VERSION ""

NS_ :

BS_:

BU_: Bat1 OpticalSensor EMUS_BMS SCIMO_PE TelemetryNode Master SensorF SensorR BrakeF BrakeR PDU HVCU HVTU TestBench MDB1 MDB2 MDB3 MDB4 MDB5 MDB6 Track CLU

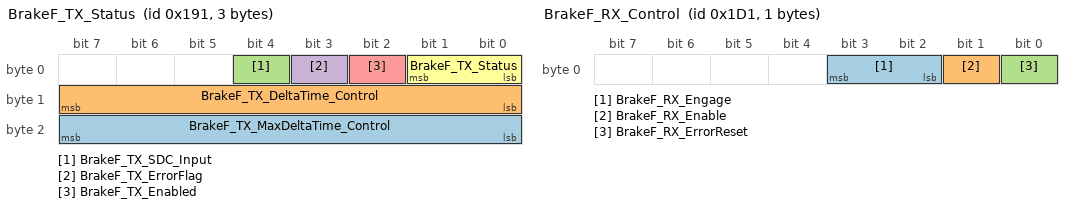
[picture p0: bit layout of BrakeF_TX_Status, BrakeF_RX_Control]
BO_ 401 BrakeF_TX_Status: 3 BrakeF
 SG_ BrakeF_TX_MaxDeltaTime_Control : 16|8@1+ (1,0) [0|255] "ms" Vector__XXX
 SG_ BrakeF_TX_DeltaTime_Control : 8|8@1+ (1,0) [0|255] "ms" Vector__XXX
 SG_ BrakeF_TX_SDC_Input : 4|1@1+ (1,0) [0|0] "" Vector__XXX
 SG_ BrakeF_TX_ErrorFlag : 3|1@1+ (1,0) [0|0] ""  SensorF
 SG_ BrakeF_TX_Enabled : 2|1@1+ (1,0) [0|0] ""  SensorF
 SG_ BrakeF_TX_Status : 0|2@1+ (1,0) [0|0] ""  SensorF

BO_ 465 BrakeF_RX_Control: 1 SensorF
 SG_ BrakeF_RX_Engage : 2|2@1+ (1,0) [0|0] "" Vector__XXX
 SG_ BrakeF_RX_Enable : 1|1@1+ (1,0) [0|0] "" Vector__XXX
 SG_ BrakeF_RX_ErrorReset : 0|1@1+ (1,0) [0|0] "" Vector__XXX

BO_ 529 BrakeF_TX_PDO2: 0 BrakeF

BO_ 593 BrakeF_RX_PDO2: 0 Vector__XXX

BO_ 657 BrakeF_TX_PDO3: 0 BrakeF

BO_ 721 BrakeF_RX_PDO3: 0 Vector__XXX

BO_ 785 BrakeF_TX_PDO4: 0 BrakeF

BO_ 849 BrakeF_RX_PDO4: 0 Vector__XXX

BO_ 913 BrakeF_TX_PDO5: 0 BrakeF

BO_ 977 BrakeF_TX_PDO6: 0 BrakeF

BO_ 1105 BrakeF_TX_PDO8: 0 BrakeF

BO_ 1169 BrakeF_TX_PDO9: 0 BrakeF

BO_ 1233 BrakeF_TX_PDO10: 0 BrakeF

BO_ 1297 BrakeF_TX_PDO11: 0 BrakeF

BO_ 1361 BrakeF_TX_PDO12: 0 BrakeF

BO_ 1425 BrakeF_SDO_Resp: 8 BrakeF
 SG_ BrakeF_OD_BrakeStatus m2304 : 16|8@1+ (1,0) [0|255] ""  TelemetryNode
 SG_ BrakeF_OD_CoolingPressure m2816 : 16|16@1+ (0.01,-100) [-100|555.35] ""  TelemetryNode
 SG_ BrakeF_OD_valveUpperTolerance m2053 : 16|16@1+ (0.005,0) [0|327.675] "bar"  TelemetryNode
 SG_ BrakeF_OD_commWatchdog m2052 : 16|16@1+ (1,0) [0|65535] "ms"  TelemetryNode
 SG_ BrakeF_OD_counterLimit m2051 : 16|8@1+ (1,0) [0|255] ""  TelemetryNode
 SG_ BrakeF_OD_delay m2050 : 16|8@1+ (0.5,0) [0|127.5] "ms"  TelemetryNode
 SG_ BrakeF_OD_tankUpperControlLimit m2049 : 16|16@1+ (0.005,0) [0|327.675] "bar"  TelemetryNode
 SG_ BrakeF_OD_tankLowerControlLimit m2048 : 16|16@1+ (0.005,0) [0|327.675] "bar"  TelemetryNode
 SG_ BrakeF_OD_CAN2_DelayedTxMessages m1129 : 16|24@1+ (1,0) [0|16777215] ""  TelemetryNode
 SG_ BrakeF_OD_CAN2_ErrorStatus m1128 : 16|8@1+ (1,0) [0|255] ""  TelemetryNode
 SG_ BrakeF_OD_CAN2_DiscardedTxMessag m1127 : 16|24@1+ (1,0) [0|16777215] ""  TelemetryNode
 SG_ BrakeF_OD_CAN2_Status m1126 : 16|8@1+ (1,0) [0|255] ""  TelemetryNode
 SG_ BrakeF_OD_CAN2_Baudrate m1124 : 16|16@1+ (1,0) [125|1000] "kbps"  TelemetryNode
 SG_ BrakeF_OD_CAN2_autoErrorReset m1123 : 16|8@1+ (1,0) [0|255] ""  TelemetryNode
 SG_ BrakeF_OD_CAN2_lastErrorCode m1122 : 16|32@1+ (1,0) [0|4294967295] ""  TelemetryNode
 SG_ BrakeF_OD_CAN2_RxErrCnt m1121 : 16|8@1+ (1,0) [0|255] ""  TelemetryNode
 SG_ BrakeF_OD_CAN2_TxErrCnt m1120 : 16|8@1+ (1,0) [0|255] ""  TelemetryNode
 SG_ BrakeF_OD_CAN1_DelayedTxMessages m1113 : 16|24@1+ (1,0) [0|16777215] ""  TelemetryNode
 SG_ BrakeF_OD_CAN1_ErrorStatus m1112 : 16|8@1+ (1,0) [0|255] ""  TelemetryNode
 SG_ BrakeF_OD_CAN1_DiscardedTxMessag m1111 : 16|24@1+ (1,0) [0|16777215] ""  TelemetryNode
 SG_ BrakeF_OD_CAN1_Status m1110 : 16|8@1+ (1,0) [0|255] ""  TelemetryNode
 SG_ BrakeF_OD_CAN1_Baudrate m1108 : 16|16@1+ (1,0) [125|1000] "kbps"  TelemetryNode
 SG_ BrakeF_OD_CAN1_autoErrorReset m1107 : 16|8@1+ (1,0) [0|255] ""  TelemetryNode
 SG_ BrakeF_OD_CAN1_lastErrorCode m1106 : 16|32@1+ (1,0) [0|4294967295] ""  TelemetryNode
 SG_ BrakeF_OD_CAN1_RxErrCnt m1105 : 16|8@1+ (1,0) [0|255] ""  TelemetryNode
 SG_ BrakeF_OD_CAN1_TxErrCnt m1104 : 16|8@1+ (1,0) [0|255] ""  TelemetryNode
 SG_ BrakeF_OD_BuildTime m1073 : 16|24@1+ (1,0) [0|16777215] ""  TelemetryNode
 SG_ BrakeF_OD_BuildDate m1072 : 16|32@1+ (1,0) [0|4294967295] ""  TelemetryNode
 SG_ BrakeF_OD_ChipUID2 m1057 : 16|48@1+ (1,0) [0|281474976710655] ""  TelemetryNode
 SG_ BrakeF_OD_ChipUID1 m1056 : 16|48@1+ (1,0) [0|281474976710655] ""  TelemetryNode
 SG_ BrakeF_OD_SdcOut m1046 : 16|8@1+ (1,0) [0|255] ""  TelemetryNode
 SG_ BrakeF_OD_SdcIn m1045 : 16|8@1+ (1,0) [0|255] ""  TelemetryNode
 SG_ BrakeF_OD_runtime m1044 : 16|24@1+ (1,0) [0|16777215] "ms"  TelemetryNode
 SG_ BrakeF_OD_InputVoltage m1043 : 16|16@1+ (0.001,0) [0|65.535] "V"  TelemetryNode
 SG_ BrakeF_OD_BoardTemp m1042 : 16|16@1+ (0.01,-30) [-30|625.35] "°C"  TelemetryNode
 SG_ BrakeF_OD_MemFree m1041 : 16|16@1+ (4,0) [0|262140] "bytes"  TelemetryNode
 SG_ BrakeF_OD_CpuUsage m1040 : 16|8@1+ (0.5,0) [0|100] "%"  TelemetryNode
 SG_ BrakeF_OD_OdEntrySendInterval m33 : 16|16@1+ (1,0) [0|65535] "ms"  TelemetryNode
 SG_ BrakeF_OD_SendOdOnBootup m32 : 16|8@1+ (1,0) [0|255] ""  TelemetryNode
 SG_ BrakeF_OD_HeartbeatInterval m16 : 16|16@1+ (1,0) [0|65535] "ms"  TelemetryNode
 SG_ BrakeF_OD_DbcVersion m5 : 16|16@1+ (1,0) [0|65535] ""  TelemetryNode
 SG_ BrakeF_OD_StackVersion m4 : 16|16@1+ (1,0) [0|65535] ""  TelemetryNode
 SG_ BrakeF_OD_ProtocolVersion m3 : 16|16@1+ (1,0) [0|65535] ""  TelemetryNode
 SG_ BrakeF_OD_NodeStatus m2 : 16|8@1+ (1,0) [0|255] ""  TelemetryNode
 SG_ BrakeF_OD_NodeID m1 : 16|8@1+ (1,0) [0|255] ""  TelemetryNode
 SG_ BrakeF_SDO_RespCode : 12|4@1+ (1,0) [0|0] ""  TelemetryNode
 SG_ BrakeF_SDO_ID M : 0|12@1+ (1,0) [0|4095] ""  TelemetryNode

BO_ 1489 BrakeF_SDO_Req_Up: 8 TelemetryNode
 SG_ BrakeF_OD_BrakeStatus m2304 : 16|8@1+ (1,0) [0|255] ""  BrakeF
 SG_ BrakeF_OD_CoolingPressure m2816 : 16|16@1+ (0.01,-100) [-100|555.35] ""  BrakeF
 SG_ BrakeF_OD_valveUpperTolerance m2053 : 16|16@1+ (0.005,0) [0|327.675] "bar"  BrakeF
 SG_ BrakeF_OD_commWatchdog m2052 : 16|16@1+ (1,0) [0|65535] "ms"  BrakeF
 SG_ BrakeF_OD_counterLimit m2051 : 16|8@1+ (1,0) [0|255] ""  BrakeF
 SG_ BrakeF_OD_delay m2050 : 16|8@1+ (0.5,0) [0|127.5] "ms"  BrakeF
 SG_ BrakeF_OD_tankUpperControlLimit m2049 : 16|16@1+ (0.005,0) [0|327.675] "bar"  BrakeF
 SG_ BrakeF_OD_tankLowerControlLimit m2048 : 16|16@1+ (0.005,0) [0|327.675] "bar"  BrakeF
 SG_ BrakeF_OD_CAN2_DelayedTxMessages m1129 : 16|24@1+ (1,0) [0|16777215] ""  BrakeF
 SG_ BrakeF_OD_CAN2_ErrorStatus m1128 : 16|8@1+ (1,0) [0|255] ""  BrakeF
 SG_ BrakeF_OD_CAN2_DiscardedTxM_0000 m1127 : 16|24@1+ (1,0) [0|16777215] ""  BrakeF
 SG_ BrakeF_OD_CAN2_Status m1126 : 16|8@1+ (1,0) [0|255] ""  BrakeF
 SG_ BrakeF_OD_CAN2_Baudrate m1124 : 16|16@1+ (1,0) [125|1000] "kbps"  BrakeF
 SG_ BrakeF_OD_CAN2_autoErrorReset m1123 : 16|8@1+ (1,0) [0|255] ""  BrakeF
 SG_ BrakeF_OD_CAN2_lastErrorCode m1122 : 16|32@1+ (1,0) [0|4294967295] ""  BrakeF
 SG_ BrakeF_OD_CAN2_RxErrCnt m1121 : 16|8@1+ (1,0) [0|255] ""  BrakeF
 SG_ BrakeF_OD_CAN2_TxErrCnt m1120 : 16|8@1+ (1,0) [0|255] ""  BrakeF
 SG_ BrakeF_OD_CAN1_DelayedTxMessages m1113 : 16|24@1+ (1,0) [0|16777215] ""  BrakeF
 SG_ BrakeF_OD_CAN1_ErrorStatus m1112 : 16|8@1+ (1,0) [0|255] ""  BrakeF
 SG_ BrakeF_OD_CAN1_DiscardedTxM_0000 m1111 : 16|24@1+ (1,0) [0|16777215] ""  BrakeF
 SG_ BrakeF_OD_CAN1_Status m1110 : 16|8@1+ (1,0) [0|255] ""  BrakeF
 SG_ BrakeF_OD_CAN1_Baudrate m1108 : 16|16@1+ (1,0) [125|1000] "kbps"  BrakeF
 SG_ BrakeF_OD_CAN1_autoErrorReset m1107 : 16|8@1+ (1,0) [0|255] ""  BrakeF
 SG_ BrakeF_OD_CAN1_lastErrorCode m1106 : 16|32@1+ (1,0) [0|4294967295] ""  BrakeF
 SG_ BrakeF_OD_CAN1_RxErrCnt m1105 : 16|8@1+ (1,0) [0|255] ""  BrakeF
 SG_ BrakeF_OD_CAN1_TxErrCnt m1104 : 16|8@1+ (1,0) [0|255] ""  BrakeF
 SG_ BrakeF_OD_BuildTime m1073 : 16|24@1+ (1,0) [0|16777215] ""  BrakeF
 SG_ BrakeF_OD_BuildDate m1072 : 16|32@1+ (1,0) [0|4294967295] ""  BrakeF
 SG_ BrakeF_OD_ChipUID2 m1057 : 16|48@1+ (1,0) [0|281474976710655] ""  BrakeF
 SG_ BrakeF_OD_ChipUID1 m1056 : 16|48@1+ (1,0) [0|281474976710655] ""  BrakeF
 SG_ BrakeF_OD_SdcOut m1046 : 16|8@1+ (1,0) [0|255] ""  BrakeF
 SG_ BrakeF_OD_SdcIn m1045 : 16|8@1+ (1,0) [0|255] ""  BrakeF
 SG_ BrakeF_OD_runtime m1044 : 16|24@1+ (1,0) [0|16777215] "ms"  BrakeF
 SG_ BrakeF_OD_InputVoltage m1043 : 16|16@1+ (0.001,0) [0|65.535] "V"  BrakeF
 SG_ BrakeF_OD_BoardTemp m1042 : 16|16@1+ (0.01,-30) [-30|625.35] "°C"  BrakeF
 SG_ BrakeF_OD_MemFree m1041 : 16|16@1+ (4,0) [0|262140] "bytes"  BrakeF
 SG_ BrakeF_OD_CpuUsage m1040 : 16|8@1+ (0.5,0) [0|100] "%"  BrakeF
 SG_ BrakeF_OD_OdEntrySendInterval m33 : 16|16@1+ (1,0) [0|65535] "ms"  BrakeF
 SG_ BrakeF_OD_SendOdOnBootup m32 : 16|8@1+ (1,0) [0|255] ""  BrakeF
 SG_ BrakeF_OD_HeartbeatInterval m16 : 16|16@1+ (1,0) [0|65535] "ms"  BrakeF
 SG_ BrakeF_OD_DbcVersion m5 : 16|16@1+ (1,0) [0|65535] ""  BrakeF
 SG_ BrakeF_OD_StackVersion m4 : 16|16@1+ (1,0) [0|65535] ""  BrakeF
 SG_ BrakeF_OD_ProtocolVersion m3 : 16|16@1+ (1,0) [0|65535] ""  BrakeF
 SG_ BrakeF_OD_NodeStatus m2 : 16|8@1+ (1,0) [0|255] ""  BrakeF
 SG_ BrakeF_OD_NodeID m1 : 16|8@1+ (1,0) [0|255] ""  BrakeF
 SG_ BrakeF_SDO_ID M : 0|12@1+ (1,0) [0|4095] ""  BrakeF

BO_ 1553 BrakeF_SDO_Req_Down: 2 TelemetryNode
 SG_ BrakeF_SDO_ID M : 0|12@1+ (1,0) [0|4095] ""  BrakeF

BO_ 1809 BrakeF_Heartbeat: 1 BrakeF
 SG_ BrakeF_NodeState : 0|8@1+ (1,0) [0|0] ""  SensorF,Master,TelemetryNode

BO_ 1873 BrakeF_BTL_TX: 8 BrakeF

BO_ 1937 BrakeF_BTL_RX: 8 TelemetryNode

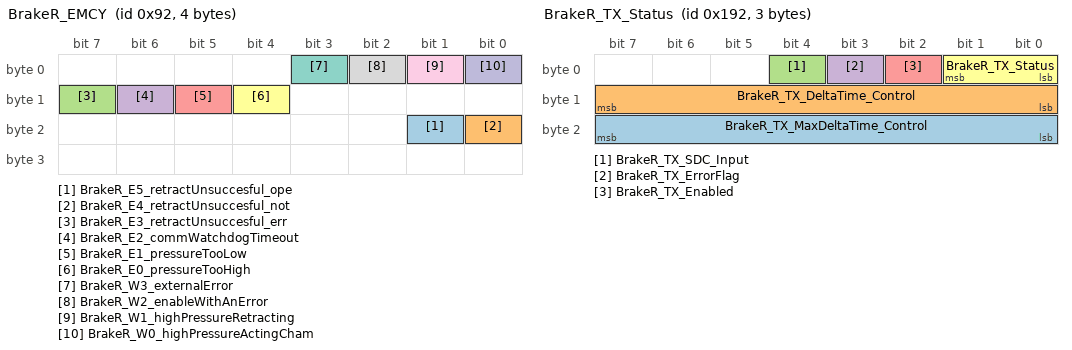
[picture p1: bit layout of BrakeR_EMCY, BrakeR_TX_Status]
BO_ 146 BrakeR_EMCY: 4 BrakeR
 SG_ BrakeR_E5_retractUnsuccesful_ope : 17|1@1+ (1,0) [0|0] ""  Master,TelemetryNode
 SG_ BrakeR_E4_retractUnsuccesful_not : 16|1@1+ (1,0) [0|0] ""  Master,TelemetryNode
 SG_ BrakeR_E3_retractUnsuccesful_err : 15|1@1+ (1,0) [0|0] ""  Master,TelemetryNode
 SG_ BrakeR_E2_commWatchdogTimeout : 14|1@1+ (1,0) [0|0] ""  Master,TelemetryNode
 SG_ BrakeR_E1_pressureTooLow : 13|1@1+ (1,0) [0|0] ""  Master,TelemetryNode
 SG_ BrakeR_E0_pressureTooHigh : 12|1@1+ (1,0) [0|0] ""  Master,TelemetryNode
 SG_ BrakeR_W3_externalError : 3|1@1+ (1,0) [0|0] ""  Master,TelemetryNode
 SG_ BrakeR_W2_enableWithAnError : 2|1@1+ (1,0) [0|0] ""  Master,TelemetryNode
 SG_ BrakeR_W1_highPressureRetracting : 1|1@1+ (1,0) [0|0] ""  Master,TelemetryNode
 SG_ BrakeR_W0_highPressureActingCham : 0|1@1+ (1,0) [0|0] ""  Master,TelemetryNode

BO_ 402 BrakeR_TX_Status: 3 BrakeR
 SG_ BrakeR_TX_MaxDeltaTime_Control : 16|8@1+ (1,0) [0|255] "ms" Vector__XXX
 SG_ BrakeR_TX_DeltaTime_Control : 8|8@1+ (1,0) [0|255] "ms" Vector__XXX
 SG_ BrakeR_TX_SDC_Input : 4|1@1+ (1,0) [0|0] "" Vector__XXX
 SG_ BrakeR_TX_ErrorFlag : 3|1@1+ (1,0) [0|0] "" Vector__XXX
 SG_ BrakeR_TX_Enabled : 2|1@1+ (1,0) [0|0] "" Vector__XXX
 SG_ BrakeR_TX_Status : 0|2@1+ (1,0) [0|0] "" Vector__XXX

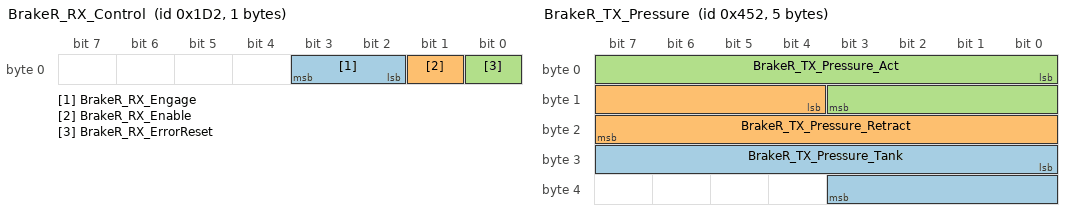
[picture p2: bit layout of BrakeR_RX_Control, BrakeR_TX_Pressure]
BO_ 466 BrakeR_RX_Control: 1 SensorF
 SG_ BrakeR_RX_Engage : 2|2@1+ (1,0) [0|0] "" Vector__XXX
 SG_ BrakeR_RX_Enable : 1|1@1+ (1,0) [0|0] "" Vector__XXX
 SG_ BrakeR_RX_ErrorReset : 0|1@1+ (1,0) [0|0] "" Vector__XXX

BO_ 530 BrakeR_TX_PDO2: 0 BrakeR

BO_ 594 BrakeR_RX_PDO2: 0 Vector__XXX

BO_ 658 BrakeR_TX_PDO3: 0 BrakeR

BO_ 722 BrakeR_RX_PDO3: 0 Vector__XXX

BO_ 786 BrakeR_TX_PDO4: 0 BrakeR

BO_ 850 BrakeR_RX_PDO4: 0 Vector__XXX

BO_ 914 BrakeR_TX_PDO5: 0 BrakeR

BO_ 978 BrakeR_TX_PDO6: 0 BrakeR

BO_ 1042 BrakeR_TX_PDO7: 0 BrakeR

BO_ 1106 BrakeR_TX_Pressure: 5 BrakeR
 SG_ BrakeR_TX_Pressure_Tank : 24|12@1+ (0.005,-2) [-2|18.475] "bar" Vector__XXX
 SG_ BrakeR_TX_Pressure_Retract : 12|12@1+ (0.005,-2) [-2|18.475] "bar" Vector__XXX
 SG_ BrakeR_TX_Pressure_Act : 0|12@1+ (0.005,-2) [-2|18.475] "bar" Vector__XXX

BO_ 1170 BrakeR_TX_PDO9: 0 BrakeR

BO_ 1234 BrakeR_TX_PDO10: 0 BrakeR

BO_ 1298 BrakeR_TX_PDO11: 0 BrakeR

BO_ 1362 BrakeR_TX_PDO12: 0 BrakeR

BO_ 1426 BrakeR_SDO_Resp: 8 BrakeR
 SG_ BrakeR_OD_valveUpperTolerance m2053 : 16|16@1+ (0.005,0) [0|327.675] "bar"  TelemetryNode
 SG_ BrakeR_OD_commWatchdog m2052 : 16|16@1+ (1,0) [0|65535] "ms"  TelemetryNode
 SG_ BrakeR_OD_counterLimit m2051 : 16|8@1+ (1,0) [0|255] ""  TelemetryNode
 SG_ BrakeR_OD_delay m2050 : 16|8@1+ (0.5,0) [0|127.5] "ms"  TelemetryNode
 SG_ BrakeR_OD_tankUpperControlLimit m2049 : 16|16@1+ (0.005,0) [0|327.675] "bar"  TelemetryNode
 SG_ BrakeR_OD_tankLowerControlLimit m2048 : 16|16@1+ (0.005,0) [0|327.675] "bar"  TelemetryNode
 SG_ BrakeR_OD_CAN2_DelayedTxMessages m1129 : 16|24@1+ (1,0) [0|16777215] ""  TelemetryNode
 SG_ BrakeR_OD_CAN2_ErrorStatus m1128 : 16|8@1+ (1,0) [0|255] ""  TelemetryNode
 SG_ BrakeR_OD_CAN2_DiscardedTxMessag m1127 : 16|24@1+ (1,0) [0|16777215] ""  TelemetryNode
 SG_ BrakeR_OD_CAN2_Status m1126 : 16|8@1+ (1,0) [0|255] ""  TelemetryNode
 SG_ BrakeR_OD_CAN2_Baudrate m1124 : 16|16@1+ (1,0) [125|1000] "kbps"  TelemetryNode
 SG_ BrakeR_OD_CAN2_autoErrorReset m1123 : 16|8@1+ (1,0) [0|255] ""  TelemetryNode
 SG_ BrakeR_OD_CAN2_lastErrorCode m1122 : 16|32@1+ (1,0) [0|4294967295] ""  TelemetryNode
 SG_ BrakeR_OD_CAN2_RxErrCnt m1121 : 16|8@1+ (1,0) [0|255] ""  TelemetryNode
 SG_ BrakeR_OD_CAN2_TxErrCnt m1120 : 16|8@1+ (1,0) [0|255] ""  TelemetryNode
 SG_ BrakeR_OD_CAN1_DelayedTxMessages m1113 : 16|24@1+ (1,0) [0|16777215] ""  TelemetryNode
 SG_ BrakeR_OD_CAN1_ErrorStatus m1112 : 16|8@1+ (1,0) [0|255] ""  TelemetryNode
 SG_ BrakeR_OD_CAN1_DiscardedTxMessag m1111 : 16|24@1+ (1,0) [0|16777215] ""  TelemetryNode
 SG_ BrakeR_OD_CAN1_Status m1110 : 16|8@1+ (1,0) [0|255] ""  TelemetryNode
 SG_ BrakeR_OD_CAN1_Baudrate m1108 : 16|16@1+ (1,0) [125|1000] "kbps"  TelemetryNode
 SG_ BrakeR_OD_CAN1_autoErrorReset m1107 : 16|8@1+ (1,0) [0|255] ""  TelemetryNode
 SG_ BrakeR_OD_CAN1_lastErrorCode m1106 : 16|32@1+ (1,0) [0|4294967295] ""  TelemetryNode
 SG_ BrakeR_OD_CAN1_RxErrCnt m1105 : 16|8@1+ (1,0) [0|255] ""  TelemetryNode
 SG_ BrakeR_OD_CAN1_TxErrCnt m1104 : 16|8@1+ (1,0) [0|255] ""  TelemetryNode
 SG_ BrakeR_OD_BuildTime m1073 : 16|24@1+ (1,0) [0|16777215] ""  TelemetryNode
 SG_ BrakeR_OD_BuildDate m1072 : 16|32@1+ (1,0) [0|4294967295] ""  TelemetryNode
 SG_ BrakeR_OD_ChipUID2 m1057 : 16|48@1+ (1,0) [0|281474976710655] ""  TelemetryNode
 SG_ BrakeR_OD_ChipUID1 m1056 : 16|48@1+ (1,0) [0|281474976710655] ""  TelemetryNode
 SG_ BrakeR_OD_SdcOut m1046 : 16|8@1+ (1,0) [0|255] ""  TelemetryNode
 SG_ BrakeR_OD_SdcIn m1045 : 16|8@1+ (1,0) [0|255] ""  TelemetryNode
 SG_ BrakeR_OD_runtime m1044 : 16|24@1+ (1,0) [0|16777215] "ms"  TelemetryNode
 SG_ BrakeR_OD_InputVoltage m1043 : 16|16@1+ (0.001,0) [0|65.535] "V"  TelemetryNode
 SG_ BrakeR_OD_BoardTemp m1042 : 16|16@1+ (0.01,-30) [-30|625.35] "°C"  TelemetryNode
 SG_ BrakeR_OD_MemFree m1041 : 16|16@1+ (4,0) [0|262140] "bytes"  TelemetryNode
 SG_ BrakeR_OD_CpuUsage m1040 : 16|8@1+ (0.5,0) [0|100] "%"  TelemetryNode
 SG_ BrakeR_OD_OdEntrySendInterval m33 : 16|16@1+ (1,0) [0|65535] "ms"  TelemetryNode
 SG_ BrakeR_OD_SendOdOnBootup m32 : 16|8@1+ (1,0) [0|255] ""  TelemetryNode
 SG_ BrakeR_OD_HeartbeatInterval m16 : 16|16@1+ (1,0) [0|65535] "ms"  TelemetryNode
 SG_ BrakeR_OD_DbcVersion m5 : 16|16@1+ (1,0) [0|65535] ""  TelemetryNode
 SG_ BrakeR_OD_StackVersion m4 : 16|16@1+ (1,0) [0|65535] ""  TelemetryNode
 SG_ BrakeR_OD_ProtocolVersion m3 : 16|16@1+ (1,0) [0|65535] ""  TelemetryNode
 SG_ BrakeR_OD_NodeStatus m2 : 16|8@1+ (1,0) [0|255] ""  TelemetryNode
 SG_ BrakeR_OD_NodeID m1 : 16|8@1+ (1,0) [0|255] ""  TelemetryNode
 SG_ BrakeR_SDO_RespCode : 12|4@1+ (1,0) [0|0] ""  TelemetryNode
 SG_ BrakeR_SDO_ID M : 0|12@1+ (1,0) [0|4095] ""  TelemetryNode

BO_ 1490 BrakeR_SDO_Req_Up: 8 TelemetryNode
 SG_ BrakeR_OD_valveUpperTolerance m2053 : 16|16@1+ (0.005,0) [0|327.675] "bar"  BrakeR
 SG_ BrakeR_OD_commWatchdog m2052 : 16|16@1+ (1,0) [0|65535] "ms"  BrakeR
 SG_ BrakeR_OD_counterLimit m2051 : 16|8@1+ (1,0) [0|255] ""  BrakeR
 SG_ BrakeR_OD_delay m2050 : 16|8@1+ (0.5,0) [0|127.5] "ms"  BrakeR
 SG_ BrakeR_OD_tankUpperControlLimit m2049 : 16|16@1+ (0.005,0) [0|327.675] "bar"  BrakeR
 SG_ BrakeR_OD_tankLowerControlLimit m2048 : 16|16@1+ (0.005,0) [0|327.675] "bar"  BrakeR
 SG_ BrakeR_OD_CAN2_DelayedTxMessages m1129 : 16|24@1+ (1,0) [0|16777215] ""  BrakeR
 SG_ BrakeR_OD_CAN2_ErrorStatus m1128 : 16|8@1+ (1,0) [0|255] ""  BrakeR
 SG_ BrakeR_OD_CAN2_DiscardedTxM_0000 m1127 : 16|24@1+ (1,0) [0|16777215] ""  BrakeR
 SG_ BrakeR_OD_CAN2_Status m1126 : 16|8@1+ (1,0) [0|255] ""  BrakeR
 SG_ BrakeR_OD_CAN2_Baudrate m1124 : 16|16@1+ (1,0) [125|1000] "kbps"  BrakeR
 SG_ BrakeR_OD_CAN2_autoErrorReset m1123 : 16|8@1+ (1,0) [0|255] ""  BrakeR
 SG_ BrakeR_OD_CAN2_lastErrorCode m1122 : 16|32@1+ (1,0) [0|4294967295] ""  BrakeR
 SG_ BrakeR_OD_CAN2_RxErrCnt m1121 : 16|8@1+ (1,0) [0|255] ""  BrakeR
 SG_ BrakeR_OD_CAN2_TxErrCnt m1120 : 16|8@1+ (1,0) [0|255] ""  BrakeR
 SG_ BrakeR_OD_CAN1_DelayedTxMessages m1113 : 16|24@1+ (1,0) [0|16777215] ""  BrakeR
 SG_ BrakeR_OD_CAN1_ErrorStatus m1112 : 16|8@1+ (1,0) [0|255] ""  BrakeR
 SG_ BrakeR_OD_CAN1_DiscardedTxM_0000 m1111 : 16|24@1+ (1,0) [0|16777215] ""  BrakeR
 SG_ BrakeR_OD_CAN1_Status m1110 : 16|8@1+ (1,0) [0|255] ""  BrakeR
 SG_ BrakeR_OD_CAN1_Baudrate m1108 : 16|16@1+ (1,0) [125|1000] "kbps"  BrakeR
 SG_ BrakeR_OD_CAN1_autoErrorReset m1107 : 16|8@1+ (1,0) [0|255] ""  BrakeR
 SG_ BrakeR_OD_CAN1_lastErrorCode m1106 : 16|32@1+ (1,0) [0|4294967295] ""  BrakeR
 SG_ BrakeR_OD_CAN1_RxErrCnt m1105 : 16|8@1+ (1,0) [0|255] ""  BrakeR
 SG_ BrakeR_OD_CAN1_TxErrCnt m1104 : 16|8@1+ (1,0) [0|255] ""  BrakeR
 SG_ BrakeR_OD_BuildTime m1073 : 16|24@1+ (1,0) [0|16777215] ""  BrakeR
 SG_ BrakeR_OD_BuildDate m1072 : 16|32@1+ (1,0) [0|4294967295] ""  BrakeR
 SG_ BrakeR_OD_ChipUID2 m1057 : 16|48@1+ (1,0) [0|281474976710655] ""  BrakeR
 SG_ BrakeR_OD_ChipUID1 m1056 : 16|48@1+ (1,0) [0|281474976710655] ""  BrakeR
 SG_ BrakeR_OD_SdcOut m1046 : 16|8@1+ (1,0) [0|255] ""  BrakeR
 SG_ BrakeR_OD_SdcIn m1045 : 16|8@1+ (1,0) [0|255] ""  BrakeR
 SG_ BrakeR_OD_runtime m1044 : 16|24@1+ (1,0) [0|16777215] "ms"  BrakeR
 SG_ BrakeR_OD_InputVoltage m1043 : 16|16@1+ (0.001,0) [0|65.535] "V"  BrakeR
 SG_ BrakeR_OD_BoardTemp m1042 : 16|16@1+ (0.01,-30) [-30|625.35] "°C"  BrakeR
 SG_ BrakeR_OD_MemFree m1041 : 16|16@1+ (4,0) [0|262140] "bytes"  BrakeR
 SG_ BrakeR_OD_CpuUsage m1040 : 16|8@1+ (0.5,0) [0|100] "%"  BrakeR
 SG_ BrakeR_OD_OdEntrySendInterval m33 : 16|16@1+ (1,0) [0|65535] "ms"  BrakeR
 SG_ BrakeR_OD_SendOdOnBootup m32 : 16|8@1+ (1,0) [0|255] ""  BrakeR
 SG_ BrakeR_OD_HeartbeatInterval m16 : 16|16@1+ (1,0) [0|65535] "ms"  BrakeR
 SG_ BrakeR_OD_DbcVersion m5 : 16|16@1+ (1,0) [0|65535] ""  BrakeR
 SG_ BrakeR_OD_StackVersion m4 : 16|16@1+ (1,0) [0|65535] ""  BrakeR
 SG_ BrakeR_OD_ProtocolVersion m3 : 16|16@1+ (1,0) [0|65535] ""  BrakeR
 SG_ BrakeR_OD_NodeStatus m2 : 16|8@1+ (1,0) [0|255] ""  BrakeR
 SG_ BrakeR_OD_NodeID m1 : 16|8@1+ (1,0) [0|255] ""  BrakeR
 SG_ BrakeR_SDO_ID M : 0|12@1+ (1,0) [0|4095] ""  BrakeR

BO_ 1554 BrakeR_SDO_Req_Down: 2 TelemetryNode
 SG_ BrakeR_SDO_ID M : 0|12@1+ (1,0) [0|4095] ""  BrakeR

BO_ 1810 BrakeR_Heartbeat: 1 BrakeR
 SG_ BrakeR_NodeState : 0|8@1+ (1,0) [0|0] ""  Master,TelemetryNode

BO_ 1874 BrakeR_BTL_TX: 8 BrakeR

BO_ 1938 BrakeR_BTL_RX: 8 TelemetryNode

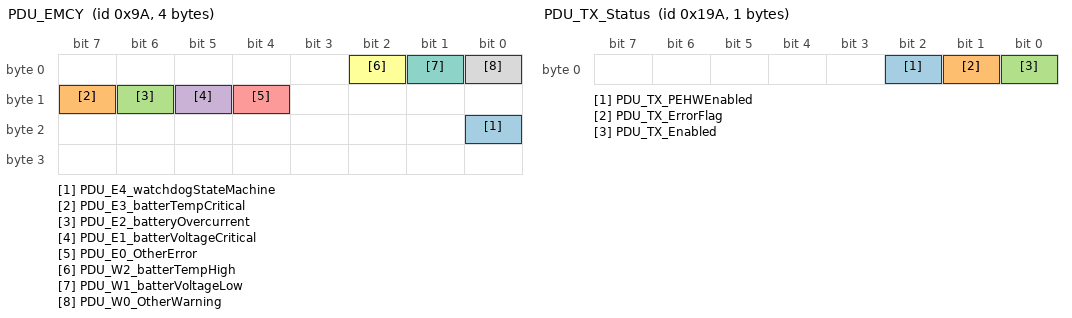
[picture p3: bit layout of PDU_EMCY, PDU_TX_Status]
BO_ 154 PDU_EMCY: 4 PDU
 SG_ PDU_E4_watchdogStateMachine : 16|1@1+ (1,0) [0|0] ""  Master,TelemetryNode
 SG_ PDU_E3_batterTempCritical : 15|1@1+ (1,0) [0|0] ""  Master,TelemetryNode
 SG_ PDU_E2_batteryOvercurrent : 14|1@1+ (1,0) [0|0] ""  Master,TelemetryNode
 SG_ PDU_E1_batterVoltageCritical : 13|1@1+ (1,0) [0|0] ""  Master,TelemetryNode
 SG_ PDU_E0_OtherError : 12|1@1+ (1,0) [0|0] ""  Master,TelemetryNode
 SG_ PDU_W2_batterTempHigh : 2|1@1+ (1,0) [0|0] ""  Master,TelemetryNode
 SG_ PDU_W1_batterVoltageLow : 1|1@1+ (1,0) [0|0] ""  Master,TelemetryNode
 SG_ PDU_W0_OtherWarning : 0|1@1+ (1,0) [0|0] ""  Master,TelemetryNode

BO_ 410 PDU_TX_Status: 1 PDU
 SG_ PDU_TX_PEHWEnabled : 2|1@1+ (1,0) [0|0] ""  SensorF
 SG_ PDU_TX_ErrorFlag : 1|1@1+ (1,0) [0|0] ""  SensorF
 SG_ PDU_TX_Enabled : 0|1@1+ (1,0) [0|0] ""  SensorF

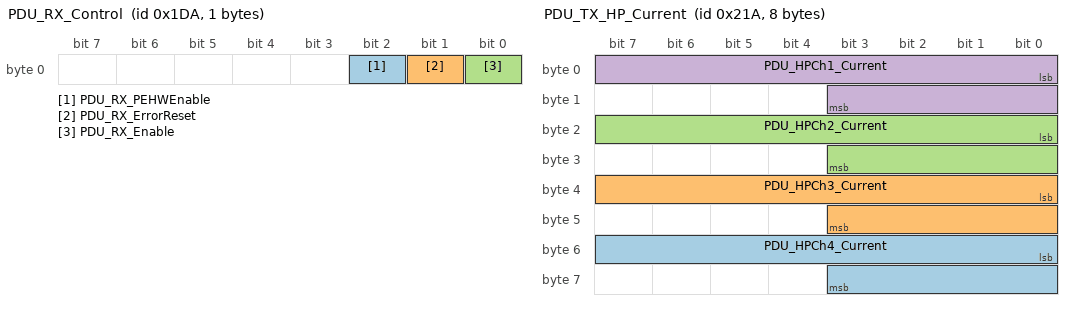
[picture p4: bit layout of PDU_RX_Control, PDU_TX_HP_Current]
BO_ 474 PDU_RX_Control: 1 SensorF
 SG_ PDU_RX_PEHWEnable : 2|1@1+ (1,0) [0|0] ""  PDU
 SG_ PDU_RX_ErrorReset : 1|1@1+ (1,0) [0|0] ""  PDU
 SG_ PDU_RX_Enable : 0|1@1+ (1,0) [0|0] ""  PDU

BO_ 538 PDU_TX_HP_Current: 8 PDU
 SG_ PDU_HPCh4_Current : 48|12@1+ (0.004,0) [0|16.38] "A"  SensorF
 SG_ PDU_HPCh3_Current : 32|12@1+ (0.004,0) [0|16.38] "A"  SensorF
 SG_ PDU_HPCh2_Current : 16|12@1+ (0.004,0) [0|16.38] "A"  SensorF
 SG_ PDU_HPCh1_Current : 0|12@1+ (0.004,0) [0|16.38] "A"  SensorF

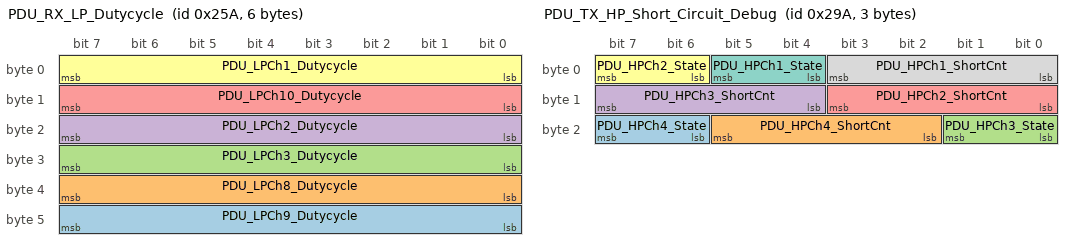
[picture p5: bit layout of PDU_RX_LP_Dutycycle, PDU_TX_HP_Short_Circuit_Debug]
BO_ 602 PDU_RX_LP_Dutycycle: 6 SensorF
 SG_ PDU_LPCh9_Dutycycle : 40|8@1+ (0.5,0) [0|100] "%" Vector__XXX
 SG_ PDU_LPCh8_Dutycycle : 32|8@1+ (0.5,0) [0|100] "%" Vector__XXX
 SG_ PDU_LPCh3_Dutycycle : 24|8@1+ (0.5,0) [0|100] "%" Vector__XXX
 SG_ PDU_LPCh2_Dutycycle : 16|8@1+ (0.5,0) [0|100] "%" Vector__XXX
 SG_ PDU_LPCh10_Dutycycle : 8|8@1+ (0.5,0) [0|100] "%" Vector__XXX
 SG_ PDU_LPCh1_Dutycycle : 0|8@1+ (0.5,0) [0|100] "%" Vector__XXX

BO_ 666 PDU_TX_HP_Short_Circuit_Debug: 3 PDU
 SG_ PDU_HPCh4_State : 22|2@1+ (1,0) [0|3] "" Vector__XXX
 SG_ PDU_HPCh4_ShortCnt : 18|4@1+ (1,0) [0|15] "" Vector__XXX
 SG_ PDU_HPCh3_State : 16|2@1+ (1,0) [0|3] "" Vector__XXX
 SG_ PDU_HPCh3_ShortCnt : 12|4@1+ (1,0) [0|15] "" Vector__XXX
 SG_ PDU_HPCh2_ShortCnt : 8|4@1+ (1,0) [0|15] "" Vector__XXX
 SG_ PDU_HPCh2_State : 6|2@1+ (1,0) [0|3] "" Vector__XXX
 SG_ PDU_HPCh1_State : 4|2@1+ (1,0) [0|3] "" Vector__XXX
 SG_ PDU_HPCh1_ShortCnt : 0|4@1+ (1,0) [0|15] "" Vector__XXX

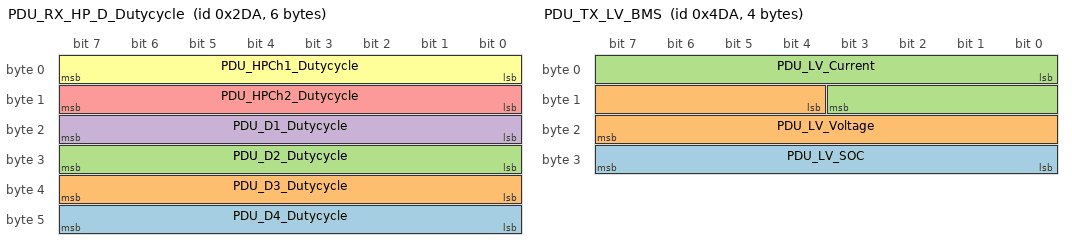
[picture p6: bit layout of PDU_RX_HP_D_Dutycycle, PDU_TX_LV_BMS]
BO_ 730 PDU_RX_HP_D_Dutycycle: 6 SensorF
 SG_ PDU_D4_Dutycycle : 40|8@1+ (0.5,0) [0|100] "%" Vector__XXX
 SG_ PDU_D3_Dutycycle : 32|8@1+ (0.5,0) [0|100] "%" Vector__XXX
 SG_ PDU_D2_Dutycycle : 24|8@1+ (0.5,0) [0|100] "%" Vector__XXX
 SG_ PDU_D1_Dutycycle : 16|8@1+ (0.5,0) [0|100] "%" Vector__XXX
 SG_ PDU_HPCh2_Dutycycle : 8|8@1+ (0.5,0) [0|100] "%" Vector__XXX
 SG_ PDU_HPCh1_Dutycycle : 0|8@1+ (0.5,0) [0|100] "%" Vector__XXX

BO_ 794 PDU_TX_PDO4: 0 PDU

BO_ 858 PDU_RX_Manual_Control: 3 Vector__XXX
 SG_ PDU_SDC_Enable : 18|1@1+ (1,0) [0|0] "" Vector__XXX
 SG_ PDU_D4_Enable : 17|1@1+ (1,0) [0|1] "" Vector__XXX
 SG_ PDU_D3_Enable : 16|1@1+ (1,0) [0|1] "" Vector__XXX
 SG_ PDU_D2_Enable : 15|1@1+ (1,0) [0|1] "" Vector__XXX
 SG_ PDU_D1_Enable : 14|1@1+ (1,0) [0|1] "" Vector__XXX
 SG_ PDU_HPCh4_Enable : 13|1@1+ (1,0) [0|1] "" Vector__XXX
 SG_ PDU_HPCh3_Enable : 12|1@1+ (1,0) [0|1] "" Vector__XXX
 SG_ PDU_HPCh2_Enable : 11|1@1+ (1,0) [0|1] "" Vector__XXX
 SG_ PDU_HPCh1_Enable : 10|1@1+ (1,0) [0|1] "" Vector__XXX
 SG_ PDU_LPCh10_Enable : 9|1@1+ (1,0) [0|1] "" Vector__XXX
 SG_ PDU_LPCh9_Enable : 8|1@1+ (1,0) [0|1] "" Vector__XXX
 SG_ PDU_LPCh8_Enable : 7|1@1+ (1,0) [0|1] "" Vector__XXX
 SG_ PDU_LPCh7_Enable : 6|1@1+ (1,0) [0|1] "" Vector__XXX
 SG_ PDU_LPCh6_Enable : 5|1@1+ (1,0) [0|1] "" Vector__XXX
 SG_ PDU_LPCh5_Enable : 4|1@1+ (1,0) [0|1] "" Vector__XXX
 SG_ PDU_LPCh4_Enable : 3|1@1+ (1,0) [0|1] "" Vector__XXX
 SG_ PDU_LPCh3_Enable : 2|1@1+ (1,0) [0|1] "" Vector__XXX
 SG_ PDU_LPCh2_Enable : 1|1@1+ (1,0) [0|1] "" Vector__XXX
 SG_ PDU_LPCh1_Enable : 0|1@1+ (1,0) [0|1] "" Vector__XXX

BO_ 922 PDU_TX_PDO5: 0 PDU

BO_ 986 PDU_TX_PDO6: 0 PDU

BO_ 1050 PDU_TX_PDO7: 0 PDU

BO_ 1114 PDU_TX_PDO8: 0 PDU

BO_ 1178 PDU_TX_LP_Short_Circuit_Debug: 8 PDU
 SG_ PDU_LPCh9_State : 58|2@1+ (1,0) [0|3] "" Vector__XXX
 SG_ PDU_LPCh8_State : 56|2@1+ (1,0) [0|3] "" Vector__XXX
 SG_ PDU_LPCh7_State : 54|2@1+ (1,0) [0|3] "" Vector__XXX
 SG_ PDU_LPCh6_State : 52|2@1+ (1,0) [0|3] "" Vector__XXX
 SG_ PDU_LPCh5_State : 50|2@1+ (1,0) [0|3] "" Vector__XXX
 SG_ PDU_LPCh4_State : 48|2@1+ (1,0) [0|3] "" Vector__XXX
 SG_ PDU_LPCh3_State : 46|2@1+ (1,0) [0|3] "" Vector__XXX
 SG_ PDU_LPCh2_State : 44|2@1+ (1,0) [0|3] "" Vector__XXX
 SG_ PDU_LPCh1_State : 42|2@1+ (1,0) [0|3] "" Vector__XXX
 SG_ PDU_LPCh10_State : 40|2@1+ (1,0) [0|3] "" Vector__XXX
 SG_ PDU_LPCh9_ShortCnt : 36|4@1+ (1,0) [0|15] "" Vector__XXX
 SG_ PDU_LPCh8_ShortCnt : 32|4@1+ (1,0) [0|15] "" Vector__XXX
 SG_ PDU_LPCh7_ShortCnt : 28|4@1+ (1,0) [0|15] "" Vector__XXX
 SG_ PDU_LPCh6_ShortCnt : 24|4@1+ (1,0) [0|15] "" Vector__XXX
 SG_ PDU_LPCh5_ShortCnt : 20|4@1+ (1,0) [0|15] "" Vector__XXX
 SG_ PDU_LPCh4_ShortCnt : 16|4@1+ (1,0) [0|15] "" Vector__XXX
 SG_ PDU_LPCh3_ShortCnt : 12|4@1+ (1,0) [0|15] "" Vector__XXX
 SG_ PDU_LPCh2_ShortCnt : 8|4@1+ (1,0) [0|15] "" Vector__XXX
 SG_ PDU_LPCh1_ShortCnt : 4|4@1+ (1,0) [0|15] "" Vector__XXX
 SG_ PDU_LPCh10_ShortCnt : 0|4@1+ (1,0) [0|15] "" Vector__XXX

BO_ 1242 PDU_TX_LV_BMS: 4 PDU
 SG_ PDU_LV_SOC : 24|8@1- (1,0) [0|100] "%" Vector__XXX
 SG_ PDU_LV_Voltage : 12|12@1+ (0.01,0) [0|40.95] "V" Vector__XXX
 SG_ PDU_LV_Current : 0|12@1+ (0.01,0) [0|40.95] "A" Vector__XXX

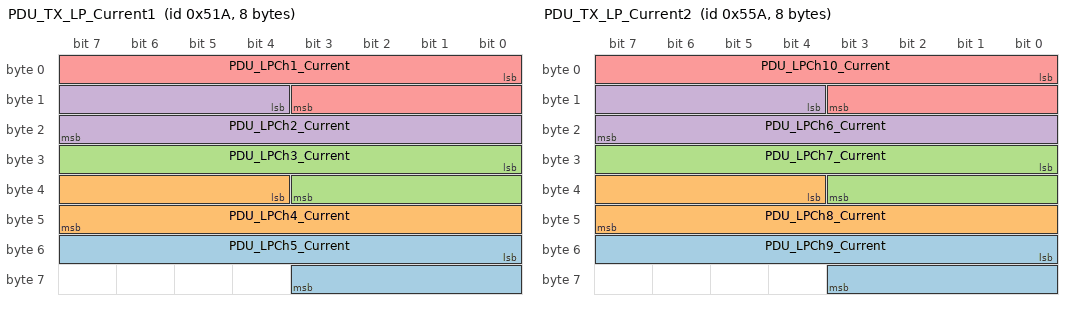
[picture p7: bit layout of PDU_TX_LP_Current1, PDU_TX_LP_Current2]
BO_ 1306 PDU_TX_LP_Current1: 8 PDU
 SG_ PDU_LPCh5_Current : 48|12@1+ (0.002,0) [0|8.19] "A"  SensorF
 SG_ PDU_LPCh4_Current : 36|12@1+ (0.002,0) [0|8.19] "A"  SensorF
 SG_ PDU_LPCh3_Current : 24|12@1+ (0.002,0) [0|8.19] "A"  SensorF
 SG_ PDU_LPCh2_Current : 12|12@1+ (0.002,0) [0|8.19] "A"  SensorF
 SG_ PDU_LPCh1_Current : 0|12@1+ (0.002,0) [0|8.19] "A"  SensorF

BO_ 1370 PDU_TX_LP_Current2: 8 PDU
 SG_ PDU_LPCh9_Current : 48|12@1+ (0.002,0) [0|8.19] "A"  SensorF
 SG_ PDU_LPCh8_Current : 36|12@1+ (0.002,0) [0|8.19] "A"  SensorF
 SG_ PDU_LPCh7_Current : 24|12@1+ (0.002,0) [0|8.19] "A"  SensorF
 SG_ PDU_LPCh6_Current : 12|12@1+ (0.002,0) [0|8.19] "A"  SensorF
 SG_ PDU_LPCh10_Current : 0|12@1+ (0.002,0) [0|8.19] "A"  SensorF

BO_ 1434 PDU_SDO_Resp: 8 PDU
 SG_ PDU_OD_CoolingPumpEnabled m2816 : 16|8@1+ (1,0) [0|255] ""  TelemetryNode
 SG_ PDU_OD_LedCommands m2562 : 16|16@1+ (1,0) [0|65535] ""  TelemetryNode
 SG_ PDU_OD_projectXXEnabled m2560 : 16|8@1+ (1,0) [0|255] ""  TelemetryNode
 SG_ PDU_OD_watchdogTimeout m2306 : 16|16@1+ (1,0) [0|65535] "ms"  TelemetryNode
 SG_ PDU_OD_statusSendInterval m2305 : 16|16@1+ (1,0) [0|65535] "ms"  TelemetryNode
 SG_ PDU_OD_currentReadInterval m2304 : 16|16@1+ (1,0) [0|65535] "ms"  TelemetryNode
 SG_ PDU_OD_batteryOvercurrent m2128 : 16|16@1+ (0.01,0) [0|655.35] "A"  TelemetryNode
 SG_ PDU_OD_overTempCritical m2051 : 16|16@1+ (0.1,0) [0|6553.5] "degrees"  TelemetryNode
 SG_ PDU_OD_overTempWarn m2050 : 16|16@1+ (0.1,0) [0|6553.5] "degrees"  TelemetryNode
 SG_ PDU_OD_batterVoltageCritical m2049 : 16|16@1+ (0.01,0) [0|655.35] "V"  TelemetryNode
 SG_ PDU_OD_batterVoltageLow m2048 : 16|16@1+ (0.01,0) [0|655.35] "V"  TelemetryNode
 SG_ PDU_OD_CAN2_DelayedTxMessages m1129 : 16|24@1+ (1,0) [0|16777215] ""  TelemetryNode
 SG_ PDU_OD_CAN2_ErrorStatus m1128 : 16|8@1+ (1,0) [0|255] ""  TelemetryNode
 SG_ PDU_OD_CAN2_DiscardedTxMessages m1127 : 16|24@1+ (1,0) [0|16777215] ""  TelemetryNode
 SG_ PDU_OD_CAN2_Status m1126 : 16|8@1+ (1,0) [0|255] ""  TelemetryNode
 SG_ PDU_OD_CAN2_Baudrate m1124 : 16|16@1+ (1,0) [125|1000] "kbps"  TelemetryNode
 SG_ PDU_OD_CAN2_autoErrorReset m1123 : 16|8@1+ (1,0) [0|255] ""  TelemetryNode
 SG_ PDU_OD_CAN2_lastErrorCode m1122 : 16|32@1+ (1,0) [0|4294967295] ""  TelemetryNode
 SG_ PDU_OD_CAN2_RxErrCnt m1121 : 16|8@1+ (1,0) [0|255] ""  TelemetryNode
 SG_ PDU_OD_CAN2_TxErrCnt m1120 : 16|8@1+ (1,0) [0|255] ""  TelemetryNode
 SG_ PDU_OD_CAN1_DelayedTxMessages m1113 : 16|24@1+ (1,0) [0|16777215] ""  TelemetryNode
 SG_ PDU_OD_CAN1_ErrorStatus m1112 : 16|8@1+ (1,0) [0|255] ""  TelemetryNode
 SG_ PDU_OD_CAN1_DiscardedTxMessages m1111 : 16|24@1+ (1,0) [0|16777215] ""  TelemetryNode
 SG_ PDU_OD_CAN1_Status m1110 : 16|8@1+ (1,0) [0|255] ""  TelemetryNode
 SG_ PDU_OD_CAN1_Baudrate m1108 : 16|16@1+ (1,0) [125|1000] "kbps"  TelemetryNode
 SG_ PDU_OD_CAN1_autoErrorReset m1107 : 16|8@1+ (1,0) [0|255] ""  TelemetryNode
 SG_ PDU_OD_CAN1_lastErrorCode m1106 : 16|32@1+ (1,0) [0|4294967295] ""  TelemetryNode
 SG_ PDU_OD_CAN1_RxErrCnt m1105 : 16|8@1+ (1,0) [0|255] ""  TelemetryNode
 SG_ PDU_OD_CAN1_TxErrCnt m1104 : 16|8@1+ (1,0) [0|255] ""  TelemetryNode
 SG_ PDU_OD_BuildTime m1073 : 16|24@1+ (1,0) [0|16777215] ""  TelemetryNode
 SG_ PDU_OD_BuildDate m1072 : 16|32@1+ (1,0) [0|4294967295] ""  TelemetryNode
 SG_ PDU_OD_ChipUID2 m1057 : 16|48@1+ (1,0) [0|281474976710655] ""  TelemetryNode
 SG_ PDU_OD_ChipUID1 m1056 : 16|48@1+ (1,0) [0|281474976710655] ""  TelemetryNode
 SG_ PDU_OD_SdcOut m1046 : 16|8@1+ (1,0) [0|255] ""  TelemetryNode
 SG_ PDU_OD_SdcIn m1045 : 16|8@1+ (1,0) [0|255] ""  TelemetryNode
 SG_ PDU_OD_runtime m1044 : 16|24@1+ (1,0) [0|16777215] "ms"  TelemetryNode
 SG_ PDU_OD_InputVoltage m1043 : 16|16@1+ (0.001,0) [0|65.535] "V"  TelemetryNode
 SG_ PDU_OD_BoardTemp m1042 : 16|16@1+ (0.01,-30) [-30|625.35] "°C"  TelemetryNode
 SG_ PDU_OD_MemFree m1041 : 16|16@1+ (4,0) [0|262140] "bytes"  TelemetryNode
 SG_ PDU_OD_CpuUsage m1040 : 16|8@1+ (0.5,0) [0|100] "%"  TelemetryNode
 SG_ PDU_OD_OdEntrySendInterval m33 : 16|16@1+ (1,0) [0|65535] "ms"  TelemetryNode
 SG_ PDU_OD_SendOdOnBootup m32 : 16|8@1+ (1,0) [0|255] ""  TelemetryNode
 SG_ PDU_OD_HeartbeatInterval m16 : 16|16@1+ (1,0) [0|65535] "ms"  TelemetryNode
 SG_ PDU_OD_DbcVersion m5 : 16|16@1+ (1,0) [0|65535] ""  TelemetryNode
 SG_ PDU_OD_StackVersion m4 : 16|16@1+ (1,0) [0|65535] ""  TelemetryNode
 SG_ PDU_OD_ProtocolVersion m3 : 16|16@1+ (1,0) [0|65535] ""  TelemetryNode
 SG_ PDU_OD_NodeStatus m2 : 16|8@1+ (1,0) [0|255] ""  TelemetryNode
 SG_ PDU_OD_NodeID m1 : 16|8@1+ (1,0) [0|255] ""  TelemetryNode
 SG_ PDU_SDO_RespCode : 12|4@1+ (1,0) [0|0] ""  TelemetryNode
 SG_ PDU_SDO_ID M : 0|12@1+ (1,0) [0|4095] ""  TelemetryNode

BO_ 1498 PDU_SDO_Req_Up: 8 TelemetryNode
 SG_ PDU_OD_CoolingPumpEnabled m2816 : 16|8@1+ (1,0) [0|255] ""  PDU
 SG_ PDU_OD_LedCommands m2562 : 16|16@1+ (1,0) [0|65535] ""  PDU
 SG_ PDU_OD_projectXXEnabled m2560 : 16|8@1+ (1,0) [0|255] ""  PDU
 SG_ PDU_OD_watchdogTimeout m2306 : 16|16@1+ (1,0) [0|65535] "ms"  PDU
 SG_ PDU_OD_statusSendInterval m2305 : 16|16@1+ (1,0) [0|65535] "ms"  PDU
 SG_ PDU_OD_currentReadInterval m2304 : 16|16@1+ (1,0) [0|65535] "ms"  PDU
 SG_ PDU_OD_batteryOvercurrent m2128 : 16|16@1+ (0.01,0) [0|655.35] "A"  PDU
 SG_ PDU_OD_overTempCritical m2051 : 16|16@1+ (0.1,0) [0|6553.5] "degrees"  PDU
 SG_ PDU_OD_overTempWarn m2050 : 16|16@1+ (0.1,0) [0|6553.5] "degrees"  PDU
 SG_ PDU_OD_batterVoltageCritical m2049 : 16|16@1+ (0.01,0) [0|655.35] "V"  PDU
 SG_ PDU_OD_batterVoltageLow m2048 : 16|16@1+ (0.01,0) [0|655.35] "V"  PDU
 SG_ PDU_OD_CAN2_DelayedTxMessages m1129 : 16|24@1+ (1,0) [0|16777215] ""  PDU
 SG_ PDU_OD_CAN2_ErrorStatus m1128 : 16|8@1+ (1,0) [0|255] ""  PDU
 SG_ PDU_OD_CAN2_DiscardedTxMessages m1127 : 16|24@1+ (1,0) [0|16777215] ""  PDU
 SG_ PDU_OD_CAN2_Status m1126 : 16|8@1+ (1,0) [0|255] ""  PDU
 SG_ PDU_OD_CAN2_Baudrate m1124 : 16|16@1+ (1,0) [125|1000] "kbps"  PDU
 SG_ PDU_OD_CAN2_autoErrorReset m1123 : 16|8@1+ (1,0) [0|255] ""  PDU
 SG_ PDU_OD_CAN2_lastErrorCode m1122 : 16|32@1+ (1,0) [0|4294967295] ""  PDU
 SG_ PDU_OD_CAN2_RxErrCnt m1121 : 16|8@1+ (1,0) [0|255] ""  PDU
 SG_ PDU_OD_CAN2_TxErrCnt m1120 : 16|8@1+ (1,0) [0|255] ""  PDU
 SG_ PDU_OD_CAN1_DelayedTxMessages m1113 : 16|24@1+ (1,0) [0|16777215] ""  PDU
 SG_ PDU_OD_CAN1_ErrorStatus m1112 : 16|8@1+ (1,0) [0|255] ""  PDU
 SG_ PDU_OD_CAN1_DiscardedTxMessages m1111 : 16|24@1+ (1,0) [0|16777215] ""  PDU
 SG_ PDU_OD_CAN1_Status m1110 : 16|8@1+ (1,0) [0|255] ""  PDU
 SG_ PDU_OD_CAN1_Baudrate m1108 : 16|16@1+ (1,0) [125|1000] "kbps"  PDU
 SG_ PDU_OD_CAN1_autoErrorReset m1107 : 16|8@1+ (1,0) [0|255] ""  PDU
 SG_ PDU_OD_CAN1_lastErrorCode m1106 : 16|32@1+ (1,0) [0|4294967295] ""  PDU
 SG_ PDU_OD_CAN1_RxErrCnt m1105 : 16|8@1+ (1,0) [0|255] ""  PDU
 SG_ PDU_OD_CAN1_TxErrCnt m1104 : 16|8@1+ (1,0) [0|255] ""  PDU
 SG_ PDU_OD_BuildTime m1073 : 16|24@1+ (1,0) [0|16777215] ""  PDU
 SG_ PDU_OD_BuildDate m1072 : 16|32@1+ (1,0) [0|4294967295] ""  PDU
 SG_ PDU_OD_ChipUID2 m1057 : 16|48@1+ (1,0) [0|281474976710655] ""  PDU
 SG_ PDU_OD_ChipUID1 m1056 : 16|48@1+ (1,0) [0|281474976710655] ""  PDU
 SG_ PDU_OD_SdcOut m1046 : 16|8@1+ (1,0) [0|255] ""  PDU
 SG_ PDU_OD_SdcIn m1045 : 16|8@1+ (1,0) [0|255] ""  PDU
 SG_ PDU_OD_runtime m1044 : 16|24@1+ (1,0) [0|16777215] "ms"  PDU
 SG_ PDU_OD_InputVoltage m1043 : 16|16@1+ (0.001,0) [0|65.535] "V"  PDU
 SG_ PDU_OD_BoardTemp m1042 : 16|16@1+ (0.01,-30) [-30|625.35] "°C"  PDU
 SG_ PDU_OD_MemFree m1041 : 16|16@1+ (4,0) [0|262140] "bytes"  PDU
 SG_ PDU_OD_CpuUsage m1040 : 16|8@1+ (0.5,0) [0|100] "%"  PDU
 SG_ PDU_OD_OdEntrySendInterval m33 : 16|16@1+ (1,0) [0|65535] "ms"  PDU
 SG_ PDU_OD_SendOdOnBootup m32 : 16|8@1+ (1,0) [0|255] ""  PDU
 SG_ PDU_OD_HeartbeatInterval m16 : 16|16@1+ (1,0) [0|65535] "ms"  PDU
 SG_ PDU_OD_DbcVersion m5 : 16|16@1+ (1,0) [0|65535] ""  PDU
 SG_ PDU_OD_StackVersion m4 : 16|16@1+ (1,0) [0|65535] ""  PDU
 SG_ PDU_OD_ProtocolVersion m3 : 16|16@1+ (1,0) [0|65535] ""  PDU
 SG_ PDU_OD_NodeStatus m2 : 16|8@1+ (1,0) [0|255] ""  PDU
 SG_ PDU_OD_NodeID m1 : 16|8@1+ (1,0) [0|255] ""  PDU
 SG_ PDU_SDO_ID M : 0|12@1+ (1,0) [0|4095] ""  PDU

BO_ 1562 PDU_SDO_Req_Down: 2 TelemetryNode
 SG_ PDU_SDO_ID M : 0|12@1+ (1,0) [0|4095] ""  PDU

BO_ 1818 PDU_Heartbeat: 1 PDU
 SG_ PDU_NodeState : 0|8@1+ (1,0) [0|0] ""  SensorF,Master,TelemetryNode

BO_ 1882 PDU_BTL_TX: 8 PDU

BO_ 1946 PDU_BTL_RX: 8 TelemetryNode

BO_ 138 HVCU_EMCY: 4 HVCU
 SG_ HVCU_E19_ChargingModeError : 31|1@1+ (1,0) [0|0] ""  Master,TelemetryNode
 SG_ HVCU_E18_SDCSwitchError : 30|1@1+ (1,0) [0|0] ""  Master,TelemetryNode
 SG_ HVCU_E17_ControlMessageTimeout : 29|1@1+ (1,0) [0|0] ""  Master,TelemetryNode
 SG_ HVCU_E16_NoEnable : 28|1@1+ (1,0) [0|0] ""  Master,TelemetryNode
 SG_ HVCU_E15_SDCOpen : 27|1@1+ (1,0) [0|0] ""  Master,TelemetryNode
 SG_ HVCU_E14_HVMPError : 26|1@1+ (1,0) [0|0] ""  Master,TelemetryNode
 SG_ HVCU_E13_BIR4Error : 25|1@1+ (1,0) [0|0] ""  Master,TelemetryNode
 SG_ HVCU_E12_BIR3Error : 24|1@1+ (1,0) [0|0] ""  Master,TelemetryNode
 SG_ HVCU_E11_BIR2Error : 23|1@1+ (1,0) [0|0] ""  Master,TelemetryNode
 SG_ HVCU_E10_BIR1Error : 22|1@1+ (1,0) [0|0] ""  Master,TelemetryNode
 SG_ HVCU_E9_HVSLError : 21|1@1+ (1,0) [0|0] ""  Master,TelemetryNode
 SG_ HVCU_E8_VoltageMeasuring : 20|1@1+ (1,0) [0|0] ""  Master,TelemetryNode
 SG_ HVCU_E7_BALError : 19|1@1+ (1,0) [0|0] ""  Master,TelemetryNode
 SG_ HVCU_E6_DischargeError : 18|1@1+ (1,0) [0|0] ""  Master,TelemetryNode
 SG_ HVCU_E5_DischargeTimeout : 17|1@1+ (1,0) [0|0] ""  Master,TelemetryNode
 SG_ HVCU_E4_BMSPermissionMissing : 16|1@1+ (1,0) [0|0] ""  Master,TelemetryNode
 SG_ HVCU_E3_PrechargeError : 15|1@1+ (1,0) [0|0] ""  Master,TelemetryNode
 SG_ HVCU_E2_BMSError : 14|1@1+ (1,0) [0|0] ""  Master,TelemetryNode
 SG_ HVCU_E1_IMDError : 13|1@1+ (1,0) [0|0] ""  Master,TelemetryNode
 SG_ HVCU_E0_OtherError : 12|1@1+ (1,0) [0|0] ""  Master,TelemetryNode
 SG_ HVCU_W8_ChargingMode : 8|1@1+ (1,0) [0|0] ""  Master,TelemetryNode
 SG_ HVCU_W7_IsolationResistanceLow : 7|1@1+ (1,0) [0|0] ""  Master,TelemetryNode
 SG_ HVCU_W6_Bir4On : 6|1@1+ (1,0) [0|0] ""  Master,TelemetryNode
 SG_ HVCU_W5_Bir3On : 5|1@1+ (1,0) [0|0] ""  Master,TelemetryNode
 SG_ HVCU_W4_Bir2On : 4|1@1+ (1,0) [0|0] ""  Master,TelemetryNode
 SG_ HVCU_W3_Bir1On : 3|1@1+ (1,0) [0|0] ""  Master,TelemetryNode
 SG_ HVCU_W2_PreChargeOn : 2|1@1+ (1,0) [0|0] ""  Master,TelemetryNode
 SG_ HVCU_W1_HighVoltage : 1|1@1+ (1,0) [0|0] ""  Master,TelemetryNode
 SG_ HVCU_W0_OtherWarning : 0|1@1+ (1,0) [0|0] ""  Master,TelemetryNode

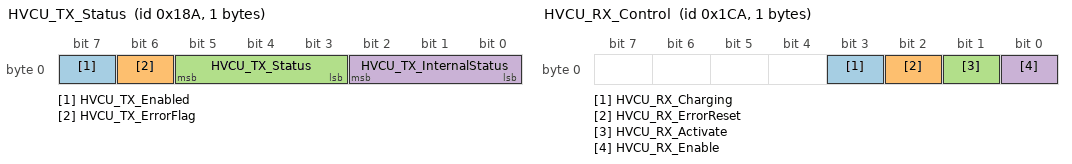
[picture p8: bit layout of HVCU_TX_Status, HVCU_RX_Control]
BO_ 394 HVCU_TX_Status: 1 HVCU
 SG_ HVCU_TX_Enabled : 7|1@1+ (1,0) [0|0] "" Vector__XXX
 SG_ HVCU_TX_ErrorFlag : 6|1@1+ (1,0) [0|0] "" Vector__XXX
 SG_ HVCU_TX_Status : 3|3@1+ (1,0) [0|0] "" Vector__XXX
 SG_ HVCU_TX_InternalStatus : 0|3@1+ (1,0) [0|0] "" Vector__XXX

BO_ 458 HVCU_RX_Control: 1 SensorF
 SG_ HVCU_RX_Charging : 3|1@1+ (1,0) [0|0] "" Vector__XXX
 SG_ HVCU_RX_ErrorReset : 2|1@1+ (1,0) [0|0] "" Vector__XXX
 SG_ HVCU_RX_Activate : 1|1@1+ (1,0) [0|0] "" Vector__XXX
 SG_ HVCU_RX_Enable : 0|1@1+ (1,0) [0|0] "" Vector__XXX

BO_ 522 HVCU_TX_PDO2: 0 HVCU

BO_ 586 HVCU_RX_PDO2: 0 Vector__XXX

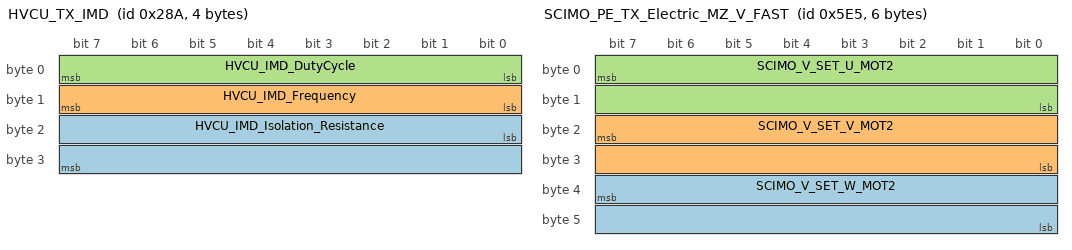
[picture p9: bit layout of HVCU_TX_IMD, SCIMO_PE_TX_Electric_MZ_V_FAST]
BO_ 650 HVCU_TX_IMD: 4 HVCU
 SG_ HVCU_IMD_Isolation_Resistance : 16|16@1+ (1,0) [0|65535] "kOhm" Vector__XXX
 SG_ HVCU_IMD_Frequency : 8|8@1+ (1,0) [0|60] "Hz" Vector__XXX
 SG_ HVCU_IMD_DutyCycle : 0|8@1+ (1,0) [0|100] "%" Vector__XXX

BO_ 714 HVCU_RX_PDO3: 0 Vector__XXX

BO_ 778 HVCU_TX_PDO4: 0 HVCU

BO_ 842 HVCU_RX_PDO4: 0 Vector__XXX

BO_ 906 HVCU_TX_PDO5: 0 HVCU

BO_ 970 HVCU_TX_PDO6: 0 HVCU

BO_ 1034 HVCU_TX_PDO7: 0 HVCU

BO_ 1098 HVCU_TX_PDO8: 0 HVCU

BO_ 1162 HVCU_TX_PDO9: 0 HVCU

BO_ 1226 HVCU_TX_PDO10: 0 HVCU

BO_ 1290 HVCU_TX_PDO11: 0 HVCU

BO_ 1354 HVCU_TX_PDO12: 0 HVCU

BO_ 1418 HVCU_SDO_Resp: 8 HVCU
 SG_ HVCU_OD_CAN2_DelayedTxMessages m1129 : 16|24@1+ (1,0) [0|16777215] ""  TelemetryNode
 SG_ HVCU_OD_CAN2_ErrorStatus m1128 : 16|8@1+ (1,0) [0|255] ""  TelemetryNode
 SG_ HVCU_OD_CAN2_DiscardedTxMessages m1127 : 16|24@1+ (1,0) [0|16777215] ""  TelemetryNode
 SG_ HVCU_OD_CAN2_Status m1126 : 16|8@1+ (1,0) [0|255] ""  TelemetryNode
 SG_ HVCU_OD_CAN2_Baudrate m1124 : 16|16@1+ (1,0) [125|1000] "kbps"  TelemetryNode
 SG_ HVCU_OD_CAN2_autoErrorReset m1123 : 16|8@1+ (1,0) [0|255] ""  TelemetryNode
 SG_ HVCU_OD_CAN2_lastErrorCode m1122 : 16|32@1+ (1,0) [0|4294967295] ""  TelemetryNode
 SG_ HVCU_OD_CAN2_RxErrCnt m1121 : 16|8@1+ (1,0) [0|255] ""  TelemetryNode
 SG_ HVCU_OD_CAN2_TxErrCnt m1120 : 16|8@1+ (1,0) [0|255] ""  TelemetryNode
 SG_ HVCU_OD_CAN1_DelayedTxMessages m1113 : 16|24@1+ (1,0) [0|16777215] ""  TelemetryNode
 SG_ HVCU_OD_CAN1_ErrorStatus m1112 : 16|8@1+ (1,0) [0|255] ""  TelemetryNode
 SG_ HVCU_OD_CAN1_DiscardedTxMessages m1111 : 16|24@1+ (1,0) [0|16777215] ""  TelemetryNode
 SG_ HVCU_OD_CAN1_Status m1110 : 16|8@1+ (1,0) [0|255] ""  TelemetryNode
 SG_ HVCU_OD_CAN1_Baudrate m1108 : 16|16@1+ (1,0) [125|1000] "kbps"  TelemetryNode
 SG_ HVCU_OD_CAN1_autoErrorReset m1107 : 16|8@1+ (1,0) [0|255] ""  TelemetryNode
 SG_ HVCU_OD_CAN1_lastErrorCode m1106 : 16|32@1+ (1,0) [0|4294967295] ""  TelemetryNode
 SG_ HVCU_OD_CAN1_RxErrCnt m1105 : 16|8@1+ (1,0) [0|255] ""  TelemetryNode
 SG_ HVCU_OD_CAN1_TxErrCnt m1104 : 16|8@1+ (1,0) [0|255] ""  TelemetryNode
 SG_ HVCU_OD_BuildTime m1073 : 16|24@1+ (1,0) [0|16777215] ""  TelemetryNode
 SG_ HVCU_OD_BuildDate m1072 : 16|32@1+ (1,0) [0|4294967295] ""  TelemetryNode
 SG_ HVCU_OD_ChipUID2 m1057 : 16|48@1+ (1,0) [0|281474976710655] ""  TelemetryNode
 SG_ HVCU_OD_ChipUID1 m1056 : 16|48@1+ (1,0) [0|281474976710655] ""  TelemetryNode
 SG_ HVCU_OD_SdcOut m1046 : 16|8@1+ (1,0) [0|255] ""  TelemetryNode
 SG_ HVCU_OD_SdcIn m1045 : 16|8@1+ (1,0) [0|255] ""  TelemetryNode
 SG_ HVCU_OD_runtime m1044 : 16|24@1+ (1,0) [0|16777215] "ms"  TelemetryNode
 SG_ HVCU_OD_InputVoltage m1043 : 16|16@1+ (0.001,0) [0|65.535] "V"  TelemetryNode
 SG_ HVCU_OD_BoardTemp m1042 : 16|16@1+ (0.01,-30) [-30|625.35] "°C"  TelemetryNode
 SG_ HVCU_OD_MemFree m1041 : 16|16@1+ (4,0) [0|262140] "bytes"  TelemetryNode
 SG_ HVCU_OD_CpuUsage m1040 : 16|8@1+ (0.5,0) [0|100] "%"  TelemetryNode
 SG_ HVCU_OD_OdEntrySendInterval m33 : 16|16@1+ (1,0) [0|65535] "ms"  TelemetryNode
 SG_ HVCU_OD_SendOdOnBootup m32 : 16|8@1+ (1,0) [0|255] ""  TelemetryNode
 SG_ HVCU_OD_HeartbeatInterval m16 : 16|16@1+ (1,0) [0|65535] "ms"  TelemetryNode
 SG_ HVCU_OD_DbcVersion m5 : 16|16@1+ (1,0) [0|65535] ""  TelemetryNode
 SG_ HVCU_OD_StackVersion m4 : 16|16@1+ (1,0) [0|65535] ""  TelemetryNode
 SG_ HVCU_OD_ProtocolVersion m3 : 16|16@1+ (1,0) [0|65535] ""  TelemetryNode
 SG_ HVCU_OD_NodeStatus m2 : 16|8@1+ (1,0) [0|255] ""  TelemetryNode
 SG_ HVCU_OD_NodeID m1 : 16|8@1+ (1,0) [0|255] ""  TelemetryNode
 SG_ HVCU_SDO_RespCode : 12|4@1+ (1,0) [0|0] ""  TelemetryNode
 SG_ HVCU_SDO_ID M : 0|12@1+ (1,0) [0|4095] ""  TelemetryNode

BO_ 1482 HVCU_SDO_Req_Up: 8 TelemetryNode
 SG_ HVCU_OD_CAN2_DelayedTxMessages m1129 : 16|24@1+ (1,0) [0|16777215] ""  HVCU
 SG_ HVCU_OD_CAN2_ErrorStatus m1128 : 16|8@1+ (1,0) [0|255] ""  HVCU
 SG_ HVCU_OD_CAN2_DiscardedTxMessages m1127 : 16|24@1+ (1,0) [0|16777215] ""  HVCU
 SG_ HVCU_OD_CAN2_Status m1126 : 16|8@1+ (1,0) [0|255] ""  HVCU
 SG_ HVCU_OD_CAN2_Baudrate m1124 : 16|16@1+ (1,0) [125|1000] "kbps"  HVCU
 SG_ HVCU_OD_CAN2_autoErrorReset m1123 : 16|8@1+ (1,0) [0|255] ""  HVCU
 SG_ HVCU_OD_CAN2_lastErrorCode m1122 : 16|32@1+ (1,0) [0|4294967295] ""  HVCU
 SG_ HVCU_OD_CAN2_RxErrCnt m1121 : 16|8@1+ (1,0) [0|255] ""  HVCU
 SG_ HVCU_OD_CAN2_TxErrCnt m1120 : 16|8@1+ (1,0) [0|255] ""  HVCU
 SG_ HVCU_OD_CAN1_DelayedTxMessages m1113 : 16|24@1+ (1,0) [0|16777215] ""  HVCU
 SG_ HVCU_OD_CAN1_ErrorStatus m1112 : 16|8@1+ (1,0) [0|255] ""  HVCU
 SG_ HVCU_OD_CAN1_DiscardedTxMessages m1111 : 16|24@1+ (1,0) [0|16777215] ""  HVCU
 SG_ HVCU_OD_CAN1_Status m1110 : 16|8@1+ (1,0) [0|255] ""  HVCU
 SG_ HVCU_OD_CAN1_Baudrate m1108 : 16|16@1+ (1,0) [125|1000] "kbps"  HVCU
 SG_ HVCU_OD_CAN1_autoErrorReset m1107 : 16|8@1+ (1,0) [0|255] ""  HVCU
 SG_ HVCU_OD_CAN1_lastErrorCode m1106 : 16|32@1+ (1,0) [0|4294967295] ""  HVCU
 SG_ HVCU_OD_CAN1_RxErrCnt m1105 : 16|8@1+ (1,0) [0|255] ""  HVCU
 SG_ HVCU_OD_CAN1_TxErrCnt m1104 : 16|8@1+ (1,0) [0|255] ""  HVCU
 SG_ HVCU_OD_BuildTime m1073 : 16|24@1+ (1,0) [0|16777215] ""  HVCU
 SG_ HVCU_OD_BuildDate m1072 : 16|32@1+ (1,0) [0|4294967295] ""  HVCU
 SG_ HVCU_OD_ChipUID2 m1057 : 16|48@1+ (1,0) [0|281474976710655] ""  HVCU
 SG_ HVCU_OD_ChipUID1 m1056 : 16|48@1+ (1,0) [0|281474976710655] ""  HVCU
 SG_ HVCU_OD_SdcOut m1046 : 16|8@1+ (1,0) [0|255] ""  HVCU
 SG_ HVCU_OD_SdcIn m1045 : 16|8@1+ (1,0) [0|255] ""  HVCU
 SG_ HVCU_OD_runtime m1044 : 16|24@1+ (1,0) [0|16777215] "ms"  HVCU
 SG_ HVCU_OD_InputVoltage m1043 : 16|16@1+ (0.001,0) [0|65.535] "V"  HVCU
 SG_ HVCU_OD_BoardTemp m1042 : 16|16@1+ (0.01,-30) [-30|625.35] "°C"  HVCU
 SG_ HVCU_OD_MemFree m1041 : 16|16@1+ (4,0) [0|262140] "bytes"  HVCU
 SG_ HVCU_OD_CpuUsage m1040 : 16|8@1+ (0.5,0) [0|100] "%"  HVCU
 SG_ HVCU_OD_OdEntrySendInterval m33 : 16|16@1+ (1,0) [0|65535] "ms"  HVCU
 SG_ HVCU_OD_SendOdOnBootup m32 : 16|8@1+ (1,0) [0|255] ""  HVCU
 SG_ HVCU_OD_HeartbeatInterval m16 : 16|16@1+ (1,0) [0|65535] "ms"  HVCU
 SG_ HVCU_OD_DbcVersion m5 : 16|16@1+ (1,0) [0|65535] ""  HVCU
 SG_ HVCU_OD_StackVersion m4 : 16|16@1+ (1,0) [0|65535] ""  HVCU
 SG_ HVCU_OD_ProtocolVersion m3 : 16|16@1+ (1,0) [0|65535] ""  HVCU
 SG_ HVCU_OD_NodeStatus m2 : 16|8@1+ (1,0) [0|255] ""  HVCU
 SG_ HVCU_OD_NodeID m1 : 16|8@1+ (1,0) [0|255] ""  HVCU
 SG_ HVCU_SDO_ID M : 0|12@1+ (1,0) [0|4095] ""  HVCU

BO_ 1546 HVCU_SDO_Req_Down: 2 TelemetryNode
 SG_ HVCU_SDO_ID M : 0|12@1+ (1,0) [0|4095] ""  HVCU

BO_ 1802 HVCU_Heartbeat: 1 HVCU
 SG_ HVCU_NodeState : 0|8@1+ (1,0) [0|0] ""  Master,TelemetryNode

BO_ 1866 HVCU_BTL_TX: 8 HVCU

BO_ 1930 HVCU_BTL_RX: 8 TelemetryNode

BO_ 153 HVTU_EMCY: 4 HVTU
 SG_ HVTU_E0_OtherError : 12|1@1+ (1,0) [0|0] ""  Master,TelemetryNode
 SG_ HVTU_W0_OtherWarning : 0|1@1+ (1,0) [0|0] ""  Master,TelemetryNode

BO_ 2684289024 EMUS_Internal_01: 8 EMUS_BMS

BO_ 2684289025 EMUS_Internal_02: 8 EMUS_BMS

BO_ 2684289026 EMUS_Internal_03: 8 EMUS_BMS

BO_ 2684289027 EMUS_Internal_04: 8 EMUS_BMS

BO_ 2684289028 EMUS_Internal_05: 8 EMUS_BMS

BO_ 2684289029 EMUS_Internal_06: 8 EMUS_BMS

BO_ 2684289030 EMUS_Internal_07: 8 EMUS_BMS

BO_ 2684289031 EMUS_Internal_08: 8 EMUS_BMS

BO_ 2684289032 EMUS_Internal_09: 8 EMUS_BMS

BO_ 2684289033 EMUS_Internal_10: 8 EMUS_BMS

BO_ 2684289034 EMUS_Internal_11: 8 EMUS_BMS

BO_ 2684289035 EMUS_Internal_12: 8 EMUS_BMS

BO_ 2684289036 EMUS_Internal_13: 8 EMUS_BMS

BO_ 2684289037 EMUS_Internal_14: 8 EMUS_BMS

BO_ 2684289038 EMUS_Internal_15: 8 EMUS_BMS

BO_ 2684289039 EMUS_Internal_16: 8 EMUS_BMS

BO_ 2684289040 EMUS_Internal_17: 8 EMUS_BMS

BO_ 2684289041 EMUS_Internal_18: 8 EMUS_BMS

BO_ 2684289042 EMUS_Internal_19: 8 EMUS_BMS

BO_ 2684289043 EMUS_Internal_20: 8 EMUS_BMS

BO_ 2684289044 EMUS_Internal_21: 8 EMUS_BMS

BO_ 2684289045 EMUS_Internal_22: 8 EMUS_BMS

BO_ 2684289046 EMUS_Internal_23: 8 EMUS_BMS

BO_ 2684289047 EMUS_Internal_24: 8 EMUS_BMS

BO_ 2684289048 EMUS_Internal_25: 8 EMUS_BMS

BO_ 2684289049 EMUS_Internal_26: 8 EMUS_BMS

BO_ 2684289050 EMUS_Internal_27: 8 EMUS_BMS

BO_ 2684289051 EMUS_Internal_28: 8 EMUS_BMS

BO_ 2684289052 EMUS_Internal_29: 8 EMUS_BMS

BO_ 2684289053 EMUS_Internal_30: 8 EMUS_BMS

BO_ 2684289054 EMUS_Internal_31: 8 EMUS_BMS

BO_ 2684289055 EMUS_Internal_32: 8 EMUS_BMS

BO_ 2684289056 EMUS_Internal_33: 8 EMUS_BMS

BO_ 2684289057 EMUS_Internal_34: 8 EMUS_BMS

BO_ 2684289058 EMUS_Internal_35: 8 EMUS_BMS

BO_ 2684289059 EMUS_Internal_36: 8 EMUS_BMS

BO_ 2684289060 EMUS_Internal_37: 8 EMUS_BMS

BO_ 2684289061 EMUS_Internal_38: 8 EMUS_BMS

BO_ 2684289062 EMUS_Internal_39: 8 EMUS_BMS

BO_ 2684289063 EMUS_Internal_40: 8 EMUS_BMS

BO_ 2684289064 EMUS_Internal_41: 8 EMUS_BMS

BO_ 2684289065 EMUS_Internal_42: 8 EMUS_BMS

BO_ 2684289066 EMUS_Internal_43: 8 EMUS_BMS

BO_ 2684289067 EMUS_Internal_44: 8 EMUS_BMS

BO_ 2684289068 EMUS_Internal_45: 8 EMUS_BMS

BO_ 2684289069 EMUS_Internal_46: 8 EMUS_BMS

BO_ 2684289070 EMUS_Internal_47: 8 EMUS_BMS

BO_ 2684289071 EMUS_Internal_48: 8 EMUS_BMS

BO_ 1509 SCIMO_PE_TX_Electric_MZ_V_FAST: 6 SCIMO_PE
 SG_ SCIMO_V_SET_W_MOT2 : 39|16@0- (0.02,0) [-655.36|655.34] "" Vector__XXX
 SG_ SCIMO_V_SET_V_MOT2 : 23|16@0- (0.02,0) [-655.36|655.34] "" Vector__XXX
 SG_ SCIMO_V_SET_U_MOT2 : 7|16@0- (0.02,0) [-655.36|655.34] "" Vector__XXX

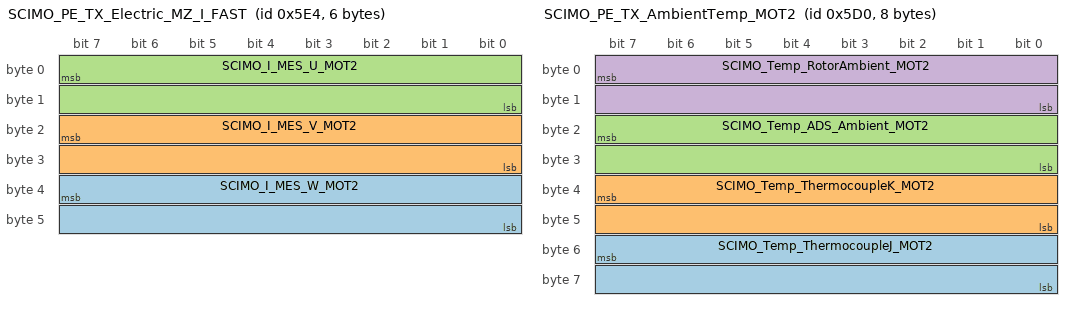
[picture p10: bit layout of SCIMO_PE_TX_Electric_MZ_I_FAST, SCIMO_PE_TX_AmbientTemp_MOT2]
BO_ 1508 SCIMO_PE_TX_Electric_MZ_I_FAST: 6 SCIMO_PE
 SG_ SCIMO_I_MES_W_MOT2 : 39|16@0- (0.02,0) [-655.36|655.34] "" Vector__XXX
 SG_ SCIMO_I_MES_V_MOT2 : 23|16@0- (0.02,0) [-655.36|655.34] "" Vector__XXX
 SG_ SCIMO_I_MES_U_MOT2 : 7|16@0- (0.02,0) [-655.36|655.34] "" Vector__XXX

BO_ 1488 SCIMO_PE_TX_AmbientTemp_MOT2: 8 SensorR
 SG_ SCIMO_Temp_ThermocoupleJ_MOT2 : 55|16@0- (0.005,150) [-13.84|313.835] ""  TestBench
 SG_ SCIMO_Temp_ThermocoupleK_MOT2 : 39|16@0- (0.005,150) [-13.84|313.835] ""  TestBench
 SG_ SCIMO_Temp_ADS_Ambient_MOT2 : 23|16@0- (0.005,150) [-13.84|313.835] ""  TestBench
 SG_ SCIMO_Temp_RotorAmbient_MOT2 : 7|16@0- (0.005,150) [-13.84|313.835] ""  TestBench

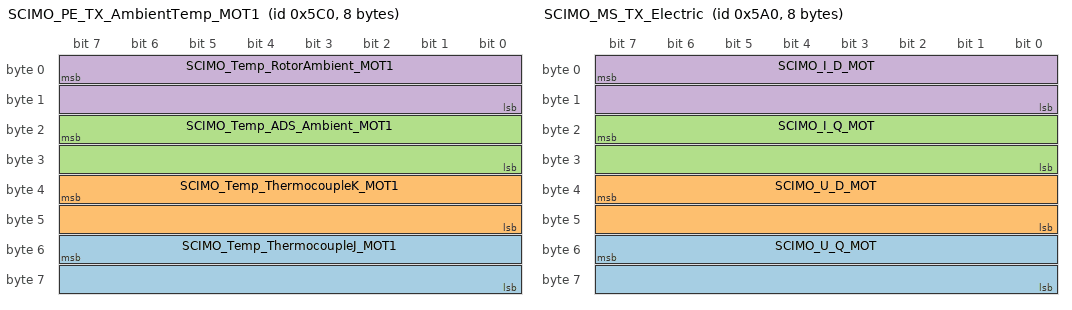
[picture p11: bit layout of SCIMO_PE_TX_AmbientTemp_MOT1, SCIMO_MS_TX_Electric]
BO_ 1472 SCIMO_PE_TX_AmbientTemp_MOT1: 8 SensorR
 SG_ SCIMO_Temp_ThermocoupleJ_MOT1 : 55|16@0- (0.005,150) [-13.84|313.835] ""  TestBench
 SG_ SCIMO_Temp_ThermocoupleK_MOT1 : 39|16@0- (0.005,150) [-13.84|313.835] ""  TestBench
 SG_ SCIMO_Temp_ADS_Ambient_MOT1 : 23|16@0- (0.005,150) [-13.84|313.835] ""  TestBench
 SG_ SCIMO_Temp_RotorAmbient_MOT1 : 7|16@0- (0.005,150) [-13.84|313.835] ""  TestBench

BO_ 1456 SCIMO_MS_RX_RequestData: 2 SensorR
 SG_ SCIMO_NumOfSamples : 7|16@0+ (1,0) [0|65535] ""  TestBench

BO_ 1440 SCIMO_MS_TX_Electric: 8 SCIMO_PE
 SG_ SCIMO_U_Q_MOT : 55|16@0- (0.025,0) [-819.2|819.175] ""  TestBench
 SG_ SCIMO_U_D_MOT : 39|16@0- (0.025,0) [-819.2|819.175] ""  TestBench
 SG_ SCIMO_I_Q_MOT : 23|16@0- (0.025,0) [-819.2|819.175] ""  TestBench
 SG_ SCIMO_I_D_MOT : 7|16@0- (0.025,0) [-819.2|819.175] ""  TestBench

BO_ 1344 SCIMO_PE_TX_MotorTemp_MOT2: 6 SensorR
 SG_ SCIMO_Temp_PT100B_MOT2 : 39|16@0- (0.005,150) [-13.84|313.835] ""  TestBench
 SG_ SCIMO_Temp_PT100A_MOT2 : 23|16@0- (0.005,150) [-13.84|313.835] ""  TestBench
 SG_ SCIMO_Temp_Rotor_MOT2 : 7|16@0- (0.005,150) [-13.84|313.835] ""  TestBench

BO_ 1328 SCIMO_PE_TX_MotorTemp_MOT1: 6 SensorR
 SG_ SCIMO_Temp_PT100B_MOT1 : 39|16@0- (0.005,150) [-13.84|313.835] ""  TestBench
 SG_ SCIMO_Temp_PT100A_MOT1 : 23|16@0- (0.005,150) [-13.84|313.835] ""  TestBench
 SG_ SCIMO_Temp_Rotor_MOT1 : 7|16@0- (0.005,150) [-13.84|313.835] ""  TestBench

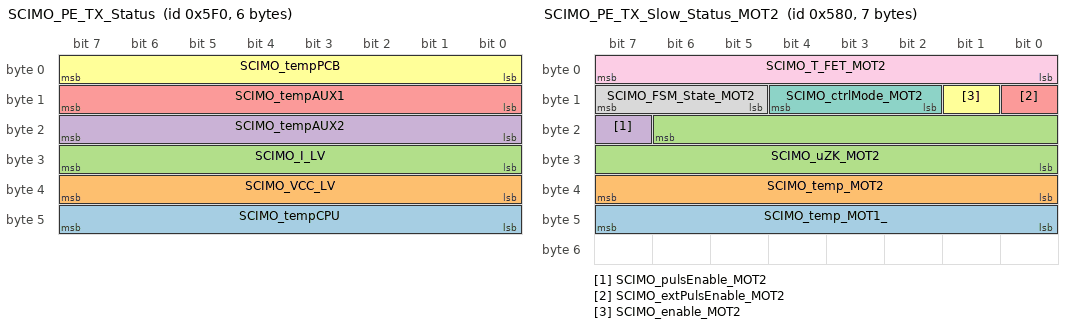
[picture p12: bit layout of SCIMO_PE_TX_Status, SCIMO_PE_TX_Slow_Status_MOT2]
BO_ 1520 SCIMO_PE_TX_Status: 6 SCIMO_PE
 SG_ SCIMO_tempCPU : 47|8@0+ (0.5,0) [0|127.5] ""  TestBench,SensorR
 SG_ SCIMO_VCC_LV : 39|8@0+ (0.25,6) [6|69.75] ""  TestBench,SensorR
 SG_ SCIMO_I_LV : 31|8@0+ (0.01,0) [0|2.55] ""  TestBench,SensorR
 SG_ SCIMO_tempAUX2 : 23|8@0+ (1,0) [0|255] ""  TestBench,SensorR
 SG_ SCIMO_tempAUX1 : 15|8@0+ (1,0) [0|255] ""  TestBench,SensorR
 SG_ SCIMO_tempPCB : 7|8@0+ (1,0) [0|255] ""  TestBench,SensorR

BO_ 1408 SCIMO_PE_TX_Slow_Status_MOT2: 7 SCIMO_PE
 SG_ SCIMO_temp_MOT1_ : 47|8@0+ (1,0) [0|0] ""  TestBench,SensorR
 SG_ SCIMO_temp_MOT2 : 39|8@0+ (1,0) [0|0] ""  TestBench,SensorR
 SG_ SCIMO_uZK_MOT2 : 22|15@0- (0.1,0) [0|0] ""  TestBench,SensorR
 SG_ SCIMO_pulsEnable_MOT2 : 23|1@0+ (1,0) [0|0] ""  TestBench,SensorR
 SG_ SCIMO_extPulsEnable_MOT2 : 8|1@0+ (1,0) [0|0] ""  TestBench,SensorR
 SG_ SCIMO_enable_MOT2 : 9|1@0+ (1,0) [0|0] ""  TestBench,SensorR
 SG_ SCIMO_ctrlMode_MOT2 : 12|3@0+ (1,0) [0|0] ""  TestBench,SensorR
 SG_ SCIMO_FSM_State_MOT2 : 15|3@0+ (1,0) [0|0] ""  TestBench,SensorR
 SG_ SCIMO_T_FET_MOT2 : 7|8@0+ (1,0) [0|0] ""  TestBench,SensorR

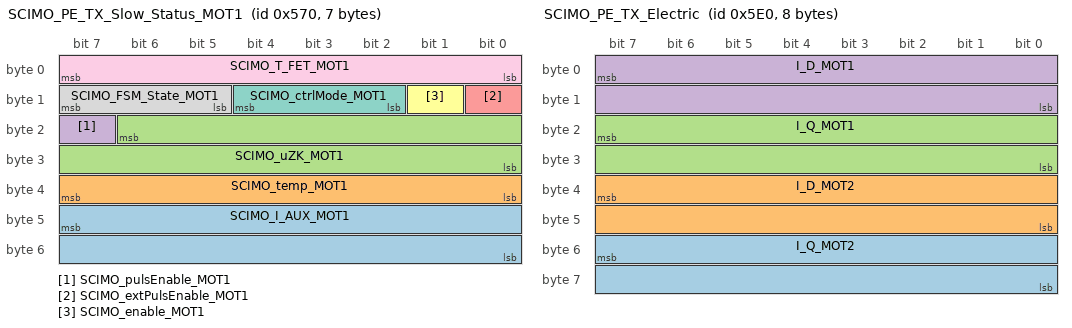
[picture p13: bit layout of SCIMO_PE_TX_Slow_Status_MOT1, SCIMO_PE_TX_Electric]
BO_ 1392 SCIMO_PE_TX_Slow_Status_MOT1: 7 SCIMO_PE
 SG_ SCIMO_I_AUX_MOT1 : 47|16@0- (1,0) [-32768|32767] ""  TestBench
 SG_ SCIMO_temp_MOT1 : 39|8@0+ (1,0) [0|0] ""  TestBench,SensorR
 SG_ SCIMO_uZK_MOT1 : 22|15@0- (0.1,0) [0|0] ""  TestBench,SensorR
 SG_ SCIMO_pulsEnable_MOT1 : 23|1@0+ (1,0) [0|0] ""  TestBench,SensorR
 SG_ SCIMO_extPulsEnable_MOT1 : 8|1@0+ (1,0) [0|0] ""  TestBench,SensorR
 SG_ SCIMO_enable_MOT1 : 9|1@0+ (1,0) [0|0] ""  TestBench,SensorR
 SG_ SCIMO_ctrlMode_MOT1 : 12|3@0+ (1,0) [0|0] ""  TestBench,SensorR
 SG_ SCIMO_FSM_State_MOT1 : 15|3@0+ (1,0) [0|0] ""  TestBench,SensorR
 SG_ SCIMO_T_FET_MOT1 : 7|8@0+ (1,0) [0|0] ""  TestBench,SensorR

BO_ 1504 SCIMO_PE_TX_Electric: 8 SCIMO_PE
 SG_ I_Q_MOT2 : 55|16@0- (1,0) [0|0] ""  TestBench,SensorR
 SG_ I_D_MOT2 : 39|16@0- (1,0) [0|0] ""  TestBench,SensorR
 SG_ I_Q_MOT1 : 23|16@0- (1,0) [0|0] ""  TestBench,SensorR
 SG_ I_D_MOT1 : 7|16@0- (1,0) [0|0] ""  TestBench,SensorR

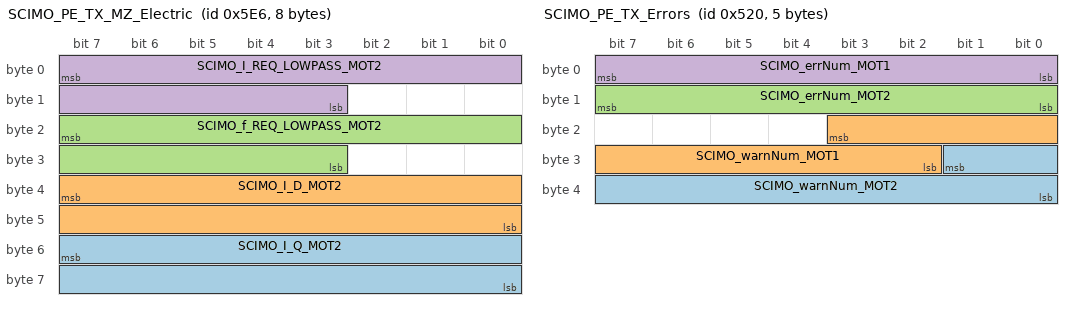
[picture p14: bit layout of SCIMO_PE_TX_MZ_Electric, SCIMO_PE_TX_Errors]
BO_ 1510 SCIMO_PE_TX_MZ_Electric: 8 SCIMO_PE
 SG_ SCIMO_I_Q_MOT2 : 55|16@0- (0.05,0) [-1638.4|1638.35] ""  TestBench,SensorR
 SG_ SCIMO_I_D_MOT2 : 39|16@0- (0.05,0) [-1638.4|1638.35] ""  TestBench,SensorR
 SG_ SCIMO_f_REQ_LOWPASS_MOT2 : 23|13@0+ (0.05,0) [0|409.55] ""  TestBench,SensorR
 SG_ SCIMO_I_REQ_LOWPASS_MOT2 : 7|13@0+ (0.05,0) [0|409.55] ""  TestBench,SensorR

BO_ 1312 SCIMO_PE_TX_Errors: 5 SCIMO_PE
 SG_ SCIMO_warnNum_MOT2 : 25|10@0+ (1,0) [0|0] ""  TestBench,SensorR
 SG_ SCIMO_warnNum_MOT1 : 19|10@0+ (1,0) [0|1023] ""  TestBench,SensorR
 SG_ SCIMO_errNum_MOT2 : 15|8@0+ (1,0) [0|0] ""  TestBench,SensorR
 SG_ SCIMO_errNum_MOT1 : 7|8@0+ (1,0) [0|0] ""  TestBench,SensorR

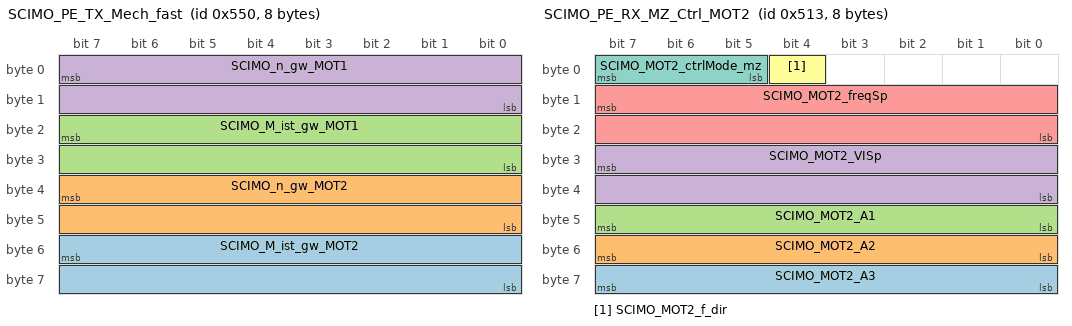
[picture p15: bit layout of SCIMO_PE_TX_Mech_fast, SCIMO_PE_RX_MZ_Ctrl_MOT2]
BO_ 1360 SCIMO_PE_TX_Mech_fast: 8 SCIMO_PE
 SG_ SCIMO_M_ist_gw_MOT2 : 55|16@0- (1,0) [0|0] ""  TestBench,SensorR
 SG_ SCIMO_n_gw_MOT2 : 39|16@0- (1,0) [0|0] ""  TestBench,SensorR
 SG_ SCIMO_M_ist_gw_MOT1 : 23|16@0- (1,0) [0|0] ""  TestBench,SensorR
 SG_ SCIMO_n_gw_MOT1 : 7|16@0- (1,0) [0|0] ""  TestBench,SensorR

BO_ 1299 SCIMO_PE_RX_MZ_Ctrl_MOT2: 8 SensorR
 SG_ SCIMO_MOT2_A3 : 56|8@1+ (0.01,0) [0|2.55] ""  SCIMO_PE
 SG_ SCIMO_MOT2_A2 : 48|8@1+ (0.01,0) [0|2.55] ""  SCIMO_PE
 SG_ SCIMO_MOT2_A1 : 40|8@1+ (0.01,0) [0|2.55] ""  SCIMO_PE
 SG_ SCIMO_MOT2_VISp : 31|16@0+ (0.01,0) [0|655.35] ""  TestBench,SCIMO_PE
 SG_ SCIMO_MOT2_freqSp : 15|16@0+ (0.02,0) [0|1310.7] ""  TestBench,SCIMO_PE
 SG_ SCIMO_MOT2_f_dir : 4|1@0+ (1,0) [0|0] ""  SCIMO_PE
 SG_ SCIMO_MOT2_ctrlMode_mz : 7|3@0+ (1,0) [0|0] ""  TestBench,SCIMO_PE

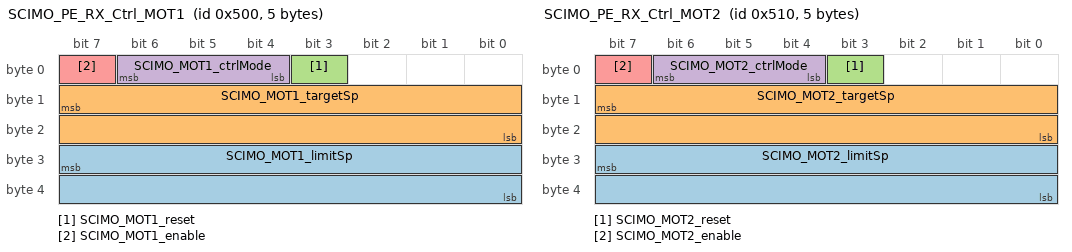
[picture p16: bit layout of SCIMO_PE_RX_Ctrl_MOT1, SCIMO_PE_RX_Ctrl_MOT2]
BO_ 1280 SCIMO_PE_RX_Ctrl_MOT1: 5 SensorR
 SG_ SCIMO_MOT1_limitSp : 31|16@0- (1,0) [0|0] ""  TestBench,SCIMO_PE
 SG_ SCIMO_MOT1_targetSp : 15|16@0- (1,0) [0|0] ""  TestBench,SCIMO_PE
 SG_ SCIMO_MOT1_reset : 3|1@0+ (1,0) [0|0] ""  TestBench,SCIMO_PE
 SG_ SCIMO_MOT1_ctrlMode : 6|3@0+ (1,0) [0|0] ""  TestBench,SCIMO_PE
 SG_ SCIMO_MOT1_enable : 7|1@0+ (1,0) [0|0] ""  TestBench,SCIMO_PE

BO_ 1296 SCIMO_PE_RX_Ctrl_MOT2: 5 SensorR
 SG_ SCIMO_MOT2_limitSp : 31|16@0- (1,0) [0|0] ""  TestBench,SCIMO_PE
 SG_ SCIMO_MOT2_targetSp : 15|16@0- (1,0) [0|0] ""  TestBench,SCIMO_PE
 SG_ SCIMO_MOT2_reset : 3|1@0+ (1,0) [0|0] ""  TestBench,SCIMO_PE
 SG_ SCIMO_MOT2_ctrlMode : 6|3@0+ (1,0) [0|0] ""  TestBench,SCIMO_PE
 SG_ SCIMO_MOT2_enable : 7|1@0+ (1,0) [0|0] ""  TestBench,SCIMO_PE

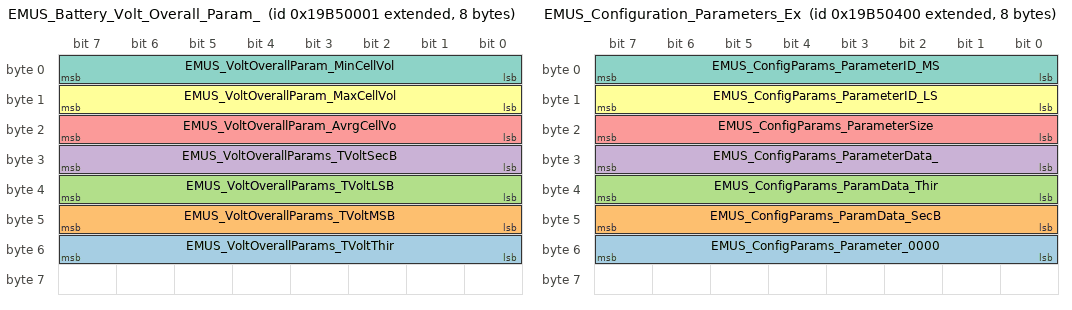
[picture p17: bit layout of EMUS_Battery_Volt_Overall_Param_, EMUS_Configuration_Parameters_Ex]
BO_ 2578776065 EMUS_Battery_Volt_Overall_Param_: 8 EMUS_BMS
 SG_ EMUS_VoltOverallParams_TVoltThir : 48|8@1+ (1,0) [0|255] ""  HVCU,HVTU
 SG_ EMUS_VoltOverallParams_TVoltMSB : 40|8@1+ (1,0) [0|255] ""  HVCU,HVTU
 SG_ EMUS_VoltOverallParams_TVoltLSB : 32|8@1+ (1,0) [0|255] ""  HVCU,HVTU
 SG_ EMUS_VoltOverallParams_TVoltSecB : 24|8@1+ (1,0) [0|255] ""  HVCU,HVTU
 SG_ EMUS_VoltOverallParam_AvrgCellVo : 16|8@1+ (0.01,2) [2|4.55] "V"  HVCU,HVTU
 SG_ EMUS_VoltOverallParam_MaxCellVol : 8|8@1+ (0.01,2) [2|4.55] "V"  HVCU,HVTU
 SG_ EMUS_VoltOverallParam_MinCellVol : 0|8@1+ (0.01,2) [2|4.55] "V"  HVCU,HVTU

BO_ 2578776064 EMUS_Overall_Parameters_Ext: 8 EMUS_BMS
 SG_ EMUS_OverallParams_NumberOf_0000 : 56|8@1+ (1,0) [0|255] ""  HVCU
 SG_ EMUS_OverallParams_LastChargingE : 48|8@1+ (1,0) [0|255] ""  HVCU
 SG_ EMUS_OverallParams_ChrgStag_0000 : 40|8@1+ (1,0) [0|255] ""  HVCU
 SG_ EMUS_OverallParams_ChrgStageDura : 32|8@1+ (1,0) [0|255] ""  HVCU
 SG_ EMUS_OverallParams_ChargingStage : 24|8@1+ (1,0) [0|255] ""  HVCU
 SG_ EMUS_OverallParams_NumberOfCells : 16|8@1+ (1,0) [0|255] ""  HVCU
 SG_ EMUS_OverallParams_ContactorPreC : 15|1@1+ (1,0) [0|1] ""  HVCU
 SG_ EMUS_OverallParams_DCDC_Control : 14|1@1+ (1,0) [0|1] ""  HVCU
 SG_ EMUS_OverallParams_ChargingInter : 13|1@1+ (1,0) [0|1] ""  HVCU
 SG_ EMUS_OverallParams_PowerReductio : 12|1@1+ (1,0) [0|1] ""  HVCU
 SG_ EMUS_OverallParams_BatteryFan : 11|1@1+ (1,0) [0|1] ""  HVCU
 SG_ EMUS_OverallParams_BatteryContac : 10|1@1+ (1,0) [0|1] ""  HVCU
 SG_ EMUS_OverallParams_HeaterEnable : 9|1@1+ (1,0) [0|1] ""  HVCU
 SG_ EMUS_OverallParams_ChargerEnable : 8|1@1+ (1,0) [0|1] ""  HVCU
 SG_ EMUS_OverallParams_LeakageSensor : 3|1@1+ (1,0) [0|1] ""  HVCU
 SG_ EMUS_OverallParams_FastCharge : 2|1@1+ (1,0) [0|1] ""  HVCU
 SG_ EMUS_OverallParams_ChargerMains : 1|1@1+ (1,0) [0|1] ""  HVCU
 SG_ EMUS_OverallParams_IgnitionKey : 0|1@1+ (1,0) [0|1] ""  HVCU

BO_ 2578776071 EMUS_Diagnostic_Codes_Ext: 8 EMUS_BMS
 SG_ EMUS_DiagnosticCodes_CellTempVal : 29|1@1+ (1,0) [0|1] ""  HVCU,HVTU
 SG_ EMUS_DiagnosticCodes_BatChrgFini : 28|1@1+ (1,0) [0|1] ""  HVCU,HVTU
 SG_ EMUS_DiagnosticCodes_NumOfCellsV : 27|1@1+ (1,0) [0|1] ""  HVCU,HVTU
 SG_ EMUS_DiagnosticCodes_CellBalancV : 26|1@1+ (1,0) [0|1] ""  HVCU,HVTU
 SG_ EMUS_DiagnosticCodes_CellModTemp : 25|1@1+ (1,0) [0|1] ""  HVCU,HVTU
 SG_ EMUS_DiagnosticCodes_CellVoltVal : 24|1@1+ (1,0) [0|1] ""  HVCU,HVTU
 SG_ EMUS_DiagnosticCodes_PackUnderVo : 21|1@1+ (1,0) [0|1] ""  HVCU,HVTU
 SG_ EMUS_DiagnosticCodes_NoCurrentSe : 20|1@1+ (1,0) [0|1] ""  HVCU,HVTU
 SG_ EMUS_DiagnosticCodes_CellOverHea : 19|1@1+ (1,0) [0|1] ""  HVCU,HVTU
 SG_ EMUS_DiagnosticCodes_HighTempera : 10|1@1+ (1,0) [0|1] ""  HVCU,HVTU
 SG_ EMUS_DiagnosticCodes_HighCurrent : 9|1@1+ (1,0) [0|1] ""  HVCU,HVTU
 SG_ EMUS_DiagnosticCodes_LowVoltage : 8|1@1+ (1,0) [0|1] ""  HVCU,HVTU
 SG_ EMUS_DiagnosticCodes_NoCellComm : 6|1@1+ (1,0) [0|1] ""  HVCU,HVTU
 SG_ EMUS_DiagnosticCodes_Leakage : 5|1@1+ (1,0) [0|1] ""  HVCU,HVTU
 SG_ EMUS_DiagnosticCodes_CellModOver : 4|1@1+ (1,0) [0|1] ""  HVCU,HVTU
 SG_ EMUS_DiagnosticCodes_ChrgOverCur : 3|1@1+ (1,0) [0|1] ""  HVCU,HVTU
 SG_ EMUS_DiagnosticCodes_DchrgOvrCur : 2|1@1+ (1,0) [0|1] ""  HVCU,HVTU
 SG_ EMUS_DiagnosticCodes_OverVoltage : 1|1@1+ (1,0) [0|1] ""  HVCU,HVTU
 SG_ EMUS_DiagnosticCodes_UnderVoltag : 0|1@1+ (1,0) [0|1] ""  HVCU,HVTU

BO_ 2578776066 EMUS_Cell_Mod_Temp_Overall_Param: 8 EMUS_BMS
 SG_ EMUS_CellModOverallPar_AvgCellMo : 16|8@1+ (1,-100) [-100|155] "Â°C"  HVTU
 SG_ EMUS_CellModOverallPar_MaxCellMo : 8|8@1+ (1,-100) [-100|155] "Â°C"  HVTU
 SG_ EMUS_CellModOverallPar_MinCellMo : 0|8@1+ (1,-100) [-100|155] "Â°C"  HVTU

BO_ 2578776072 EMUS_Cell_Temp_Overall_Params_Ex: 8 EMUS_BMS
 SG_ EMUS_CellOverallPar_AvgCellTemp : 16|8@1+ (1,-100) [-100|155] "Â°C"  HVTU
 SG_ EMUS_CellOverallPar_MaxCellTemp : 8|8@1+ (1,-100) [-100|155] "Â°C"  HVTU
 SG_ EMUS_CellOverallPar_MinCellTemp : 0|8@1+ (1,-100) [-100|155] "Â°C"  HVTU

BO_ 2578776067 EMUS_Cell_Balanc_Rate_Overall_Pa: 8 EMUS_BMS
 SG_ EMUS_CellBalancPar_AvgCellBalanc : 16|8@1+ (0.392156862745098,0) [0|100] "%"  HVTU
 SG_ EMUS_CellBalancPar_MaxCellBalanc : 8|8@1+ (0.392156862745098,0) [0|100] "%"  HVTU
 SG_ EMUS_CellBalancPar_MinCellBalanc : 0|8@1+ (0.392156862745098,0) [0|100] "%"  HVTU

BO_ 2578777088 EMUS_Configuration_Parameters_Ex: 8 EMUS_BMS
 SG_ EMUS_ConfigParams_Parameter_0000 : 48|8@1+ (1,0) [0|255] "" Vector__XXX
 SG_ EMUS_ConfigParams_ParamData_SecB : 40|8@1+ (1,0) [0|255] "" Vector__XXX
 SG_ EMUS_ConfigParams_ParamData_Thir : 32|8@1+ (1,0) [0|255] "" Vector__XXX
 SG_ EMUS_ConfigParams_ParameterData_ : 24|8@1+ (1,0) [0|255] "" Vector__XXX
 SG_ EMUS_ConfigParams_ParameterSize : 16|8@1+ (1,0) [0|255] "" Vector__XXX
 SG_ EMUS_ConfigParams_ParameterID_LS : 8|8@1+ (1,0) [0|255] "" Vector__XXX
 SG_ EMUS_ConfigParams_ParameterID_MS : 0|8@1+ (1,0) [0|255] "" Vector__XXX

BO_ 2578777090 EMUS_Login_Level_Ext: 8 EMUS_BMS
 SG_ EMUS_LoginLevel : 0|8@1+ (1,0) [0|255] "" Vector__XXX

BO_ 2578777089 EMUS_Contactor_Control_Ext: 1 HVCU
 SG_ EMUS_ContactorControl_ContactorS : 0|8@1+ (1,0) [0|255] ""  HVTU,EMUS_BMS

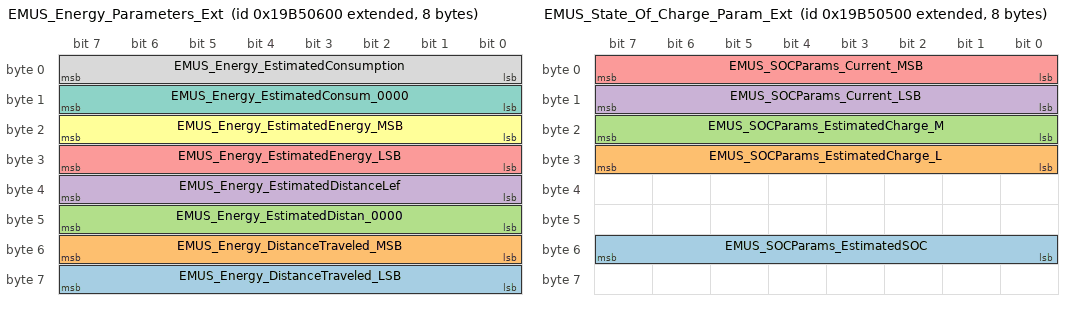
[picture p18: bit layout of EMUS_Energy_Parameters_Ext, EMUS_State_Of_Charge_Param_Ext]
BO_ 2578777600 EMUS_Energy_Parameters_Ext: 8 EMUS_BMS
 SG_ EMUS_Energy_DistanceTraveled_LSB : 56|8@1+ (1,0) [0|255] "" Vector__XXX
 SG_ EMUS_Energy_DistanceTraveled_MSB : 48|8@1+ (1,0) [0|255] "" Vector__XXX
 SG_ EMUS_Energy_EstimatedDistan_0000 : 40|8@1+ (1,0) [0|255] "" Vector__XXX
 SG_ EMUS_Energy_EstimatedDistanceLef : 32|8@1+ (1,0) [0|255] "" Vector__XXX
 SG_ EMUS_Energy_EstimatedEnergy_LSB : 24|8@1+ (1,0) [0|255] "" Vector__XXX
 SG_ EMUS_Energy_EstimatedEnergy_MSB : 16|8@1+ (1,0) [0|255] "" Vector__XXX
 SG_ EMUS_Energy_EstimatedConsum_0000 : 8|8@1+ (1,0) [0|255] "" Vector__XXX
 SG_ EMUS_Energy_EstimatedConsumption : 0|8@1+ (1,0) [0|255] "" Vector__XXX

BO_ 2578777344 EMUS_State_Of_Charge_Param_Ext: 8 EMUS_BMS
 SG_ EMUS_SOCParams_EstimatedSOC : 48|8@1+ (1,0) [0|255] ""  HVTU
 SG_ EMUS_SOCParams_EstimatedCharge_L : 24|8@1+ (1,0) [0|255] ""  HVTU
 SG_ EMUS_SOCParams_EstimatedCharge_M : 16|8@1+ (1,0) [0|255] ""  HVTU
 SG_ EMUS_SOCParams_Current_LSB : 8|8@1+ (1,0) [0|255] ""  HVTU
 SG_ EMUS_SOCParams_Current_MSB : 0|8@1+ (1,0) [0|255] ""  HVTU

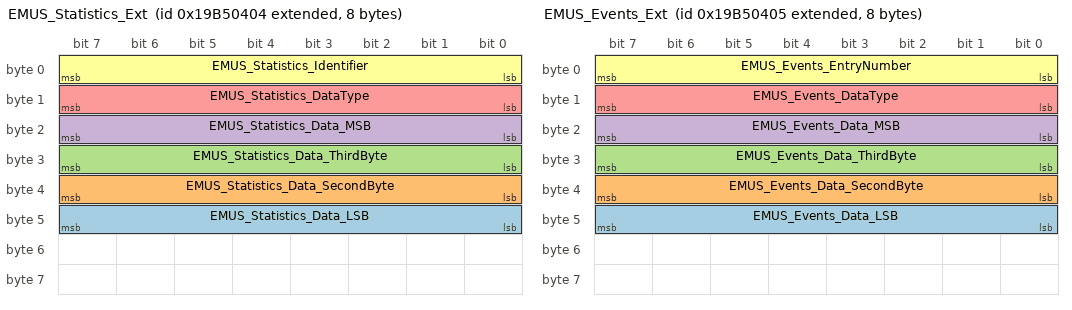
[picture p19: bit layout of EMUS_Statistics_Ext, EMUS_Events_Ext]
BO_ 2578777092 EMUS_Statistics_Ext: 8 EMUS_BMS
 SG_ EMUS_Statistics_Data_LSB : 40|8@1+ (1,0) [0|255] "" Vector__XXX
 SG_ EMUS_Statistics_Data_SecondByte : 32|8@1+ (1,0) [0|255] "" Vector__XXX
 SG_ EMUS_Statistics_Data_ThirdByte : 24|8@1+ (1,0) [0|255] "" Vector__XXX
 SG_ EMUS_Statistics_Data_MSB : 16|8@1+ (1,0) [0|255] "" Vector__XXX
 SG_ EMUS_Statistics_DataType : 8|8@1+ (1,0) [0|255] "" Vector__XXX
 SG_ EMUS_Statistics_Identifier : 0|8@1+ (1,0) [0|255] "" Vector__XXX

BO_ 2578777093 EMUS_Events_Ext: 8 EMUS_BMS
 SG_ EMUS_Events_Data_LSB : 40|8@1+ (1,0) [0|255] "" Vector__XXX
 SG_ EMUS_Events_Data_SecondByte : 32|8@1+ (1,0) [0|255] "" Vector__XXX
 SG_ EMUS_Events_Data_ThirdByte : 24|8@1+ (1,0) [0|255] "" Vector__XXX
 SG_ EMUS_Events_Data_MSB : 16|8@1+ (1,0) [0|255] "" Vector__XXX
 SG_ EMUS_Events_DataType : 8|8@1+ (1,0) [0|255] "" Vector__XXX
 SG_ EMUS_Events_EntryNumber : 0|8@1+ (1,0) [0|255] "" Vector__XXX

CM_ BO_ 401 "Transmit PDO 1 of node BrakeF with Node-ID 0x11";
CM_ SG_ 401 BrakeF_TX_SDC_Input "Sends the current value of the SDC received by BrakeF.
";
CM_ SG_ 401 BrakeF_TX_ErrorFlag "Error status of BrakeF.";
CM_ SG_ 401 BrakeF_TX_Enabled "Enable status of BrakeF.";
CM_ SG_ 401 BrakeF_TX_Status "Status signal of BrakeF.";
CM_ BO_ 465 "Receive PDO 1 of node BrakeF with Node-ID 0x11";
CM_ SG_ 465 BrakeF_RX_Engage "Engage signal for BrakeF.";
CM_ SG_ 465 BrakeF_RX_Enable "Enable signal for BrakeF.";
CM_ SG_ 465 BrakeF_RX_ErrorReset "Error reset signal for BrakeF.";
CM_ BO_ 529 "Transmit PDO 2 of node BrakeF with Node-ID 0x11";
CM_ BO_ 593 "Receive PDO 2 of node BrakeF with Node-ID 0x11";
CM_ BO_ 657 "Transmit PDO 3 of node BrakeF with Node-ID 0x11";
CM_ BO_ 721 "Receive PDO 3 of node BrakeF with Node-ID 0x11";
CM_ BO_ 785 "Transmit PDO 4 of node BrakeF with Node-ID 0x11";
CM_ BO_ 849 "Receive PDO 4 of node BrakeF with Node-ID 0x11";
CM_ BO_ 913 "Transmit PDO 5 of node BrakeF with Node-ID 0x11";
CM_ BO_ 977 "Transmit PDO 6 of node BrakeF with Node-ID 0x11";
CM_ BO_ 1105 "Transmit PDO 8 of node BrakeF with Node-ID 0x11";
CM_ BO_ 1169 "Transmit PDO 9 of node BrakeF with Node-ID 0x11";
CM_ BO_ 1233 "Transmit PDO 10 of node BrakeF with Node-ID 0x11";
CM_ BO_ 1297 "Transmit PDO 11 of node BrakeF with Node-ID 0x11";
CM_ BO_ 1361 "Transmit PDO 12 of node BrakeF with Node-ID 0x11";
CM_ BO_ 1425 "DO NOT CHANGE ANYTHING HERE!
SDO Response of node BrakeF with Node-ID 0x11";
CM_ SG_ 1425 BrakeF_OD_BrakeStatus "State of the Brakes";
CM_ SG_ 1425 BrakeF_OD_CoolingPressure "Cooling cycle Pressure";
CM_ SG_ 1425 BrakeF_OD_valveUpperTolerance "Tolerance of the lower pressure pneumatic circuit";
CM_ SG_ 1425 BrakeF_OD_commWatchdog "Max. number of ms to receive a new message";
CM_ SG_ 1425 BrakeF_OD_counterLimit "Number of cycles in the loop to measure pressure once";
CM_ SG_ 1425 BrakeF_OD_delay "Delay used in every cycle of the loop.";
CM_ SG_ 1425 BrakeF_OD_tankUpperControlLimit "Maximum pressure of tank in bar.";
CM_ SG_ 1425 BrakeF_OD_tankLowerControlLimit "Minimum pressure of tank in bar.";
CM_ SG_ 1425 BrakeF_OD_CAN2_DelayedTxMessages "Number of delayed TX messages on CAN2 because no messagebox was free.";
CM_ SG_ 1425 BrakeF_OD_CAN2_ErrorStatus "Internal error status (e.g. Error active, Error passive, Bus Off)";
CM_ SG_ 1425 BrakeF_OD_CAN2_DiscardedTxMessag "Number of discarded TX messages on CAN2 because all messageboxes were full";
CM_ SG_ 1425 BrakeF_OD_CAN2_Status "Status of CAN2.";
CM_ SG_ 1425 BrakeF_OD_CAN2_Baudrate "Baudrate of CAN.";
CM_ SG_ 1425 BrakeF_OD_CAN2_autoErrorReset "Automatic reset of errors.";
CM_ SG_ 1425 BrakeF_OD_CAN2_lastErrorCode "Last error code.";
CM_ SG_ 1425 BrakeF_OD_CAN2_RxErrCnt "Receive error count of CAN1.";
CM_ SG_ 1425 BrakeF_OD_CAN2_TxErrCnt "Transmit error count of CAN1.";
CM_ SG_ 1425 BrakeF_OD_CAN1_DelayedTxMessages "Number of delayed TX messages on CAN1 because no messagebox was free.";
CM_ SG_ 1425 BrakeF_OD_CAN1_ErrorStatus "Internal error status (e.g. Error active, Error passive, Bus Off)";
CM_ SG_ 1425 BrakeF_OD_CAN1_DiscardedTxMessag "Number of discarded TX messages on CAN1 because all messageboxes were full";
CM_ SG_ 1425 BrakeF_OD_CAN1_Status "Status of CAN1.";
CM_ SG_ 1425 BrakeF_OD_CAN1_Baudrate "Baudrate of CAN.";
CM_ SG_ 1425 BrakeF_OD_CAN1_autoErrorReset "Automatic reset of errors.";
CM_ SG_ 1425 BrakeF_OD_CAN1_lastErrorCode "Last error code.";
CM_ SG_ 1425 BrakeF_OD_CAN1_RxErrCnt "Receive error count of CAN1.";
CM_ SG_ 1425 BrakeF_OD_CAN1_TxErrCnt "Transmit error count of CAN1.";
CM_ SG_ 1425 BrakeF_OD_BuildTime "Software build time in the format HHMMSS.";
CM_ SG_ 1425 BrakeF_OD_BuildDate "Software build date in the format YYYYMMDD.";
CM_ SG_ 1425 BrakeF_OD_ChipUID2 "Seccond part of unique ID of microcontroller.";
CM_ SG_ 1425 BrakeF_OD_ChipUID1 "First part of unique ID of microcontroller.";
CM_ SG_ 1425 BrakeF_OD_SdcOut "Measurement of Shutdown Circuit Output";
CM_ SG_ 1425 BrakeF_OD_SdcIn "Measurement of Shutdown Circuit Input";
CM_ SG_ 1425 BrakeF_OD_runtime "Runtime of chip in milliseconds.";
CM_ SG_ 1425 BrakeF_OD_InputVoltage "Board supply voltage.";
CM_ SG_ 1425 BrakeF_OD_BoardTemp "Temperature of board";
CM_ SG_ 1425 BrakeF_OD_MemFree "Free memory in bytes.";
CM_ SG_ 1425 BrakeF_OD_CpuUsage "Current CPU usage in %.";
CM_ SG_ 1425 BrakeF_OD_OdEntrySendInterval "Interval for sending all readable OD entries. Sending is disabled if less than 5 ms.";
CM_ SG_ 1425 BrakeF_OD_SendOdOnBootup "Whether to send all OD entries on bootup.";
CM_ SG_ 1425 BrakeF_OD_HeartbeatInterval "Heartbeat Interval in milliseconds.";
CM_ SG_ 1425 BrakeF_OD_DbcVersion "CANzero DBC version.";
CM_ SG_ 1425 BrakeF_OD_StackVersion "CANzero stack version.";
CM_ SG_ 1425 BrakeF_OD_ProtocolVersion "CANzero Protocol Version.";
CM_ SG_ 1425 BrakeF_OD_NodeStatus "State of the node.";
CM_ SG_ 1425 BrakeF_OD_NodeID "CANzero Node-ID.";
CM_ SG_ 1425 BrakeF_SDO_RespCode "Response code of SDO access.";
CM_ SG_ 1425 BrakeF_SDO_ID "Specifies SDO-ID of BrakeF";
CM_ BO_ 1489 "DO NOT CHANGE ANYTHING HERE!
SDO Request Upload to node BrakeF with Node-ID 0x11";
CM_ SG_ 1489 BrakeF_OD_BrakeStatus "State of the Brakes";
CM_ SG_ 1489 BrakeF_OD_CoolingPressure "Cooling cycle Pressure";
CM_ SG_ 1489 BrakeF_OD_valveUpperTolerance "Tolerance of the lower pressure pneumatic circuit";
CM_ SG_ 1489 BrakeF_OD_commWatchdog "Max. number of ms to receive a new message";
CM_ SG_ 1489 BrakeF_OD_counterLimit "Number of cycles in the loop to measure pressure once";
CM_ SG_ 1489 BrakeF_OD_delay "Delay used in every cycle of the loop.";
CM_ SG_ 1489 BrakeF_OD_tankUpperControlLimit "Maximum pressure of tank in bar.";
CM_ SG_ 1489 BrakeF_OD_tankLowerControlLimit "Minimum pressure of tank in bar.";
CM_ SG_ 1489 BrakeF_OD_CAN2_DelayedTxMessages "Number of delayed TX messages on CAN2 because no messagebox was free.";
CM_ SG_ 1489 BrakeF_OD_CAN2_ErrorStatus "Internal error status (e.g. Error active, Error passive, Bus Off)";
CM_ SG_ 1489 BrakeF_OD_CAN2_DiscardedTxM_0000 "Number of discarded TX messages on CAN2 because all messageboxes were full";
CM_ SG_ 1489 BrakeF_OD_CAN2_Status "Status of CAN2.";
CM_ SG_ 1489 BrakeF_OD_CAN2_Baudrate "Baudrate of CAN.";
CM_ SG_ 1489 BrakeF_OD_CAN2_autoErrorReset "Automatic reset of errors.";
CM_ SG_ 1489 BrakeF_OD_CAN2_lastErrorCode "Last error code.";
CM_ SG_ 1489 BrakeF_OD_CAN2_RxErrCnt "Receive error count of CAN1.";
CM_ SG_ 1489 BrakeF_OD_CAN2_TxErrCnt "Transmit error count of CAN1.";
CM_ SG_ 1489 BrakeF_OD_CAN1_DelayedTxMessages "Number of delayed TX messages on CAN1 because no messagebox was free.";
CM_ SG_ 1489 BrakeF_OD_CAN1_ErrorStatus "Internal error status (e.g. Error active, Error passive, Bus Off)";
CM_ SG_ 1489 BrakeF_OD_CAN1_DiscardedTxM_0000 "Number of discarded TX messages on CAN1 because all messageboxes were full";
CM_ SG_ 1489 BrakeF_OD_CAN1_Status "Status of CAN1.";
CM_ SG_ 1489 BrakeF_OD_CAN1_Baudrate "Baudrate of CAN.";
CM_ SG_ 1489 BrakeF_OD_CAN1_autoErrorReset "Automatic reset of errors.";
CM_ SG_ 1489 BrakeF_OD_CAN1_lastErrorCode "Last error code.";
CM_ SG_ 1489 BrakeF_OD_CAN1_RxErrCnt "Receive error count of CAN1.";
CM_ SG_ 1489 BrakeF_OD_CAN1_TxErrCnt "Transmit error count of CAN1.";
CM_ SG_ 1489 BrakeF_OD_BuildTime "Software build time in the format HHMMSS.";
CM_ SG_ 1489 BrakeF_OD_BuildDate "Software build date in the format YYYYMMDD.";
CM_ SG_ 1489 BrakeF_OD_ChipUID2 "Seccond part of unique ID of microcontroller.";
CM_ SG_ 1489 BrakeF_OD_ChipUID1 "First part of unique ID of microcontroller.";
CM_ SG_ 1489 BrakeF_OD_SdcOut "Measurement of Shutdown Circuit Output";
CM_ SG_ 1489 BrakeF_OD_SdcIn "Measurement of Shutdown Circuit Input";
CM_ SG_ 1489 BrakeF_OD_runtime "Runtime of chip in milliseconds.";
CM_ SG_ 1489 BrakeF_OD_InputVoltage "Board supply voltage.";
CM_ SG_ 1489 BrakeF_OD_BoardTemp "Temperature of board";
CM_ SG_ 1489 BrakeF_OD_MemFree "Free memory in bytes.";
CM_ SG_ 1489 BrakeF_OD_CpuUsage "Current CPU usage in %.";
CM_ SG_ 1489 BrakeF_OD_OdEntrySendInterval "Interval for sending all readable OD entries. Sending is disabled if less than 5 ms.";
CM_ SG_ 1489 BrakeF_OD_SendOdOnBootup "Whether to send all OD entries on bootup.";
CM_ SG_ 1489 BrakeF_OD_HeartbeatInterval "Heartbeat Interval in milliseconds.";
CM_ SG_ 1489 BrakeF_OD_DbcVersion "CANzero DBC version.";
CM_ SG_ 1489 BrakeF_OD_StackVersion "CANzero stack version.";
CM_ SG_ 1489 BrakeF_OD_ProtocolVersion "CANzero Protocol Version.";
CM_ SG_ 1489 BrakeF_OD_NodeStatus "State of the node.";
CM_ SG_ 1489 BrakeF_OD_NodeID "CANzero Node-ID.";
CM_ SG_ 1489 BrakeF_SDO_ID "Specifies SDO-ID of BrakeF";
CM_ BO_ 1553 "DO NOT CHANGE ANYTHING HERE!
SDO Request Download from node BrakeF with Node-ID 0x11";
CM_ SG_ 1553 BrakeF_SDO_ID "Specifies SDO-ID of BrakeF";
CM_ BO_ 1809 "Heartbeat of node BrakeF with Node-ID 0x11";
CM_ SG_ 1809 BrakeF_NodeState "Heartbeat status of node BrakeF";
CM_ BO_ 1873 "Bootloader transmit from node BrakeF with Node-ID 0x11";
CM_ BO_ 1937 "Bootloader receive by node BrakeF with Node-ID 0x11";
CM_ BO_ 146 "Emergency message of node BrakeR with Node-ID 0x12";
CM_ SG_ 146 BrakeR_E5_retractUnsuccesful_ope "Instruction to retract was received, but the SDC is detected to be open";
CM_ SG_ 146 BrakeR_E4_retractUnsuccesful_not "Instruction to retract was received, but the ECU is not enabled";
CM_ SG_ 146 BrakeR_E3_retractUnsuccesful_err "Instruction to retract was received, but an error flag inhibited retraction";
CM_ SG_ 146 BrakeR_E2_commWatchdogTimeout "Communication Watchdog timeout. It took more than the time set to receive a new message from the state machine";
CM_ SG_ 146 BrakeR_E1_pressureTooLow "Pressure tank has a lower value than the provided LowerControlLimit";
CM_ SG_ 146 BrakeR_E0_pressureTooHigh "Pressure tank has a higher value than the provided UpperControlLimit";
CM_ SG_ 146 BrakeR_W3_externalError "SDC reading indicates it's open, but there's no internal error in the ECU";
CM_ SG_ 146 BrakeR_W2_enableWithAnError "The ECU was enabled with an error flag";
CM_ SG_ 146 BrakeR_W1_highPressureRetracting "Pressure higher than desired was measured in the acting chamber";
CM_ SG_ 146 BrakeR_W0_highPressureActingCham "Pressure higher than desired was measured in the acting chamber";
CM_ BO_ 402 "Transmit PDO 1 of node BrakeR with Node-ID 0x12";
CM_ SG_ 402 BrakeR_TX_SDC_Input "Sends the current value of the SDC received by BrakeR.
";
CM_ SG_ 402 BrakeR_TX_ErrorFlag "Error status of BrakeR.";
CM_ SG_ 402 BrakeR_TX_Enabled "Enable status of BrakeR.";
CM_ SG_ 402 BrakeR_TX_Status "Status signal of BrakeR.";
CM_ BO_ 466 "Receive PDO 1 of node BrakeR with Node-ID 0x12";
CM_ SG_ 466 BrakeR_RX_Engage "Engage signal for BrakeR.";
CM_ SG_ 466 BrakeR_RX_Enable "Enable signal for BrakeR.";
CM_ SG_ 466 BrakeR_RX_ErrorReset "Error reset signal for BrakeR.";
CM_ BO_ 530 "Transmit PDO 2 of node BrakeR with Node-ID 0x12";
CM_ BO_ 594 "Receive PDO 2 of node BrakeR with Node-ID 0x12";
CM_ BO_ 658 "Transmit PDO 3 of node BrakeR with Node-ID 0x12";
CM_ BO_ 722 "Receive PDO 3 of node BrakeR with Node-ID 0x12";
CM_ BO_ 786 "Transmit PDO 4 of node BrakeR with Node-ID 0x12";
CM_ BO_ 850 "Receive PDO 4 of node BrakeR with Node-ID 0x12";
CM_ BO_ 914 "Transmit PDO 5 of node BrakeR with Node-ID 0x12";
CM_ BO_ 978 "Transmit PDO 6 of node BrakeR with Node-ID 0x12";
CM_ BO_ 1042 "Transmit PDO 7 of node BrakeR with Node-ID 0x12";
CM_ BO_ 1106 "Transmit PDO 8 of node BrakeR with Node-ID 0x12";
CM_ BO_ 1170 "Transmit PDO 9 of node BrakeR with Node-ID 0x12";
CM_ BO_ 1234 "Transmit PDO 10 of node BrakeR with Node-ID 0x12";
CM_ BO_ 1298 "Transmit PDO 11 of node BrakeR with Node-ID 0x12";
CM_ BO_ 1362 "Transmit PDO 12 of node BrakeR with Node-ID 0x12";
CM_ BO_ 1426 "DO NOT CHANGE ANYTHING HERE!
SDO Response of node BrakeR with Node-ID 0x12";
CM_ SG_ 1426 BrakeR_OD_valveUpperTolerance "Tolerance of the lower pressure pneumatic circuit";
CM_ SG_ 1426 BrakeR_OD_commWatchdog "Max. number of ms to receive a new message";
CM_ SG_ 1426 BrakeR_OD_counterLimit "Number of cycles in the loop to measure pressure once";
CM_ SG_ 1426 BrakeR_OD_delay "Delay used in every cycle of the loop.";
CM_ SG_ 1426 BrakeR_OD_tankUpperControlLimit "Maximum pressure of tank in bar.";
CM_ SG_ 1426 BrakeR_OD_tankLowerControlLimit "Minimum pressure of tank in bar.";
CM_ SG_ 1426 BrakeR_OD_CAN2_DelayedTxMessages "Number of delayed TX messages on CAN2 because no messagebox was free.";
CM_ SG_ 1426 BrakeR_OD_CAN2_ErrorStatus "Internal error status (e.g. Error active, Error passive, Bus Off)";
CM_ SG_ 1426 BrakeR_OD_CAN2_DiscardedTxMessag "Number of discarded TX messages on CAN2 because all messageboxes were full";
CM_ SG_ 1426 BrakeR_OD_CAN2_Status "Status of CAN2.";
CM_ SG_ 1426 BrakeR_OD_CAN2_Baudrate "Baudrate of CAN.";
CM_ SG_ 1426 BrakeR_OD_CAN2_autoErrorReset "Automatic reset of errors.";
CM_ SG_ 1426 BrakeR_OD_CAN2_lastErrorCode "Last error code.";
CM_ SG_ 1426 BrakeR_OD_CAN2_RxErrCnt "Receive error count of CAN1.";
CM_ SG_ 1426 BrakeR_OD_CAN2_TxErrCnt "Transmit error count of CAN1.";
CM_ SG_ 1426 BrakeR_OD_CAN1_DelayedTxMessages "Number of delayed TX messages on CAN1 because no messagebox was free.";
CM_ SG_ 1426 BrakeR_OD_CAN1_ErrorStatus "Internal error status (e.g. Error active, Error passive, Bus Off)";
CM_ SG_ 1426 BrakeR_OD_CAN1_DiscardedTxMessag "Number of discarded TX messages on CAN1 because all messageboxes were full";
CM_ SG_ 1426 BrakeR_OD_CAN1_Status "Status of CAN1.";
CM_ SG_ 1426 BrakeR_OD_CAN1_Baudrate "Baudrate of CAN.";
CM_ SG_ 1426 BrakeR_OD_CAN1_autoErrorReset "Automatic reset of errors.";
CM_ SG_ 1426 BrakeR_OD_CAN1_lastErrorCode "Last error code.";
CM_ SG_ 1426 BrakeR_OD_CAN1_RxErrCnt "Receive error count of CAN1.";
CM_ SG_ 1426 BrakeR_OD_CAN1_TxErrCnt "Transmit error count of CAN1.";
CM_ SG_ 1426 BrakeR_OD_BuildTime "Software build time in the format HHMMSS.";
CM_ SG_ 1426 BrakeR_OD_BuildDate "Software build date in the format YYYYMMDD.";
CM_ SG_ 1426 BrakeR_OD_ChipUID2 "Seccond part of unique ID of microcontroller.";
CM_ SG_ 1426 BrakeR_OD_ChipUID1 "First part of unique ID of microcontroller.";
CM_ SG_ 1426 BrakeR_OD_SdcOut "Measurement of Shutdown Circuit Output";
CM_ SG_ 1426 BrakeR_OD_SdcIn "Measurement of Shutdown Circuit Input";
CM_ SG_ 1426 BrakeR_OD_runtime "Runtime of chip in milliseconds.";
CM_ SG_ 1426 BrakeR_OD_InputVoltage "Board supply voltage.";
CM_ SG_ 1426 BrakeR_OD_BoardTemp "Temperature of board";
CM_ SG_ 1426 BrakeR_OD_MemFree "Free memory in bytes.";
CM_ SG_ 1426 BrakeR_OD_CpuUsage "Current CPU usage in %.";
CM_ SG_ 1426 BrakeR_OD_OdEntrySendInterval "Interval for sending all readable OD entries. Sending is disabled if less than 5 ms.";
CM_ SG_ 1426 BrakeR_OD_SendOdOnBootup "Whether to send all OD entries on bootup.";
CM_ SG_ 1426 BrakeR_OD_HeartbeatInterval "Heartbeat Interval in milliseconds.";
CM_ SG_ 1426 BrakeR_OD_DbcVersion "CANzero DBC version.";
CM_ SG_ 1426 BrakeR_OD_StackVersion "CANzero stack version.";
CM_ SG_ 1426 BrakeR_OD_ProtocolVersion "CANzero Protocol Version.";
CM_ SG_ 1426 BrakeR_OD_NodeStatus "State of the node.";
CM_ SG_ 1426 BrakeR_OD_NodeID "CANzero Node-ID.";
CM_ SG_ 1426 BrakeR_SDO_RespCode "Response code of SDO access.";
CM_ SG_ 1426 BrakeR_SDO_ID "Specifies SDO-ID of BrakeR";
CM_ BO_ 1490 "DO NOT CHANGE ANYTHING HERE!
SDO Request Upload to node BrakeR with Node-ID 0x12";
CM_ SG_ 1490 BrakeR_OD_valveUpperTolerance "Tolerance of the lower pressure pneumatic circuit";
CM_ SG_ 1490 BrakeR_OD_commWatchdog "Max. number of ms to receive a new message";
CM_ SG_ 1490 BrakeR_OD_counterLimit "Number of cycles in the loop to measure pressure once";
CM_ SG_ 1490 BrakeR_OD_delay "Delay used in every cycle of the loop.";
CM_ SG_ 1490 BrakeR_OD_tankUpperControlLimit "Maximum pressure of tank in bar.";
CM_ SG_ 1490 BrakeR_OD_tankLowerControlLimit "Minimum pressure of tank in bar.";
CM_ SG_ 1490 BrakeR_OD_CAN2_DelayedTxMessages "Number of delayed TX messages on CAN2 because no messagebox was free.";
CM_ SG_ 1490 BrakeR_OD_CAN2_ErrorStatus "Internal error status (e.g. Error active, Error passive, Bus Off)";
CM_ SG_ 1490 BrakeR_OD_CAN2_DiscardedTxM_0000 "Number of discarded TX messages on CAN2 because all messageboxes were full";
CM_ SG_ 1490 BrakeR_OD_CAN2_Status "Status of CAN2.";
CM_ SG_ 1490 BrakeR_OD_CAN2_Baudrate "Baudrate of CAN.";
CM_ SG_ 1490 BrakeR_OD_CAN2_autoErrorReset "Automatic reset of errors.";
CM_ SG_ 1490 BrakeR_OD_CAN2_lastErrorCode "Last error code.";
CM_ SG_ 1490 BrakeR_OD_CAN2_RxErrCnt "Receive error count of CAN1.";
CM_ SG_ 1490 BrakeR_OD_CAN2_TxErrCnt "Transmit error count of CAN1.";
CM_ SG_ 1490 BrakeR_OD_CAN1_DelayedTxMessages "Number of delayed TX messages on CAN1 because no messagebox was free.";
CM_ SG_ 1490 BrakeR_OD_CAN1_ErrorStatus "Internal error status (e.g. Error active, Error passive, Bus Off)";
CM_ SG_ 1490 BrakeR_OD_CAN1_DiscardedTxM_0000 "Number of discarded TX messages on CAN1 because all messageboxes were full";
CM_ SG_ 1490 BrakeR_OD_CAN1_Status "Status of CAN1.";
CM_ SG_ 1490 BrakeR_OD_CAN1_Baudrate "Baudrate of CAN.";
CM_ SG_ 1490 BrakeR_OD_CAN1_autoErrorReset "Automatic reset of errors.";
CM_ SG_ 1490 BrakeR_OD_CAN1_lastErrorCode "Last error code.";
CM_ SG_ 1490 BrakeR_OD_CAN1_RxErrCnt "Receive error count of CAN1.";
CM_ SG_ 1490 BrakeR_OD_CAN1_TxErrCnt "Transmit error count of CAN1.";
CM_ SG_ 1490 BrakeR_OD_BuildTime "Software build time in the format HHMMSS.";
CM_ SG_ 1490 BrakeR_OD_BuildDate "Software build date in the format YYYYMMDD.";
CM_ SG_ 1490 BrakeR_OD_ChipUID2 "Seccond part of unique ID of microcontroller.";
CM_ SG_ 1490 BrakeR_OD_ChipUID1 "First part of unique ID of microcontroller.";
CM_ SG_ 1490 BrakeR_OD_SdcOut "Measurement of Shutdown Circuit Output";
CM_ SG_ 1490 BrakeR_OD_SdcIn "Measurement of Shutdown Circuit Input";
CM_ SG_ 1490 BrakeR_OD_runtime "Runtime of chip in milliseconds.";
CM_ SG_ 1490 BrakeR_OD_InputVoltage "Board supply voltage.";
CM_ SG_ 1490 BrakeR_OD_BoardTemp "Temperature of board";
CM_ SG_ 1490 BrakeR_OD_MemFree "Free memory in bytes.";
CM_ SG_ 1490 BrakeR_OD_CpuUsage "Current CPU usage in %.";
CM_ SG_ 1490 BrakeR_OD_OdEntrySendInterval "Interval for sending all readable OD entries. Sending is disabled if less than 5 ms.";
CM_ SG_ 1490 BrakeR_OD_SendOdOnBootup "Whether to send all OD entries on bootup.";
CM_ SG_ 1490 BrakeR_OD_HeartbeatInterval "Heartbeat Interval in milliseconds.";
CM_ SG_ 1490 BrakeR_OD_DbcVersion "CANzero DBC version.";
CM_ SG_ 1490 BrakeR_OD_StackVersion "CANzero stack version.";
CM_ SG_ 1490 BrakeR_OD_ProtocolVersion "CANzero Protocol Version.";
CM_ SG_ 1490 BrakeR_OD_NodeStatus "State of the node.";
CM_ SG_ 1490 BrakeR_OD_NodeID "CANzero Node-ID.";
CM_ SG_ 1490 BrakeR_SDO_ID "Specifies SDO-ID of BrakeR";
CM_ BO_ 1554 "DO NOT CHANGE ANYTHING HERE!
SDO Request Download from node BrakeR with Node-ID 0x12";
CM_ SG_ 1554 BrakeR_SDO_ID "Specifies SDO-ID of BrakeR";
CM_ BO_ 1810 "Heartbeat of node BrakeR with Node-ID 0x12";
CM_ SG_ 1810 BrakeR_NodeState "Heartbeat status of node BrakeR";
CM_ BO_ 1874 "Bootloader transmit from node BrakeR with Node-ID 0x12";
CM_ BO_ 1938 "Bootloader receive by node BrakeR with Node-ID 0x12";
CM_ BO_ 154 "Emergency message of node PDU with Node-ID 0x1A";
CM_ SG_ 154 PDU_E4_watchdogStateMachine "The watchdog for the state machine timed out.";
CM_ SG_ 154 PDU_E3_batterTempCritical "Temperature limit of the battery reached.";
CM_ SG_ 154 PDU_E2_batteryOvercurrent "Overcurrent limit of the battery reached.";
CM_ SG_ 154 PDU_E1_batterVoltageCritical "Error when battery voltage is getting critical low. Pod will be shut down";
CM_ SG_ 154 PDU_E0_OtherError "Other error.";
CM_ SG_ 154 PDU_W2_batterTempHigh "Warning when battery temperature is rising high";
CM_ SG_ 154 PDU_W1_batterVoltageLow "Warning when battery voltage is getting low";
CM_ SG_ 154 PDU_W0_OtherWarning "Other warning.";
CM_ BO_ 410 "Transmit PDO 1 of node PDU with Node-ID 0x1A";
CM_ SG_ 410 PDU_TX_PEHWEnabled "PE Hardware Enable status signal of PDU.";
CM_ SG_ 410 PDU_TX_ErrorFlag "Error status of PDU.";
CM_ SG_ 410 PDU_TX_Enabled "Enable status of PDU.";
CM_ BO_ 474 "Control message of the PDU sent by the State Machine.";
CM_ SG_ 474 PDU_RX_PEHWEnable "PE Hardware Enable signal of PDU.";
CM_ SG_ 474 PDU_RX_ErrorReset "Error reset signal for PDU.";
CM_ SG_ 474 PDU_RX_Enable "Enable signal for PDU.";
CM_ BO_ 538 "Transmit PDO 2 of node PDU with Node-ID 0x1A";
CM_ BO_ 602 "Dutycycle for the channels of the PDU that support PWM.";
CM_ BO_ 666 "Transmit PDO 3 of node PDU with Node-ID 0x1A";
CM_ BO_ 730 "Receive PDO 3 of node PDU with Node-ID 0x1A";
CM_ BO_ 794 "Transmit PDO 4 of node PDU with Node-ID 0x1A";
CM_ BO_ 858 "Receive PDO 4 of node PDU with Node-ID 0x1A";
CM_ BO_ 922 "Transmit PDO 5 of node PDU with Node-ID 0x1A";
CM_ BO_ 986 "Transmit PDO 6 of node PDU with Node-ID 0x1A";
CM_ BO_ 1050 "Transmit PDO 7 of node PDU with Node-ID 0x1A";
CM_ BO_ 1114 "Transmit PDO 8 of node PDU with Node-ID 0x1A";
CM_ BO_ 1178 "Transmit PDO 9 of node PDU with Node-ID 0x1A";
CM_ BO_ 1242 "Transmit PDO 10 of node PDU with Node-ID 0x1A";
CM_ BO_ 1306 "Transmit PDO 11 of node PDU with Node-ID 0x1A";
CM_ BO_ 1370 "Transmit PDO 12 of node PDU with Node-ID 0x1A";
CM_ BO_ 1434 "DO NOT CHANGE ANYTHING HERE!
SDO Response of node PDU with Node-ID 0x1A";
CM_ SG_ 1434 PDU_OD_CoolingPumpEnabled "Enable the Cooling Pump.";
CM_ SG_ 1434 PDU_OD_LedCommands "Commands from Telemetry to leds";
CM_ SG_ 1434 PDU_OD_projectXXEnabled "Enable the Project XX leds.";
CM_ SG_ 1434 PDU_OD_watchdogTimeout "Timeout for the state machine watchdog in milliseconds.";
CM_ SG_ 1434 PDU_OD_statusSendInterval "Sending intervall for the status in milliseconds.";
CM_ SG_ 1434 PDU_OD_currentReadInterval "Sampling time in millisecconds for reading the currents.";
CM_ SG_ 1434 PDU_OD_batteryOvercurrent "Overcurrent limit in ampere of the low voltage battery.";
CM_ SG_ 1434 PDU_OD_overTempCritical "Error when battery temperature is getting critical high. Pod will be shut down";
CM_ SG_ 1434 PDU_OD_overTempWarn "Warning when battery temperature is getting high";
CM_ SG_ 1434 PDU_OD_batterVoltageCritical "Error when battery voltage is getting critical low. Pod will be shut down";
CM_ SG_ 1434 PDU_OD_batterVoltageLow "Warning when battery voltage is getting low";
CM_ SG_ 1434 PDU_OD_CAN2_DelayedTxMessages "Number of delayed TX messages on CAN2 because no messagebox was free.";
CM_ SG_ 1434 PDU_OD_CAN2_ErrorStatus "Internal error status (e.g. Error active, Error passive, Bus Off)";
CM_ SG_ 1434 PDU_OD_CAN2_DiscardedTxMessages "Number of discarded TX messages on CAN2 because all messageboxes were full";
CM_ SG_ 1434 PDU_OD_CAN2_Status "Status of CAN2.";
CM_ SG_ 1434 PDU_OD_CAN2_Baudrate "Baudrate of CAN.";
CM_ SG_ 1434 PDU_OD_CAN2_autoErrorReset "Automatic reset of errors.";
CM_ SG_ 1434 PDU_OD_CAN2_lastErrorCode "Last error code.";
CM_ SG_ 1434 PDU_OD_CAN2_RxErrCnt "Receive error count of CAN1.";
CM_ SG_ 1434 PDU_OD_CAN2_TxErrCnt "Transmit error count of CAN1.";
CM_ SG_ 1434 PDU_OD_CAN1_DelayedTxMessages "Number of delayed TX messages on CAN1 because no messagebox was free.";
CM_ SG_ 1434 PDU_OD_CAN1_ErrorStatus "Internal error status (e.g. Error active, Error passive, Bus Off)";
CM_ SG_ 1434 PDU_OD_CAN1_DiscardedTxMessages "Number of discarded TX messages on CAN1 because all messageboxes were full";
CM_ SG_ 1434 PDU_OD_CAN1_Status "Status of CAN1.";
CM_ SG_ 1434 PDU_OD_CAN1_Baudrate "Baudrate of CAN.";
CM_ SG_ 1434 PDU_OD_CAN1_autoErrorReset "Automatic reset of errors.";
CM_ SG_ 1434 PDU_OD_CAN1_lastErrorCode "Last error code.";
CM_ SG_ 1434 PDU_OD_CAN1_RxErrCnt "Receive error count of CAN1.";
CM_ SG_ 1434 PDU_OD_CAN1_TxErrCnt "Transmit error count of CAN1.";
CM_ SG_ 1434 PDU_OD_BuildTime "Software build time in the format HHMMSS.";
CM_ SG_ 1434 PDU_OD_BuildDate "Software build date in the format YYYYMMDD.";
CM_ SG_ 1434 PDU_OD_ChipUID2 "Seccond part of unique ID of microcontroller.";
CM_ SG_ 1434 PDU_OD_ChipUID1 "First part of unique ID of microcontroller.";
CM_ SG_ 1434 PDU_OD_SdcOut "Measurement of Shutdown Circuit Output";
CM_ SG_ 1434 PDU_OD_SdcIn "Measurement of Shutdown Circuit Input";
CM_ SG_ 1434 PDU_OD_runtime "Runtime of chip in milliseconds.";
CM_ SG_ 1434 PDU_OD_InputVoltage "Board supply voltage.";
CM_ SG_ 1434 PDU_OD_BoardTemp "Temperature of board";
CM_ SG_ 1434 PDU_OD_MemFree "Free memory in bytes.";
CM_ SG_ 1434 PDU_OD_CpuUsage "Current CPU usage in %.";
CM_ SG_ 1434 PDU_OD_OdEntrySendInterval "Interval for sending all readable OD entries. Sending is disabled if less than 5 ms.";
CM_ SG_ 1434 PDU_OD_SendOdOnBootup "Whether to send all OD entries on bootup.";
CM_ SG_ 1434 PDU_OD_HeartbeatInterval "Heartbeat Interval in milliseconds.";
CM_ SG_ 1434 PDU_OD_DbcVersion "CANzero DBC version.";
CM_ SG_ 1434 PDU_OD_StackVersion "CANzero stack version.";
CM_ SG_ 1434 PDU_OD_ProtocolVersion "CANzero Protocol Version.";
CM_ SG_ 1434 PDU_OD_NodeStatus "State of the node.";
CM_ SG_ 1434 PDU_OD_NodeID "CANzero Node-ID.";
CM_ SG_ 1434 PDU_SDO_RespCode "Response code of SDO access.";
CM_ SG_ 1434 PDU_SDO_ID "Specifies SDO-ID of PDU";
CM_ BO_ 1498 "DO NOT CHANGE ANYTHING HERE!
SDO Request Upload to node PDU with Node-ID 0x1A";
CM_ SG_ 1498 PDU_OD_CoolingPumpEnabled "Enable the Cooling Pump.";
CM_ SG_ 1498 PDU_OD_LedCommands "Commands from Telemetry to leds";
CM_ SG_ 1498 PDU_OD_projectXXEnabled "Enable the Project XX leds.";
CM_ SG_ 1498 PDU_OD_watchdogTimeout "Timeout for the state machine watchdog in milliseconds.";
CM_ SG_ 1498 PDU_OD_statusSendInterval "Sending intervall for the status in milliseconds.";
CM_ SG_ 1498 PDU_OD_currentReadInterval "Sampling time in millisecconds for reading the currents.";
CM_ SG_ 1498 PDU_OD_batteryOvercurrent "Overcurrent limit in ampere of the low voltage battery.";
CM_ SG_ 1498 PDU_OD_overTempCritical "Error when battery temperature is getting critical high. Pod will be shut down";
CM_ SG_ 1498 PDU_OD_overTempWarn "Warning when battery temperature is getting high";
CM_ SG_ 1498 PDU_OD_batterVoltageCritical "Error when battery voltage is getting critical low. Pod will be shut down";
CM_ SG_ 1498 PDU_OD_batterVoltageLow "Warning when battery voltage is getting low";
CM_ SG_ 1498 PDU_OD_CAN2_DelayedTxMessages "Number of delayed TX messages on CAN2 because no messagebox was free.";
CM_ SG_ 1498 PDU_OD_CAN2_ErrorStatus "Internal error status (e.g. Error active, Error passive, Bus Off)";
CM_ SG_ 1498 PDU_OD_CAN2_DiscardedTxMessages "Number of discarded TX messages on CAN2 because all messageboxes were full";
CM_ SG_ 1498 PDU_OD_CAN2_Status "Status of CAN2.";
CM_ SG_ 1498 PDU_OD_CAN2_Baudrate "Baudrate of CAN.";
CM_ SG_ 1498 PDU_OD_CAN2_autoErrorReset "Automatic reset of errors.";
CM_ SG_ 1498 PDU_OD_CAN2_lastErrorCode "Last error code.";
CM_ SG_ 1498 PDU_OD_CAN2_RxErrCnt "Receive error count of CAN1.";
CM_ SG_ 1498 PDU_OD_CAN2_TxErrCnt "Transmit error count of CAN1.";
CM_ SG_ 1498 PDU_OD_CAN1_DelayedTxMessages "Number of delayed TX messages on CAN1 because no messagebox was free.";
CM_ SG_ 1498 PDU_OD_CAN1_ErrorStatus "Internal error status (e.g. Error active, Error passive, Bus Off)";
CM_ SG_ 1498 PDU_OD_CAN1_DiscardedTxMessages "Number of discarded TX messages on CAN1 because all messageboxes were full";
CM_ SG_ 1498 PDU_OD_CAN1_Status "Status of CAN1.";
CM_ SG_ 1498 PDU_OD_CAN1_Baudrate "Baudrate of CAN.";
CM_ SG_ 1498 PDU_OD_CAN1_autoErrorReset "Automatic reset of errors.";
CM_ SG_ 1498 PDU_OD_CAN1_lastErrorCode "Last error code.";
CM_ SG_ 1498 PDU_OD_CAN1_RxErrCnt "Receive error count of CAN1.";
CM_ SG_ 1498 PDU_OD_CAN1_TxErrCnt "Transmit error count of CAN1.";
CM_ SG_ 1498 PDU_OD_BuildTime "Software build time in the format HHMMSS.";
CM_ SG_ 1498 PDU_OD_BuildDate "Software build date in the format YYYYMMDD.";
CM_ SG_ 1498 PDU_OD_ChipUID2 "Seccond part of unique ID of microcontroller.";
CM_ SG_ 1498 PDU_OD_ChipUID1 "First part of unique ID of microcontroller.";
CM_ SG_ 1498 PDU_OD_SdcOut "Measurement of Shutdown Circuit Output";
CM_ SG_ 1498 PDU_OD_SdcIn "Measurement of Shutdown Circuit Input";
CM_ SG_ 1498 PDU_OD_runtime "Runtime of chip in milliseconds.";
CM_ SG_ 1498 PDU_OD_InputVoltage "Board supply voltage.";
CM_ SG_ 1498 PDU_OD_BoardTemp "Temperature of board";
CM_ SG_ 1498 PDU_OD_MemFree "Free memory in bytes.";
CM_ SG_ 1498 PDU_OD_CpuUsage "Current CPU usage in %.";
CM_ SG_ 1498 PDU_OD_OdEntrySendInterval "Interval for sending all readable OD entries. Sending is disabled if less than 5 ms.";
CM_ SG_ 1498 PDU_OD_SendOdOnBootup "Whether to send all OD entries on bootup.";
CM_ SG_ 1498 PDU_OD_HeartbeatInterval "Heartbeat Interval in milliseconds.";
CM_ SG_ 1498 PDU_OD_DbcVersion "CANzero DBC version.";
CM_ SG_ 1498 PDU_OD_StackVersion "CANzero stack version.";
CM_ SG_ 1498 PDU_OD_ProtocolVersion "CANzero Protocol Version.";
CM_ SG_ 1498 PDU_OD_NodeStatus "State of the node.";
CM_ SG_ 1498 PDU_OD_NodeID "CANzero Node-ID.";
CM_ SG_ 1498 PDU_SDO_ID "Specifies SDO-ID of PDU";
CM_ BO_ 1562 "DO NOT CHANGE ANYTHING HERE!
SDO Request Download from node PDU with Node-ID 0x1A";
CM_ SG_ 1562 PDU_SDO_ID "Specifies SDO-ID of PDU";
CM_ BO_ 1818 "Heartbeat of node PDU with Node-ID 0x1A";
CM_ SG_ 1818 PDU_NodeState "Heartbeat status of node PDU";
CM_ BO_ 1882 "Bootloader transmit from node PDU with Node-ID 0x1A";
CM_ BO_ 1946 "Bootloader receive by node PDU with Node-ID 0x1A";
CM_ BO_ 138 "Emergency message of node HVCU with Node-ID 0xA";
CM_ SG_ 138 HVCU_E19_ChargingModeError "Change to Charging Mode is only allowed in IDLE";
CM_ SG_ 138 HVCU_E18_SDCSwitchError "HVCU SDC switch is off, but SDC is active or not possible to close the Shutdown Circuit";
CM_ SG_ 138 HVCU_E17_ControlMessageTimeout "No control message from State Machine";
CM_ SG_ 138 HVCU_E16_NoEnable "Enable Signal not avaliable";
CM_ SG_ 138 HVCU_E15_SDCOpen "Shutdown Circuit is open";
CM_ SG_ 138 HVCU_E14_HVMPError "Currentflow trough High Voltage Measuring Point";
CM_ SG_ 138 HVCU_E13_BIR4Error "HIGH VOLTAGE! Physical state and electrical control is different";
CM_ SG_ 138 HVCU_E12_BIR3Error "HIGH VOLTAGE! Physical state and electrical control is different";
CM_ SG_ 138 HVCU_E11_BIR2Error "HIGH VOLTAGE! Physical state and electrical control is different";
CM_ SG_ 138 HVCU_E10_BIR1Error "HIGH VOLTAGE! Physical state and electrical control is different";
CM_ SG_ 138 HVCU_E9_HVSLError "High Voltage Active Light is faulty";
CM_ SG_ 138 HVCU_E8_VoltageMeasuring "Invalid Measuring. Check HVD";
CM_ SG_ 138 HVCU_E7_BALError "Battery Active Light is faulty";
CM_ SG_ 138 HVCU_E6_DischargeError "Discharge circuit is active even though it's not supposed to or Discharge Disable Signal is wrong.";
CM_ SG_ 138 HVCU_E5_DischargeTimeout "HIGH VOLTAGE! Discharging takes too long";
CM_ SG_ 138 HVCU_E4_BMSPermissionMissing "No BMS Permission to close the Relays";
CM_ SG_ 138 HVCU_E3_PrechargeError "Check the Fuses and Relays";
CM_ SG_ 138 HVCU_E2_BMSError "BMS Error";
CM_ SG_ 138 HVCU_E1_IMDError "Isolation Resistance too low or other IMD Error";
CM_ SG_ 138 HVCU_E0_OtherError "Other error.";
CM_ SG_ 138 HVCU_W8_ChargingMode "Charging Mode active";
CM_ SG_ 138 HVCU_W7_IsolationResistanceLow "Isolation Resistance under 500 kOhm";
CM_ SG_ 138 HVCU_W6_Bir4On "Battery Relay 4 is closed";
CM_ SG_ 138 HVCU_W5_Bir3On "Battery Relay 3 is closed";
CM_ SG_ 138 HVCU_W4_Bir2On "Battery Relay 2 is closed";
CM_ SG_ 138 HVCU_W3_Bir1On "Battery Relay 1 is closed";
CM_ SG_ 138 HVCU_W2_PreChargeOn "Pre-Charge Relay is cloesd";
CM_ SG_ 138 HVCU_W1_HighVoltage "HIGH VOLTAGE ACTIVE";
CM_ SG_ 138 HVCU_W0_OtherWarning "Other warning.";
CM_ BO_ 394 "Transmit PDO 1 of node HVCU with Node-ID 0xA";
CM_ SG_ 394 HVCU_TX_Enabled "Enable status of HVCU.";
CM_ SG_ 394 HVCU_TX_ErrorFlag "Error status of HVCU.";
CM_ SG_ 394 HVCU_TX_Status "HVCU status signal.";
CM_ SG_ 394 HVCU_TX_InternalStatus "HVCU internal status signal. For Debug.";
CM_ BO_ 458 "Receive PDO 1 of node HVCU with Node-ID 0xA";
CM_ SG_ 458 HVCU_RX_Charging "HVCU Charging signal for HV system.";
CM_ SG_ 458 HVCU_RX_ErrorReset "Error reset signal for HVCU.";
CM_ SG_ 458 HVCU_RX_Activate "HVCU Activate signal for HV system.";
CM_ SG_ 458 HVCU_RX_Enable "Enable signal for HVCU.";
CM_ BO_ 522 "Transmit PDO 2 of node HVCU with Node-ID 0xA";
CM_ BO_ 586 "Receive PDO 2 of node HVCU with Node-ID 0xA";
CM_ BO_ 650 "Transmit PDO 3 of node HVCU with Node-ID 0xA";
CM_ BO_ 714 "Receive PDO 3 of node HVCU with Node-ID 0xA";
CM_ BO_ 778 "Transmit PDO 4 of node HVCU with Node-ID 0xA";
CM_ BO_ 842 "Receive PDO 4 of node HVCU with Node-ID 0xA";
CM_ BO_ 906 "Transmit PDO 5 of node HVCU with Node-ID 0xA";
CM_ BO_ 970 "Transmit PDO 6 of node HVCU with Node-ID 0xA";
CM_ BO_ 1034 "Transmit PDO 7 of node HVCU with Node-ID 0xA";
CM_ BO_ 1098 "Transmit PDO 8 of node HVCU with Node-ID 0xA";
CM_ BO_ 1162 "Transmit PDO 9 of node HVCU with Node-ID 0xA";
CM_ BO_ 1226 "Transmit PDO 10 of node HVCU with Node-ID 0xA";
CM_ BO_ 1290 "Transmit PDO 11 of node HVCU with Node-ID 0xA";
CM_ BO_ 1354 "Transmit PDO 12 of node HVCU with Node-ID 0xA";
CM_ BO_ 1418 "DO NOT CHANGE ANYTHING HERE!
SDO Response of node HVCU with Node-ID 0xA";
CM_ SG_ 1418 HVCU_OD_CAN2_DelayedTxMessages "Number of delayed TX messages on CAN2 because no messagebox was free.";
CM_ SG_ 1418 HVCU_OD_CAN2_ErrorStatus "Internal error status (e.g. Error active, Error passive, Bus Off)";
CM_ SG_ 1418 HVCU_OD_CAN2_DiscardedTxMessages "Number of discarded TX messages on CAN2 because all messageboxes were full";
CM_ SG_ 1418 HVCU_OD_CAN2_Status "Status of CAN2.";
CM_ SG_ 1418 HVCU_OD_CAN2_Baudrate "Baudrate of CAN.";
CM_ SG_ 1418 HVCU_OD_CAN2_autoErrorReset "Automatic reset of errors.";
CM_ SG_ 1418 HVCU_OD_CAN2_lastErrorCode "Last error code.";
CM_ SG_ 1418 HVCU_OD_CAN2_RxErrCnt "Receive error count of CAN1.";
CM_ SG_ 1418 HVCU_OD_CAN2_TxErrCnt "Transmit error count of CAN1.";
CM_ SG_ 1418 HVCU_OD_CAN1_DelayedTxMessages "Number of delayed TX messages on CAN1 because no messagebox was free.";
CM_ SG_ 1418 HVCU_OD_CAN1_ErrorStatus "Internal error status (e.g. Error active, Error passive, Bus Off)";
CM_ SG_ 1418 HVCU_OD_CAN1_DiscardedTxMessages "Number of discarded TX messages on CAN1 because all messageboxes were full";
CM_ SG_ 1418 HVCU_OD_CAN1_Status "Status of CAN1.";
CM_ SG_ 1418 HVCU_OD_CAN1_Baudrate "Baudrate of CAN.";
CM_ SG_ 1418 HVCU_OD_CAN1_autoErrorReset "Automatic reset of errors.";
CM_ SG_ 1418 HVCU_OD_CAN1_lastErrorCode "Last error code.";
CM_ SG_ 1418 HVCU_OD_CAN1_RxErrCnt "Receive error count of CAN1.";
CM_ SG_ 1418 HVCU_OD_CAN1_TxErrCnt "Transmit error count of CAN1.";
CM_ SG_ 1418 HVCU_OD_BuildTime "Software build time in the format HHMMSS.";
CM_ SG_ 1418 HVCU_OD_BuildDate "Software build date in the format YYYYMMDD.";
CM_ SG_ 1418 HVCU_OD_ChipUID2 "Seccond part of unique ID of microcontroller.";
CM_ SG_ 1418 HVCU_OD_ChipUID1 "First part of unique ID of microcontroller.";
CM_ SG_ 1418 HVCU_OD_SdcOut "Measurement of Shutdown Circuit Output";
CM_ SG_ 1418 HVCU_OD_SdcIn "Measurement of Shutdown Circuit Input";
CM_ SG_ 1418 HVCU_OD_runtime "Runtime of chip in milliseconds.";
CM_ SG_ 1418 HVCU_OD_InputVoltage "Board supply voltage.";
CM_ SG_ 1418 HVCU_OD_BoardTemp "Temperature of board";
CM_ SG_ 1418 HVCU_OD_MemFree "Free memory in bytes.";
CM_ SG_ 1418 HVCU_OD_CpuUsage "Current CPU usage in %.";
CM_ SG_ 1418 HVCU_OD_OdEntrySendInterval "Interval for sending all readable OD entries. Sending is disabled if less than 5 ms.";
CM_ SG_ 1418 HVCU_OD_SendOdOnBootup "Whether to send all OD entries on bootup.";
CM_ SG_ 1418 HVCU_OD_HeartbeatInterval "Heartbeat Interval in milliseconds.";
CM_ SG_ 1418 HVCU_OD_DbcVersion "CANzero DBC version.";
CM_ SG_ 1418 HVCU_OD_StackVersion "CANzero stack version.";
CM_ SG_ 1418 HVCU_OD_ProtocolVersion "CANzero Protocol Version.";
CM_ SG_ 1418 HVCU_OD_NodeStatus "State of the node.";
CM_ SG_ 1418 HVCU_OD_NodeID "CANzero Node-ID.";
CM_ SG_ 1418 HVCU_SDO_RespCode "Response code of SDO access.";
CM_ SG_ 1418 HVCU_SDO_ID "Specifies SDO-ID of HVCU";
CM_ BO_ 1482 "DO NOT CHANGE ANYTHING HERE!
SDO Request Upload to node HVCU with Node-ID 0xA";
CM_ SG_ 1482 HVCU_OD_CAN2_DelayedTxMessages "Number of delayed TX messages on CAN2 because no messagebox was free.";
CM_ SG_ 1482 HVCU_OD_CAN2_ErrorStatus "Internal error status (e.g. Error active, Error passive, Bus Off)";
CM_ SG_ 1482 HVCU_OD_CAN2_DiscardedTxMessages "Number of discarded TX messages on CAN2 because all messageboxes were full";
CM_ SG_ 1482 HVCU_OD_CAN2_Status "Status of CAN2.";
CM_ SG_ 1482 HVCU_OD_CAN2_Baudrate "Baudrate of CAN.";
CM_ SG_ 1482 HVCU_OD_CAN2_autoErrorReset "Automatic reset of errors.";
CM_ SG_ 1482 HVCU_OD_CAN2_lastErrorCode "Last error code.";
CM_ SG_ 1482 HVCU_OD_CAN2_RxErrCnt "Receive error count of CAN1.";
CM_ SG_ 1482 HVCU_OD_CAN2_TxErrCnt "Transmit error count of CAN1.";
CM_ SG_ 1482 HVCU_OD_CAN1_DelayedTxMessages "Number of delayed TX messages on CAN1 because no messagebox was free.";
CM_ SG_ 1482 HVCU_OD_CAN1_ErrorStatus "Internal error status (e.g. Error active, Error passive, Bus Off)";
CM_ SG_ 1482 HVCU_OD_CAN1_DiscardedTxMessages "Number of discarded TX messages on CAN1 because all messageboxes were full";
CM_ SG_ 1482 HVCU_OD_CAN1_Status "Status of CAN1.";
CM_ SG_ 1482 HVCU_OD_CAN1_Baudrate "Baudrate of CAN.";
CM_ SG_ 1482 HVCU_OD_CAN1_autoErrorReset "Automatic reset of errors.";
CM_ SG_ 1482 HVCU_OD_CAN1_lastErrorCode "Last error code.";
CM_ SG_ 1482 HVCU_OD_CAN1_RxErrCnt "Receive error count of CAN1.";
CM_ SG_ 1482 HVCU_OD_CAN1_TxErrCnt "Transmit error count of CAN1.";
CM_ SG_ 1482 HVCU_OD_BuildTime "Software build time in the format HHMMSS.";
CM_ SG_ 1482 HVCU_OD_BuildDate "Software build date in the format YYYYMMDD.";
CM_ SG_ 1482 HVCU_OD_ChipUID2 "Seccond part of unique ID of microcontroller.";
CM_ SG_ 1482 HVCU_OD_ChipUID1 "First part of unique ID of microcontroller.";
CM_ SG_ 1482 HVCU_OD_SdcOut "Measurement of Shutdown Circuit Output";
CM_ SG_ 1482 HVCU_OD_SdcIn "Measurement of Shutdown Circuit Input";
CM_ SG_ 1482 HVCU_OD_runtime "Runtime of chip in milliseconds.";
CM_ SG_ 1482 HVCU_OD_InputVoltage "Board supply voltage.";
CM_ SG_ 1482 HVCU_OD_BoardTemp "Temperature of board";
CM_ SG_ 1482 HVCU_OD_MemFree "Free memory in bytes.";
CM_ SG_ 1482 HVCU_OD_CpuUsage "Current CPU usage in %.";
CM_ SG_ 1482 HVCU_OD_OdEntrySendInterval "Interval for sending all readable OD entries. Sending is disabled if less than 5 ms.";
CM_ SG_ 1482 HVCU_OD_SendOdOnBootup "Whether to send all OD entries on bootup.";
CM_ SG_ 1482 HVCU_OD_HeartbeatInterval "Heartbeat Interval in milliseconds.";
CM_ SG_ 1482 HVCU_OD_DbcVersion "CANzero DBC version.";
CM_ SG_ 1482 HVCU_OD_StackVersion "CANzero stack version.";
CM_ SG_ 1482 HVCU_OD_ProtocolVersion "CANzero Protocol Version.";
CM_ SG_ 1482 HVCU_OD_NodeStatus "State of the node.";
CM_ SG_ 1482 HVCU_OD_NodeID "CANzero Node-ID.";
CM_ SG_ 1482 HVCU_SDO_ID "Specifies SDO-ID of HVCU";
CM_ BO_ 1546 "DO NOT CHANGE ANYTHING HERE!
SDO Request Download from node HVCU with Node-ID 0xA";
CM_ SG_ 1546 HVCU_SDO_ID "Specifies SDO-ID of HVCU";
CM_ BO_ 1802 "Heartbeat of node HVCU with Node-ID 0xA";
CM_ SG_ 1802 HVCU_NodeState "Heartbeat status of node HVCU";
CM_ BO_ 1866 "Bootloader transmit from node HVCU with Node-ID 0xA";
CM_ BO_ 1930 "Bootloader receive by node HVCU with Node-ID 0xA";
CM_ BO_ 153 "Emergency message of node HVTU with Node-ID 0x19";
CM_ SG_ 153 HVTU_E0_OtherError "Other error.";
CM_ SG_ 153 HVTU_W0_OtherWarning "Other warning.";
CM_ BO_ 1299 "Control signals to control the SciMo PE with the mz control model implemented on the SciMo hardware (Vf and If control).

";
BA_DEF_ SG_  "GenSigSendType" ENUM  "Cyclic","OnWrite","OnWriteWithRepetition","OnChange","OnChangeWithRepetition","IfActive","IfActiveWithRepetition","NoSigSendType";
BA_DEF_ BO_  "GenMsgSendType" ENUM  "Cyclic","not_used","not_used","not_used","not_used","Cyclic","not_used","IfActive","NoMsgSendType";
BA_DEF_ BO_  "GenMsgCycleTime" INT 2 50000;
BA_DEF_ BO_  "GenMsgDelayTime" INT 1 1000;
BA_DEF_ BO_  "GenMsgNrOfRepetitions" INT 1 999999;
BA_DEF_ SG_  "GenSigStartValue" FLOAT 0 100000000000;
BA_DEF_ SG_  "CANzero_SDO_Group" STRING ;
BA_DEF_ SG_  "CANzero_SDO_AccessIfOperational" ENUM  "No","Yes";
BA_DEF_ SG_  "CANzero_SDO_AccessType" ENUM  "Read Write","Read Only","Write Only";
BA_DEF_ SG_  "CANzero_SDO_Default" FLOAT 0 0;
BA_DEF_ SG_  "SystemSignalLongSymbol" STRING ;
BA_DEF_DEF_  "GenSigSendType" "Cyclic";
BA_DEF_DEF_  "GenMsgSendType" "NoMsgSendType";
BA_DEF_DEF_  "GenMsgCycleTime" 100;
BA_DEF_DEF_  "GenMsgDelayTime" 1;
BA_DEF_DEF_  "GenMsgNrOfRepetitions" 1;
BA_DEF_DEF_  "GenSigStartValue" 0;
BA_DEF_DEF_  "CANzero_SDO_Group" "";
BA_DEF_DEF_  "CANzero_SDO_AccessIfOperational" "No";
BA_DEF_DEF_  "CANzero_SDO_AccessType" "Read Write";
BA_DEF_DEF_  "CANzero_SDO_Default" 0;
BA_DEF_DEF_  "SystemSignalLongSymbol" "";
BA_ "CANzero_SDO_AccessIfOperational" SG_ 1425 BrakeF_OD_BrakeStatus 1;
BA_ "CANzero_SDO_AccessType" SG_ 1425 BrakeF_OD_CoolingPressure 1;
BA_ "CANzero_SDO_AccessIfOperational" SG_ 1425 BrakeF_OD_CoolingPressure 1;
BA_ "GenSigStartValue" SG_ 1425 BrakeF_OD_CoolingPressure 9810.0;
BA_ "CANzero_SDO_Default" SG_ 1425 BrakeF_OD_CoolingPressure -1.9;
BA_ "CANzero_SDO_AccessIfOperational" SG_ 1425 BrakeF_OD_valveUpperTolerance 1;
BA_ "GenSigStartValue" SG_ 1425 BrakeF_OD_valveUpperTolerance 2000.0;
BA_ "CANzero_SDO_Default" SG_ 1425 BrakeF_OD_valveUpperTolerance 10;
BA_ "CANzero_SDO_AccessIfOperational" SG_ 1425 BrakeF_OD_commWatchdog 1;
BA_ "GenSigStartValue" SG_ 1425 BrakeF_OD_commWatchdog 60.0;
BA_ "CANzero_SDO_Default" SG_ 1425 BrakeF_OD_commWatchdog 60;
BA_ "CANzero_SDO_AccessIfOperational" SG_ 1425 BrakeF_OD_counterLimit 1;
BA_ "GenSigStartValue" SG_ 1425 BrakeF_OD_counterLimit 5.0;
BA_ "CANzero_SDO_Default" SG_ 1425 BrakeF_OD_counterLimit 5;
BA_ "CANzero_SDO_AccessIfOperational" SG_ 1425 BrakeF_OD_delay 1;
BA_ "GenSigStartValue" SG_ 1425 BrakeF_OD_delay 10.0;
BA_ "CANzero_SDO_Default" SG_ 1425 BrakeF_OD_delay 5;
BA_ "CANzero_SDO_AccessIfOperational" SG_ 1425 BrakeF_OD_tankUpperControlLimit 1;
BA_ "GenSigStartValue" SG_ 1425 BrakeF_OD_tankUpperControlLimit 3800.0;
BA_ "CANzero_SDO_Default" SG_ 1425 BrakeF_OD_tankUpperControlLimit 19;
BA_ "CANzero_SDO_AccessIfOperational" SG_ 1425 BrakeF_OD_tankLowerControlLimit 1;
BA_ "GenSigStartValue" SG_ 1425 BrakeF_OD_tankLowerControlLimit 1400.0;
BA_ "CANzero_SDO_Default" SG_ 1425 BrakeF_OD_tankLowerControlLimit 7;
BA_ "CANzero_SDO_Group" SG_ 1425 BrakeF_OD_CAN2_DelayedTxMessages "CAN";
BA_ "CANzero_SDO_AccessType" SG_ 1425 BrakeF_OD_CAN2_DelayedTxMessages 1;
BA_ "CANzero_SDO_AccessIfOperational" SG_ 1425 BrakeF_OD_CAN2_DelayedTxMessages 1;
BA_ "CANzero_SDO_Group" SG_ 1425 BrakeF_OD_CAN2_ErrorStatus "CAN";
BA_ "CANzero_SDO_AccessType" SG_ 1425 BrakeF_OD_CAN2_ErrorStatus 1;
BA_ "CANzero_SDO_AccessIfOperational" SG_ 1425 BrakeF_OD_CAN2_ErrorStatus 1;
BA_ "CANzero_SDO_Group" SG_ 1425 BrakeF_OD_CAN2_DiscardedTxMessag "CAN";
BA_ "CANzero_SDO_AccessType" SG_ 1425 BrakeF_OD_CAN2_DiscardedTxMessag 1;
BA_ "CANzero_SDO_AccessIfOperational" SG_ 1425 BrakeF_OD_CAN2_DiscardedTxMessag 1;
BA_ "SystemSignalLongSymbol" SG_ 1425 BrakeF_OD_CAN2_DiscardedTxMessag "BrakeF_OD_CAN2_DiscardedTxMessages";
BA_ "CANzero_SDO_Group" SG_ 1425 BrakeF_OD_CAN2_Status "CAN";
BA_ "CANzero_SDO_AccessType" SG_ 1425 BrakeF_OD_CAN2_Status 1;
BA_ "CANzero_SDO_AccessIfOperational" SG_ 1425 BrakeF_OD_CAN2_Status 1;
BA_ "CANzero_SDO_Group" SG_ 1425 BrakeF_OD_CAN2_Baudrate "CAN";
BA_ "CANzero_SDO_AccessIfOperational" SG_ 1425 BrakeF_OD_CAN2_Baudrate 1;
BA_ "GenSigStartValue" SG_ 1425 BrakeF_OD_CAN2_Baudrate 1000.0;
BA_ "CANzero_SDO_Default" SG_ 1425 BrakeF_OD_CAN2_Baudrate 1000;
BA_ "CANzero_SDO_Group" SG_ 1425 BrakeF_OD_CAN2_autoErrorReset "CAN";
BA_ "CANzero_SDO_AccessIfOperational" SG_ 1425 BrakeF_OD_CAN2_autoErrorReset 1;
BA_ "GenSigStartValue" SG_ 1425 BrakeF_OD_CAN2_autoErrorReset 1.0;
BA_ "CANzero_SDO_Default" SG_ 1425 BrakeF_OD_CAN2_autoErrorReset 1;
BA_ "CANzero_SDO_Group" SG_ 1425 BrakeF_OD_CAN2_lastErrorCode "CAN";
BA_ "CANzero_SDO_AccessType" SG_ 1425 BrakeF_OD_CAN2_lastErrorCode 1;
BA_ "CANzero_SDO_AccessIfOperational" SG_ 1425 BrakeF_OD_CAN2_lastErrorCode 1;
BA_ "CANzero_SDO_Group" SG_ 1425 BrakeF_OD_CAN2_RxErrCnt "CAN";
BA_ "CANzero_SDO_AccessType" SG_ 1425 BrakeF_OD_CAN2_RxErrCnt 1;
BA_ "CANzero_SDO_AccessIfOperational" SG_ 1425 BrakeF_OD_CAN2_RxErrCnt 1;
BA_ "CANzero_SDO_Group" SG_ 1425 BrakeF_OD_CAN2_TxErrCnt "CAN";
BA_ "CANzero_SDO_AccessType" SG_ 1425 BrakeF_OD_CAN2_TxErrCnt 1;
BA_ "CANzero_SDO_AccessIfOperational" SG_ 1425 BrakeF_OD_CAN2_TxErrCnt 1;
BA_ "CANzero_SDO_Group" SG_ 1425 BrakeF_OD_CAN1_DelayedTxMessages "CAN";
BA_ "CANzero_SDO_AccessType" SG_ 1425 BrakeF_OD_CAN1_DelayedTxMessages 1;
BA_ "CANzero_SDO_AccessIfOperational" SG_ 1425 BrakeF_OD_CAN1_DelayedTxMessages 1;
BA_ "CANzero_SDO_Group" SG_ 1425 BrakeF_OD_CAN1_ErrorStatus "CAN";
BA_ "CANzero_SDO_AccessType" SG_ 1425 BrakeF_OD_CAN1_ErrorStatus 1;
BA_ "CANzero_SDO_AccessIfOperational" SG_ 1425 BrakeF_OD_CAN1_ErrorStatus 1;
BA_ "CANzero_SDO_Group" SG_ 1425 BrakeF_OD_CAN1_DiscardedTxMessag "CAN";
BA_ "CANzero_SDO_AccessType" SG_ 1425 BrakeF_OD_CAN1_DiscardedTxMessag 1;
BA_ "CANzero_SDO_AccessIfOperational" SG_ 1425 BrakeF_OD_CAN1_DiscardedTxMessag 1;
BA_ "SystemSignalLongSymbol" SG_ 1425 BrakeF_OD_CAN1_DiscardedTxMessag "BrakeF_OD_CAN1_DiscardedTxMessages";
BA_ "CANzero_SDO_Group" SG_ 1425 BrakeF_OD_CAN1_Status "CAN";
BA_ "CANzero_SDO_AccessType" SG_ 1425 BrakeF_OD_CAN1_Status 1;
BA_ "CANzero_SDO_AccessIfOperational" SG_ 1425 BrakeF_OD_CAN1_Status 1;
BA_ "CANzero_SDO_Group" SG_ 1425 BrakeF_OD_CAN1_Baudrate "CAN";
BA_ "CANzero_SDO_AccessIfOperational" SG_ 1425 BrakeF_OD_CAN1_Baudrate 1;
BA_ "GenSigStartValue" SG_ 1425 BrakeF_OD_CAN1_Baudrate 1000.0;
BA_ "CANzero_SDO_Default" SG_ 1425 BrakeF_OD_CAN1_Baudrate 1000;
BA_ "CANzero_SDO_Group" SG_ 1425 BrakeF_OD_CAN1_autoErrorReset "CAN";
BA_ "CANzero_SDO_AccessIfOperational" SG_ 1425 BrakeF_OD_CAN1_autoErrorReset 1;
BA_ "GenSigStartValue" SG_ 1425 BrakeF_OD_CAN1_autoErrorReset 1.0;
BA_ "CANzero_SDO_Default" SG_ 1425 BrakeF_OD_CAN1_autoErrorReset 1;
BA_ "CANzero_SDO_Group" SG_ 1425 BrakeF_OD_CAN1_lastErrorCode "CAN";
BA_ "CANzero_SDO_AccessType" SG_ 1425 BrakeF_OD_CAN1_lastErrorCode 1;
BA_ "CANzero_SDO_AccessIfOperational" SG_ 1425 BrakeF_OD_CAN1_lastErrorCode 1;
BA_ "CANzero_SDO_Group" SG_ 1425 BrakeF_OD_CAN1_RxErrCnt "CAN";
BA_ "CANzero_SDO_AccessType" SG_ 1425 BrakeF_OD_CAN1_RxErrCnt 1;
BA_ "CANzero_SDO_AccessIfOperational" SG_ 1425 BrakeF_OD_CAN1_RxErrCnt 1;
BA_ "CANzero_SDO_Group" SG_ 1425 BrakeF_OD_CAN1_TxErrCnt "CAN";
BA_ "CANzero_SDO_AccessType" SG_ 1425 BrakeF_OD_CAN1_TxErrCnt 1;
BA_ "CANzero_SDO_AccessIfOperational" SG_ 1425 BrakeF_OD_CAN1_TxErrCnt 1;
BA_ "CANzero_SDO_AccessType" SG_ 1425 BrakeF_OD_BuildTime 1;
BA_ "CANzero_SDO_AccessIfOperational" SG_ 1425 BrakeF_OD_BuildTime 1;
BA_ "CANzero_SDO_AccessType" SG_ 1425 BrakeF_OD_BuildDate 1;
BA_ "CANzero_SDO_AccessIfOperational" SG_ 1425 BrakeF_OD_BuildDate 1;
BA_ "CANzero_SDO_AccessType" SG_ 1425 BrakeF_OD_ChipUID2 1;
BA_ "CANzero_SDO_AccessIfOperational" SG_ 1425 BrakeF_OD_ChipUID2 1;
BA_ "CANzero_SDO_AccessType" SG_ 1425 BrakeF_OD_ChipUID1 1;
BA_ "CANzero_SDO_AccessIfOperational" SG_ 1425 BrakeF_OD_ChipUID1 1;
BA_ "CANzero_SDO_AccessType" SG_ 1425 BrakeF_OD_SdcOut 1;
BA_ "CANzero_SDO_AccessIfOperational" SG_ 1425 BrakeF_OD_SdcOut 1;
BA_ "CANzero_SDO_AccessType" SG_ 1425 BrakeF_OD_SdcIn 1;
BA_ "CANzero_SDO_AccessIfOperational" SG_ 1425 BrakeF_OD_SdcIn 1;
BA_ "CANzero_SDO_AccessType" SG_ 1425 BrakeF_OD_runtime 1;
BA_ "CANzero_SDO_AccessIfOperational" SG_ 1425 BrakeF_OD_runtime 1;
BA_ "CANzero_SDO_AccessType" SG_ 1425 BrakeF_OD_InputVoltage 1;
BA_ "CANzero_SDO_AccessIfOperational" SG_ 1425 BrakeF_OD_InputVoltage 1;
BA_ "CANzero_SDO_AccessType" SG_ 1425 BrakeF_OD_BoardTemp 1;
BA_ "CANzero_SDO_AccessIfOperational" SG_ 1425 BrakeF_OD_BoardTemp 1;
BA_ "GenSigStartValue" SG_ 1425 BrakeF_OD_BoardTemp 3000.0;
BA_ "CANzero_SDO_AccessType" SG_ 1425 BrakeF_OD_MemFree 1;
BA_ "CANzero_SDO_AccessIfOperational" SG_ 1425 BrakeF_OD_MemFree 1;
BA_ "CANzero_SDO_AccessType" SG_ 1425 BrakeF_OD_CpuUsage 1;
BA_ "CANzero_SDO_AccessIfOperational" SG_ 1425 BrakeF_OD_CpuUsage 1;
BA_ "CANzero_SDO_AccessIfOperational" SG_ 1425 BrakeF_OD_OdEntrySendInterval 1;
BA_ "GenSigStartValue" SG_ 1425 BrakeF_OD_OdEntrySendInterval 50.0;
BA_ "CANzero_SDO_Default" SG_ 1425 BrakeF_OD_OdEntrySendInterval 50;
BA_ "CANzero_SDO_AccessIfOperational" SG_ 1425 BrakeF_OD_SendOdOnBootup 1;
BA_ "CANzero_SDO_AccessIfOperational" SG_ 1425 BrakeF_OD_HeartbeatInterval 1;
BA_ "GenSigStartValue" SG_ 1425 BrakeF_OD_HeartbeatInterval 100.0;
BA_ "CANzero_SDO_Default" SG_ 1425 BrakeF_OD_HeartbeatInterval 100;
BA_ "CANzero_SDO_AccessType" SG_ 1425 BrakeF_OD_DbcVersion 1;
BA_ "CANzero_SDO_AccessIfOperational" SG_ 1425 BrakeF_OD_DbcVersion 1;
BA_ "CANzero_SDO_AccessType" SG_ 1425 BrakeF_OD_StackVersion 1;
BA_ "CANzero_SDO_AccessIfOperational" SG_ 1425 BrakeF_OD_StackVersion 1;
BA_ "CANzero_SDO_AccessType" SG_ 1425 BrakeF_OD_ProtocolVersion 1;
BA_ "CANzero_SDO_AccessIfOperational" SG_ 1425 BrakeF_OD_ProtocolVersion 1;
BA_ "GenSigStartValue" SG_ 1425 BrakeF_OD_ProtocolVersion 1.0;
BA_ "CANzero_SDO_Default" SG_ 1425 BrakeF_OD_ProtocolVersion 1;
BA_ "CANzero_SDO_AccessType" SG_ 1425 BrakeF_OD_NodeStatus 1;
BA_ "CANzero_SDO_AccessIfOperational" SG_ 1425 BrakeF_OD_NodeStatus 1;
BA_ "CANzero_SDO_AccessType" SG_ 1425 BrakeF_OD_NodeID 1;
BA_ "CANzero_SDO_AccessIfOperational" SG_ 1425 BrakeF_OD_NodeID 1;
BA_ "CANzero_SDO_AccessIfOperational" SG_ 1489 BrakeF_OD_BrakeStatus 1;
BA_ "CANzero_SDO_AccessType" SG_ 1489 BrakeF_OD_CoolingPressure 1;
BA_ "CANzero_SDO_AccessIfOperational" SG_ 1489 BrakeF_OD_CoolingPressure 1;
BA_ "GenSigStartValue" SG_ 1489 BrakeF_OD_CoolingPressure 9810.0;
BA_ "CANzero_SDO_Default" SG_ 1489 BrakeF_OD_CoolingPressure -1.9;
BA_ "CANzero_SDO_AccessIfOperational" SG_ 1489 BrakeF_OD_valveUpperTolerance 1;
BA_ "GenSigStartValue" SG_ 1489 BrakeF_OD_valveUpperTolerance 2000.0;
BA_ "CANzero_SDO_Default" SG_ 1489 BrakeF_OD_valveUpperTolerance 10;
BA_ "CANzero_SDO_AccessIfOperational" SG_ 1489 BrakeF_OD_commWatchdog 1;
BA_ "GenSigStartValue" SG_ 1489 BrakeF_OD_commWatchdog 60.0;
BA_ "CANzero_SDO_Default" SG_ 1489 BrakeF_OD_commWatchdog 60;
BA_ "CANzero_SDO_AccessIfOperational" SG_ 1489 BrakeF_OD_counterLimit 1;
BA_ "GenSigStartValue" SG_ 1489 BrakeF_OD_counterLimit 5.0;
BA_ "CANzero_SDO_Default" SG_ 1489 BrakeF_OD_counterLimit 5;
BA_ "CANzero_SDO_AccessIfOperational" SG_ 1489 BrakeF_OD_delay 1;
BA_ "GenSigStartValue" SG_ 1489 BrakeF_OD_delay 10.0;
BA_ "CANzero_SDO_Default" SG_ 1489 BrakeF_OD_delay 5;
BA_ "CANzero_SDO_AccessIfOperational" SG_ 1489 BrakeF_OD_tankUpperControlLimit 1;
BA_ "GenSigStartValue" SG_ 1489 BrakeF_OD_tankUpperControlLimit 3800.0;
BA_ "CANzero_SDO_Default" SG_ 1489 BrakeF_OD_tankUpperControlLimit 19;
BA_ "CANzero_SDO_AccessIfOperational" SG_ 1489 BrakeF_OD_tankLowerControlLimit 1;
BA_ "GenSigStartValue" SG_ 1489 BrakeF_OD_tankLowerControlLimit 1400.0;
BA_ "CANzero_SDO_Default" SG_ 1489 BrakeF_OD_tankLowerControlLimit 7;
BA_ "CANzero_SDO_Group" SG_ 1489 BrakeF_OD_CAN2_DelayedTxMessages "CAN";
BA_ "CANzero_SDO_AccessType" SG_ 1489 BrakeF_OD_CAN2_DelayedTxMessages 1;
BA_ "CANzero_SDO_AccessIfOperational" SG_ 1489 BrakeF_OD_CAN2_DelayedTxMessages 1;
BA_ "CANzero_SDO_Group" SG_ 1489 BrakeF_OD_CAN2_ErrorStatus "CAN";
BA_ "CANzero_SDO_AccessType" SG_ 1489 BrakeF_OD_CAN2_ErrorStatus 1;
BA_ "CANzero_SDO_AccessIfOperational" SG_ 1489 BrakeF_OD_CAN2_ErrorStatus 1;
BA_ "CANzero_SDO_Group" SG_ 1489 BrakeF_OD_CAN2_DiscardedTxM_0000 "CAN";
BA_ "CANzero_SDO_AccessType" SG_ 1489 BrakeF_OD_CAN2_DiscardedTxM_0000 1;
BA_ "CANzero_SDO_AccessIfOperational" SG_ 1489 BrakeF_OD_CAN2_DiscardedTxM_0000 1;
BA_ "SystemSignalLongSymbol" SG_ 1489 BrakeF_OD_CAN2_DiscardedTxM_0000 "BrakeF_OD_CAN2_DiscardedTxMessages";
BA_ "CANzero_SDO_Group" SG_ 1489 BrakeF_OD_CAN2_Status "CAN";
BA_ "CANzero_SDO_AccessType" SG_ 1489 BrakeF_OD_CAN2_Status 1;
BA_ "CANzero_SDO_AccessIfOperational" SG_ 1489 BrakeF_OD_CAN2_Status 1;
BA_ "CANzero_SDO_Group" SG_ 1489 BrakeF_OD_CAN2_Baudrate "CAN";
BA_ "CANzero_SDO_AccessIfOperational" SG_ 1489 BrakeF_OD_CAN2_Baudrate 1;
BA_ "GenSigStartValue" SG_ 1489 BrakeF_OD_CAN2_Baudrate 1000.0;
BA_ "CANzero_SDO_Default" SG_ 1489 BrakeF_OD_CAN2_Baudrate 1000;
BA_ "CANzero_SDO_Group" SG_ 1489 BrakeF_OD_CAN2_autoErrorReset "CAN";
BA_ "CANzero_SDO_AccessIfOperational" SG_ 1489 BrakeF_OD_CAN2_autoErrorReset 1;
BA_ "GenSigStartValue" SG_ 1489 BrakeF_OD_CAN2_autoErrorReset 1.0;
BA_ "CANzero_SDO_Default" SG_ 1489 BrakeF_OD_CAN2_autoErrorReset 1;
BA_ "CANzero_SDO_Group" SG_ 1489 BrakeF_OD_CAN2_lastErrorCode "CAN";
BA_ "CANzero_SDO_AccessType" SG_ 1489 BrakeF_OD_CAN2_lastErrorCode 1;
BA_ "CANzero_SDO_AccessIfOperational" SG_ 1489 BrakeF_OD_CAN2_lastErrorCode 1;
BA_ "CANzero_SDO_Group" SG_ 1489 BrakeF_OD_CAN2_RxErrCnt "CAN";
BA_ "CANzero_SDO_AccessType" SG_ 1489 BrakeF_OD_CAN2_RxErrCnt 1;
BA_ "CANzero_SDO_AccessIfOperational" SG_ 1489 BrakeF_OD_CAN2_RxErrCnt 1;
BA_ "CANzero_SDO_Group" SG_ 1489 BrakeF_OD_CAN2_TxErrCnt "CAN";
BA_ "CANzero_SDO_AccessType" SG_ 1489 BrakeF_OD_CAN2_TxErrCnt 1;
BA_ "CANzero_SDO_AccessIfOperational" SG_ 1489 BrakeF_OD_CAN2_TxErrCnt 1;
BA_ "CANzero_SDO_Group" SG_ 1489 BrakeF_OD_CAN1_DelayedTxMessages "CAN";
BA_ "CANzero_SDO_AccessType" SG_ 1489 BrakeF_OD_CAN1_DelayedTxMessages 1;
BA_ "CANzero_SDO_AccessIfOperational" SG_ 1489 BrakeF_OD_CAN1_DelayedTxMessages 1;
BA_ "CANzero_SDO_Group" SG_ 1489 BrakeF_OD_CAN1_ErrorStatus "CAN";
BA_ "CANzero_SDO_AccessType" SG_ 1489 BrakeF_OD_CAN1_ErrorStatus 1;
BA_ "CANzero_SDO_AccessIfOperational" SG_ 1489 BrakeF_OD_CAN1_ErrorStatus 1;
BA_ "CANzero_SDO_Group" SG_ 1489 BrakeF_OD_CAN1_DiscardedTxM_0000 "CAN";
BA_ "CANzero_SDO_AccessType" SG_ 1489 BrakeF_OD_CAN1_DiscardedTxM_0000 1;
BA_ "CANzero_SDO_AccessIfOperational" SG_ 1489 BrakeF_OD_CAN1_DiscardedTxM_0000 1;
BA_ "SystemSignalLongSymbol" SG_ 1489 BrakeF_OD_CAN1_DiscardedTxM_0000 "BrakeF_OD_CAN1_DiscardedTxMessages";
BA_ "CANzero_SDO_Group" SG_ 1489 BrakeF_OD_CAN1_Status "CAN";
BA_ "CANzero_SDO_AccessType" SG_ 1489 BrakeF_OD_CAN1_Status 1;
BA_ "CANzero_SDO_AccessIfOperational" SG_ 1489 BrakeF_OD_CAN1_Status 1;
BA_ "CANzero_SDO_Group" SG_ 1489 BrakeF_OD_CAN1_Baudrate "CAN";
BA_ "CANzero_SDO_AccessIfOperational" SG_ 1489 BrakeF_OD_CAN1_Baudrate 1;
BA_ "GenSigStartValue" SG_ 1489 BrakeF_OD_CAN1_Baudrate 1000.0;
BA_ "CANzero_SDO_Default" SG_ 1489 BrakeF_OD_CAN1_Baudrate 1000;
BA_ "CANzero_SDO_Group" SG_ 1489 BrakeF_OD_CAN1_autoErrorReset "CAN";
BA_ "CANzero_SDO_AccessIfOperational" SG_ 1489 BrakeF_OD_CAN1_autoErrorReset 1;
BA_ "GenSigStartValue" SG_ 1489 BrakeF_OD_CAN1_autoErrorReset 1.0;
BA_ "CANzero_SDO_Default" SG_ 1489 BrakeF_OD_CAN1_autoErrorReset 1;
BA_ "CANzero_SDO_Group" SG_ 1489 BrakeF_OD_CAN1_lastErrorCode "CAN";
BA_ "CANzero_SDO_AccessType" SG_ 1489 BrakeF_OD_CAN1_lastErrorCode 1;
BA_ "CANzero_SDO_AccessIfOperational" SG_ 1489 BrakeF_OD_CAN1_lastErrorCode 1;
BA_ "CANzero_SDO_Group" SG_ 1489 BrakeF_OD_CAN1_RxErrCnt "CAN";
BA_ "CANzero_SDO_AccessType" SG_ 1489 BrakeF_OD_CAN1_RxErrCnt 1;
BA_ "CANzero_SDO_AccessIfOperational" SG_ 1489 BrakeF_OD_CAN1_RxErrCnt 1;
BA_ "CANzero_SDO_Group" SG_ 1489 BrakeF_OD_CAN1_TxErrCnt "CAN";
BA_ "CANzero_SDO_AccessType" SG_ 1489 BrakeF_OD_CAN1_TxErrCnt 1;
BA_ "CANzero_SDO_AccessIfOperational" SG_ 1489 BrakeF_OD_CAN1_TxErrCnt 1;
BA_ "CANzero_SDO_AccessType" SG_ 1489 BrakeF_OD_BuildTime 1;
BA_ "CANzero_SDO_AccessIfOperational" SG_ 1489 BrakeF_OD_BuildTime 1;
BA_ "CANzero_SDO_AccessType" SG_ 1489 BrakeF_OD_BuildDate 1;
BA_ "CANzero_SDO_AccessIfOperational" SG_ 1489 BrakeF_OD_BuildDate 1;
BA_ "CANzero_SDO_AccessType" SG_ 1489 BrakeF_OD_ChipUID2 1;
BA_ "CANzero_SDO_AccessIfOperational" SG_ 1489 BrakeF_OD_ChipUID2 1;
BA_ "CANzero_SDO_AccessType" SG_ 1489 BrakeF_OD_ChipUID1 1;
BA_ "CANzero_SDO_AccessIfOperational" SG_ 1489 BrakeF_OD_ChipUID1 1;
BA_ "CANzero_SDO_AccessType" SG_ 1489 BrakeF_OD_SdcOut 1;
BA_ "CANzero_SDO_AccessIfOperational" SG_ 1489 BrakeF_OD_SdcOut 1;
BA_ "CANzero_SDO_AccessType" SG_ 1489 BrakeF_OD_SdcIn 1;
BA_ "CANzero_SDO_AccessIfOperational" SG_ 1489 BrakeF_OD_SdcIn 1;
BA_ "CANzero_SDO_AccessType" SG_ 1489 BrakeF_OD_runtime 1;
BA_ "CANzero_SDO_AccessIfOperational" SG_ 1489 BrakeF_OD_runtime 1;
BA_ "CANzero_SDO_AccessType" SG_ 1489 BrakeF_OD_InputVoltage 1;
BA_ "CANzero_SDO_AccessIfOperational" SG_ 1489 BrakeF_OD_InputVoltage 1;
BA_ "CANzero_SDO_AccessType" SG_ 1489 BrakeF_OD_BoardTemp 1;
BA_ "CANzero_SDO_AccessIfOperational" SG_ 1489 BrakeF_OD_BoardTemp 1;
BA_ "GenSigStartValue" SG_ 1489 BrakeF_OD_BoardTemp 3000.0;
BA_ "CANzero_SDO_AccessType" SG_ 1489 BrakeF_OD_MemFree 1;
BA_ "CANzero_SDO_AccessIfOperational" SG_ 1489 BrakeF_OD_MemFree 1;
BA_ "CANzero_SDO_AccessType" SG_ 1489 BrakeF_OD_CpuUsage 1;
BA_ "CANzero_SDO_AccessIfOperational" SG_ 1489 BrakeF_OD_CpuUsage 1;
BA_ "CANzero_SDO_AccessIfOperational" SG_ 1489 BrakeF_OD_OdEntrySendInterval 1;
BA_ "GenSigStartValue" SG_ 1489 BrakeF_OD_OdEntrySendInterval 50.0;
BA_ "CANzero_SDO_Default" SG_ 1489 BrakeF_OD_OdEntrySendInterval 50;
BA_ "CANzero_SDO_AccessIfOperational" SG_ 1489 BrakeF_OD_SendOdOnBootup 1;
BA_ "CANzero_SDO_AccessIfOperational" SG_ 1489 BrakeF_OD_HeartbeatInterval 1;
BA_ "GenSigStartValue" SG_ 1489 BrakeF_OD_HeartbeatInterval 100.0;
BA_ "CANzero_SDO_Default" SG_ 1489 BrakeF_OD_HeartbeatInterval 100;
BA_ "CANzero_SDO_AccessType" SG_ 1489 BrakeF_OD_DbcVersion 1;
BA_ "CANzero_SDO_AccessIfOperational" SG_ 1489 BrakeF_OD_DbcVersion 1;
BA_ "CANzero_SDO_AccessType" SG_ 1489 BrakeF_OD_StackVersion 1;
BA_ "CANzero_SDO_AccessIfOperational" SG_ 1489 BrakeF_OD_StackVersion 1;
BA_ "CANzero_SDO_AccessType" SG_ 1489 BrakeF_OD_ProtocolVersion 1;
BA_ "CANzero_SDO_AccessIfOperational" SG_ 1489 BrakeF_OD_ProtocolVersion 1;
BA_ "GenSigStartValue" SG_ 1489 BrakeF_OD_ProtocolVersion 1.0;
BA_ "CANzero_SDO_Default" SG_ 1489 BrakeF_OD_ProtocolVersion 1;
BA_ "CANzero_SDO_AccessType" SG_ 1489 BrakeF_OD_NodeStatus 1;
BA_ "CANzero_SDO_AccessIfOperational" SG_ 1489 BrakeF_OD_NodeStatus 1;
BA_ "CANzero_SDO_AccessType" SG_ 1489 BrakeF_OD_NodeID 1;
BA_ "CANzero_SDO_AccessIfOperational" SG_ 1489 BrakeF_OD_NodeID 1;
BA_ "SystemSignalLongSymbol" SG_ 146 BrakeR_E5_retractUnsuccesful_ope "BrakeR_E5_retractUnsuccesful_openSDC";
BA_ "SystemSignalLongSymbol" SG_ 146 BrakeR_E4_retractUnsuccesful_not "BrakeR_E4_retractUnsuccesful_notEnabled";
BA_ "SystemSignalLongSymbol" SG_ 146 BrakeR_E3_retractUnsuccesful_err "BrakeR_E3_retractUnsuccesful_errorFlag";
BA_ "SystemSignalLongSymbol" SG_ 146 BrakeR_W1_highPressureRetracting "BrakeR_W1_highPressureRetractingChamber";
BA_ "SystemSignalLongSymbol" SG_ 146 BrakeR_W0_highPressureActingCham "BrakeR_W0_highPressureActingChamber";
BA_ "GenSigStartValue" SG_ 1106 BrakeR_TX_Pressure_Tank 400;
BA_ "GenSigStartValue" SG_ 1106 BrakeR_TX_Pressure_Retract 400;
BA_ "GenSigStartValue" SG_ 1106 BrakeR_TX_Pressure_Act 400;
BA_ "CANzero_SDO_AccessIfOperational" SG_ 1426 BrakeR_OD_valveUpperTolerance 1;
BA_ "GenSigStartValue" SG_ 1426 BrakeR_OD_valveUpperTolerance 2000.0;
BA_ "CANzero_SDO_Default" SG_ 1426 BrakeR_OD_valveUpperTolerance 10;
BA_ "CANzero_SDO_AccessIfOperational" SG_ 1426 BrakeR_OD_commWatchdog 1;
BA_ "GenSigStartValue" SG_ 1426 BrakeR_OD_commWatchdog 60.0;
BA_ "CANzero_SDO_Default" SG_ 1426 BrakeR_OD_commWatchdog 60;
BA_ "CANzero_SDO_AccessIfOperational" SG_ 1426 BrakeR_OD_counterLimit 1;
BA_ "GenSigStartValue" SG_ 1426 BrakeR_OD_counterLimit 5.0;
BA_ "CANzero_SDO_Default" SG_ 1426 BrakeR_OD_counterLimit 5;
BA_ "CANzero_SDO_AccessIfOperational" SG_ 1426 BrakeR_OD_delay 1;
BA_ "GenSigStartValue" SG_ 1426 BrakeR_OD_delay 10.0;
BA_ "CANzero_SDO_Default" SG_ 1426 BrakeR_OD_delay 5;
BA_ "CANzero_SDO_AccessIfOperational" SG_ 1426 BrakeR_OD_tankUpperControlLimit 1;
BA_ "GenSigStartValue" SG_ 1426 BrakeR_OD_tankUpperControlLimit 3800.0;
BA_ "CANzero_SDO_Default" SG_ 1426 BrakeR_OD_tankUpperControlLimit 19;
BA_ "CANzero_SDO_AccessIfOperational" SG_ 1426 BrakeR_OD_tankLowerControlLimit 1;
BA_ "GenSigStartValue" SG_ 1426 BrakeR_OD_tankLowerControlLimit 1400.0;
BA_ "CANzero_SDO_Default" SG_ 1426 BrakeR_OD_tankLowerControlLimit 7;
BA_ "CANzero_SDO_Group" SG_ 1426 BrakeR_OD_CAN2_DelayedTxMessages "CAN";
BA_ "CANzero_SDO_AccessType" SG_ 1426 BrakeR_OD_CAN2_DelayedTxMessages 1;
BA_ "CANzero_SDO_AccessIfOperational" SG_ 1426 BrakeR_OD_CAN2_DelayedTxMessages 1;
BA_ "CANzero_SDO_Group" SG_ 1426 BrakeR_OD_CAN2_ErrorStatus "CAN";
BA_ "CANzero_SDO_AccessType" SG_ 1426 BrakeR_OD_CAN2_ErrorStatus 1;
BA_ "CANzero_SDO_AccessIfOperational" SG_ 1426 BrakeR_OD_CAN2_ErrorStatus 1;
BA_ "CANzero_SDO_Group" SG_ 1426 BrakeR_OD_CAN2_DiscardedTxMessag "CAN";
BA_ "CANzero_SDO_AccessType" SG_ 1426 BrakeR_OD_CAN2_DiscardedTxMessag 1;
BA_ "CANzero_SDO_AccessIfOperational" SG_ 1426 BrakeR_OD_CAN2_DiscardedTxMessag 1;
BA_ "SystemSignalLongSymbol" SG_ 1426 BrakeR_OD_CAN2_DiscardedTxMessag "BrakeR_OD_CAN2_DiscardedTxMessages";
BA_ "CANzero_SDO_Group" SG_ 1426 BrakeR_OD_CAN2_Status "CAN";
BA_ "CANzero_SDO_AccessType" SG_ 1426 BrakeR_OD_CAN2_Status 1;
BA_ "CANzero_SDO_AccessIfOperational" SG_ 1426 BrakeR_OD_CAN2_Status 1;
BA_ "CANzero_SDO_Group" SG_ 1426 BrakeR_OD_CAN2_Baudrate "CAN";
BA_ "CANzero_SDO_AccessIfOperational" SG_ 1426 BrakeR_OD_CAN2_Baudrate 1;
BA_ "GenSigStartValue" SG_ 1426 BrakeR_OD_CAN2_Baudrate 1000.0;
BA_ "CANzero_SDO_Default" SG_ 1426 BrakeR_OD_CAN2_Baudrate 1000;
BA_ "CANzero_SDO_Group" SG_ 1426 BrakeR_OD_CAN2_autoErrorReset "CAN";
BA_ "CANzero_SDO_AccessIfOperational" SG_ 1426 BrakeR_OD_CAN2_autoErrorReset 1;
BA_ "GenSigStartValue" SG_ 1426 BrakeR_OD_CAN2_autoErrorReset 1.0;
BA_ "CANzero_SDO_Default" SG_ 1426 BrakeR_OD_CAN2_autoErrorReset 1;
BA_ "CANzero_SDO_Group" SG_ 1426 BrakeR_OD_CAN2_lastErrorCode "CAN";
BA_ "CANzero_SDO_AccessType" SG_ 1426 BrakeR_OD_CAN2_lastErrorCode 1;
BA_ "CANzero_SDO_AccessIfOperational" SG_ 1426 BrakeR_OD_CAN2_lastErrorCode 1;
BA_ "CANzero_SDO_Group" SG_ 1426 BrakeR_OD_CAN2_RxErrCnt "CAN";
BA_ "CANzero_SDO_AccessType" SG_ 1426 BrakeR_OD_CAN2_RxErrCnt 1;
BA_ "CANzero_SDO_AccessIfOperational" SG_ 1426 BrakeR_OD_CAN2_RxErrCnt 1;
BA_ "CANzero_SDO_Group" SG_ 1426 BrakeR_OD_CAN2_TxErrCnt "CAN";
BA_ "CANzero_SDO_AccessType" SG_ 1426 BrakeR_OD_CAN2_TxErrCnt 1;
BA_ "CANzero_SDO_AccessIfOperational" SG_ 1426 BrakeR_OD_CAN2_TxErrCnt 1;
BA_ "CANzero_SDO_Group" SG_ 1426 BrakeR_OD_CAN1_DelayedTxMessages "CAN";
BA_ "CANzero_SDO_AccessType" SG_ 1426 BrakeR_OD_CAN1_DelayedTxMessages 1;
BA_ "CANzero_SDO_AccessIfOperational" SG_ 1426 BrakeR_OD_CAN1_DelayedTxMessages 1;
BA_ "CANzero_SDO_Group" SG_ 1426 BrakeR_OD_CAN1_ErrorStatus "CAN";
BA_ "CANzero_SDO_AccessType" SG_ 1426 BrakeR_OD_CAN1_ErrorStatus 1;
BA_ "CANzero_SDO_AccessIfOperational" SG_ 1426 BrakeR_OD_CAN1_ErrorStatus 1;
BA_ "CANzero_SDO_Group" SG_ 1426 BrakeR_OD_CAN1_DiscardedTxMessag "CAN";
BA_ "CANzero_SDO_AccessType" SG_ 1426 BrakeR_OD_CAN1_DiscardedTxMessag 1;
BA_ "CANzero_SDO_AccessIfOperational" SG_ 1426 BrakeR_OD_CAN1_DiscardedTxMessag 1;
BA_ "SystemSignalLongSymbol" SG_ 1426 BrakeR_OD_CAN1_DiscardedTxMessag "BrakeR_OD_CAN1_DiscardedTxMessages";
BA_ "CANzero_SDO_Group" SG_ 1426 BrakeR_OD_CAN1_Status "CAN";
BA_ "CANzero_SDO_AccessType" SG_ 1426 BrakeR_OD_CAN1_Status 1;
BA_ "CANzero_SDO_AccessIfOperational" SG_ 1426 BrakeR_OD_CAN1_Status 1;
BA_ "CANzero_SDO_Group" SG_ 1426 BrakeR_OD_CAN1_Baudrate "CAN";
BA_ "CANzero_SDO_AccessIfOperational" SG_ 1426 BrakeR_OD_CAN1_Baudrate 1;
BA_ "GenSigStartValue" SG_ 1426 BrakeR_OD_CAN1_Baudrate 1000.0;
BA_ "CANzero_SDO_Default" SG_ 1426 BrakeR_OD_CAN1_Baudrate 1000;
BA_ "CANzero_SDO_Group" SG_ 1426 BrakeR_OD_CAN1_autoErrorReset "CAN";
BA_ "CANzero_SDO_AccessIfOperational" SG_ 1426 BrakeR_OD_CAN1_autoErrorReset 1;
BA_ "GenSigStartValue" SG_ 1426 BrakeR_OD_CAN1_autoErrorReset 1.0;
BA_ "CANzero_SDO_Default" SG_ 1426 BrakeR_OD_CAN1_autoErrorReset 1;
BA_ "CANzero_SDO_Group" SG_ 1426 BrakeR_OD_CAN1_lastErrorCode "CAN";
BA_ "CANzero_SDO_AccessType" SG_ 1426 BrakeR_OD_CAN1_lastErrorCode 1;
BA_ "CANzero_SDO_AccessIfOperational" SG_ 1426 BrakeR_OD_CAN1_lastErrorCode 1;
BA_ "CANzero_SDO_Group" SG_ 1426 BrakeR_OD_CAN1_RxErrCnt "CAN";
BA_ "CANzero_SDO_AccessType" SG_ 1426 BrakeR_OD_CAN1_RxErrCnt 1;
BA_ "CANzero_SDO_AccessIfOperational" SG_ 1426 BrakeR_OD_CAN1_RxErrCnt 1;
BA_ "CANzero_SDO_Group" SG_ 1426 BrakeR_OD_CAN1_TxErrCnt "CAN";
BA_ "CANzero_SDO_AccessType" SG_ 1426 BrakeR_OD_CAN1_TxErrCnt 1;
BA_ "CANzero_SDO_AccessIfOperational" SG_ 1426 BrakeR_OD_CAN1_TxErrCnt 1;
BA_ "CANzero_SDO_AccessType" SG_ 1426 BrakeR_OD_BuildTime 1;
BA_ "CANzero_SDO_AccessIfOperational" SG_ 1426 BrakeR_OD_BuildTime 1;
BA_ "CANzero_SDO_AccessType" SG_ 1426 BrakeR_OD_BuildDate 1;
BA_ "CANzero_SDO_AccessIfOperational" SG_ 1426 BrakeR_OD_BuildDate 1;
BA_ "CANzero_SDO_AccessType" SG_ 1426 BrakeR_OD_ChipUID2 1;
BA_ "CANzero_SDO_AccessIfOperational" SG_ 1426 BrakeR_OD_ChipUID2 1;
BA_ "CANzero_SDO_AccessType" SG_ 1426 BrakeR_OD_ChipUID1 1;
BA_ "CANzero_SDO_AccessIfOperational" SG_ 1426 BrakeR_OD_ChipUID1 1;
BA_ "CANzero_SDO_AccessType" SG_ 1426 BrakeR_OD_SdcOut 1;
BA_ "CANzero_SDO_AccessIfOperational" SG_ 1426 BrakeR_OD_SdcOut 1;
BA_ "CANzero_SDO_AccessType" SG_ 1426 BrakeR_OD_SdcIn 1;
BA_ "CANzero_SDO_AccessIfOperational" SG_ 1426 BrakeR_OD_SdcIn 1;
BA_ "CANzero_SDO_AccessType" SG_ 1426 BrakeR_OD_runtime 1;
BA_ "CANzero_SDO_AccessIfOperational" SG_ 1426 BrakeR_OD_runtime 1;
BA_ "CANzero_SDO_AccessType" SG_ 1426 BrakeR_OD_InputVoltage 1;
BA_ "CANzero_SDO_AccessIfOperational" SG_ 1426 BrakeR_OD_InputVoltage 1;
BA_ "CANzero_SDO_AccessType" SG_ 1426 BrakeR_OD_BoardTemp 1;
BA_ "CANzero_SDO_AccessIfOperational" SG_ 1426 BrakeR_OD_BoardTemp 1;
BA_ "GenSigStartValue" SG_ 1426 BrakeR_OD_BoardTemp 3000.0;
BA_ "CANzero_SDO_AccessType" SG_ 1426 BrakeR_OD_MemFree 1;
BA_ "CANzero_SDO_AccessIfOperational" SG_ 1426 BrakeR_OD_MemFree 1;
BA_ "CANzero_SDO_AccessType" SG_ 1426 BrakeR_OD_CpuUsage 1;
BA_ "CANzero_SDO_AccessIfOperational" SG_ 1426 BrakeR_OD_CpuUsage 1;
BA_ "CANzero_SDO_AccessIfOperational" SG_ 1426 BrakeR_OD_OdEntrySendInterval 1;
BA_ "GenSigStartValue" SG_ 1426 BrakeR_OD_OdEntrySendInterval 50.0;
BA_ "CANzero_SDO_Default" SG_ 1426 BrakeR_OD_OdEntrySendInterval 50;
BA_ "CANzero_SDO_AccessIfOperational" SG_ 1426 BrakeR_OD_SendOdOnBootup 1;
BA_ "CANzero_SDO_AccessIfOperational" SG_ 1426 BrakeR_OD_HeartbeatInterval 1;
BA_ "GenSigStartValue" SG_ 1426 BrakeR_OD_HeartbeatInterval 100.0;
BA_ "CANzero_SDO_Default" SG_ 1426 BrakeR_OD_HeartbeatInterval 100;
BA_ "CANzero_SDO_AccessType" SG_ 1426 BrakeR_OD_DbcVersion 1;
BA_ "CANzero_SDO_AccessIfOperational" SG_ 1426 BrakeR_OD_DbcVersion 1;
BA_ "CANzero_SDO_AccessType" SG_ 1426 BrakeR_OD_StackVersion 1;
BA_ "CANzero_SDO_AccessIfOperational" SG_ 1426 BrakeR_OD_StackVersion 1;
BA_ "CANzero_SDO_AccessType" SG_ 1426 BrakeR_OD_ProtocolVersion 1;
BA_ "CANzero_SDO_AccessIfOperational" SG_ 1426 BrakeR_OD_ProtocolVersion 1;
BA_ "GenSigStartValue" SG_ 1426 BrakeR_OD_ProtocolVersion 1.0;
BA_ "CANzero_SDO_Default" SG_ 1426 BrakeR_OD_ProtocolVersion 1;
BA_ "CANzero_SDO_AccessType" SG_ 1426 BrakeR_OD_NodeStatus 1;
BA_ "CANzero_SDO_AccessIfOperational" SG_ 1426 BrakeR_OD_NodeStatus 1;
BA_ "CANzero_SDO_AccessType" SG_ 1426 BrakeR_OD_NodeID 1;
BA_ "CANzero_SDO_AccessIfOperational" SG_ 1426 BrakeR_OD_NodeID 1;
BA_ "CANzero_SDO_AccessIfOperational" SG_ 1490 BrakeR_OD_valveUpperTolerance 1;
BA_ "GenSigStartValue" SG_ 1490 BrakeR_OD_valveUpperTolerance 2000.0;
BA_ "CANzero_SDO_Default" SG_ 1490 BrakeR_OD_valveUpperTolerance 10;
BA_ "CANzero_SDO_AccessIfOperational" SG_ 1490 BrakeR_OD_commWatchdog 1;
BA_ "GenSigStartValue" SG_ 1490 BrakeR_OD_commWatchdog 60.0;
BA_ "CANzero_SDO_Default" SG_ 1490 BrakeR_OD_commWatchdog 60;
BA_ "CANzero_SDO_AccessIfOperational" SG_ 1490 BrakeR_OD_counterLimit 1;
BA_ "GenSigStartValue" SG_ 1490 BrakeR_OD_counterLimit 5.0;
BA_ "CANzero_SDO_Default" SG_ 1490 BrakeR_OD_counterLimit 5;
BA_ "CANzero_SDO_AccessIfOperational" SG_ 1490 BrakeR_OD_delay 1;
BA_ "GenSigStartValue" SG_ 1490 BrakeR_OD_delay 10.0;
BA_ "CANzero_SDO_Default" SG_ 1490 BrakeR_OD_delay 5;
BA_ "CANzero_SDO_AccessIfOperational" SG_ 1490 BrakeR_OD_tankUpperControlLimit 1;
BA_ "GenSigStartValue" SG_ 1490 BrakeR_OD_tankUpperControlLimit 3800.0;
BA_ "CANzero_SDO_Default" SG_ 1490 BrakeR_OD_tankUpperControlLimit 19;
BA_ "CANzero_SDO_AccessIfOperational" SG_ 1490 BrakeR_OD_tankLowerControlLimit 1;
BA_ "GenSigStartValue" SG_ 1490 BrakeR_OD_tankLowerControlLimit 1400.0;
BA_ "CANzero_SDO_Default" SG_ 1490 BrakeR_OD_tankLowerControlLimit 7;
BA_ "CANzero_SDO_Group" SG_ 1490 BrakeR_OD_CAN2_DelayedTxMessages "CAN";
BA_ "CANzero_SDO_AccessType" SG_ 1490 BrakeR_OD_CAN2_DelayedTxMessages 1;
BA_ "CANzero_SDO_AccessIfOperational" SG_ 1490 BrakeR_OD_CAN2_DelayedTxMessages 1;
BA_ "CANzero_SDO_Group" SG_ 1490 BrakeR_OD_CAN2_ErrorStatus "CAN";
BA_ "CANzero_SDO_AccessType" SG_ 1490 BrakeR_OD_CAN2_ErrorStatus 1;
BA_ "CANzero_SDO_AccessIfOperational" SG_ 1490 BrakeR_OD_CAN2_ErrorStatus 1;
BA_ "CANzero_SDO_Group" SG_ 1490 BrakeR_OD_CAN2_DiscardedTxM_0000 "CAN";
BA_ "CANzero_SDO_AccessType" SG_ 1490 BrakeR_OD_CAN2_DiscardedTxM_0000 1;
BA_ "CANzero_SDO_AccessIfOperational" SG_ 1490 BrakeR_OD_CAN2_DiscardedTxM_0000 1;
BA_ "SystemSignalLongSymbol" SG_ 1490 BrakeR_OD_CAN2_DiscardedTxM_0000 "BrakeR_OD_CAN2_DiscardedTxMessages";
BA_ "CANzero_SDO_Group" SG_ 1490 BrakeR_OD_CAN2_Status "CAN";
BA_ "CANzero_SDO_AccessType" SG_ 1490 BrakeR_OD_CAN2_Status 1;
BA_ "CANzero_SDO_AccessIfOperational" SG_ 1490 BrakeR_OD_CAN2_Status 1;
BA_ "CANzero_SDO_Group" SG_ 1490 BrakeR_OD_CAN2_Baudrate "CAN";
BA_ "CANzero_SDO_AccessIfOperational" SG_ 1490 BrakeR_OD_CAN2_Baudrate 1;
BA_ "GenSigStartValue" SG_ 1490 BrakeR_OD_CAN2_Baudrate 1000.0;
BA_ "CANzero_SDO_Default" SG_ 1490 BrakeR_OD_CAN2_Baudrate 1000;
BA_ "CANzero_SDO_Group" SG_ 1490 BrakeR_OD_CAN2_autoErrorReset "CAN";
BA_ "CANzero_SDO_AccessIfOperational" SG_ 1490 BrakeR_OD_CAN2_autoErrorReset 1;
BA_ "GenSigStartValue" SG_ 1490 BrakeR_OD_CAN2_autoErrorReset 1.0;
BA_ "CANzero_SDO_Default" SG_ 1490 BrakeR_OD_CAN2_autoErrorReset 1;
BA_ "CANzero_SDO_Group" SG_ 1490 BrakeR_OD_CAN2_lastErrorCode "CAN";
BA_ "CANzero_SDO_AccessType" SG_ 1490 BrakeR_OD_CAN2_lastErrorCode 1;
BA_ "CANzero_SDO_AccessIfOperational" SG_ 1490 BrakeR_OD_CAN2_lastErrorCode 1;
BA_ "CANzero_SDO_Group" SG_ 1490 BrakeR_OD_CAN2_RxErrCnt "CAN";
BA_ "CANzero_SDO_AccessType" SG_ 1490 BrakeR_OD_CAN2_RxErrCnt 1;
BA_ "CANzero_SDO_AccessIfOperational" SG_ 1490 BrakeR_OD_CAN2_RxErrCnt 1;
BA_ "CANzero_SDO_Group" SG_ 1490 BrakeR_OD_CAN2_TxErrCnt "CAN";
BA_ "CANzero_SDO_AccessType" SG_ 1490 BrakeR_OD_CAN2_TxErrCnt 1;
BA_ "CANzero_SDO_AccessIfOperational" SG_ 1490 BrakeR_OD_CAN2_TxErrCnt 1;
BA_ "CANzero_SDO_Group" SG_ 1490 BrakeR_OD_CAN1_DelayedTxMessages "CAN";
BA_ "CANzero_SDO_AccessType" SG_ 1490 BrakeR_OD_CAN1_DelayedTxMessages 1;
BA_ "CANzero_SDO_AccessIfOperational" SG_ 1490 BrakeR_OD_CAN1_DelayedTxMessages 1;
BA_ "CANzero_SDO_Group" SG_ 1490 BrakeR_OD_CAN1_ErrorStatus "CAN";
BA_ "CANzero_SDO_AccessType" SG_ 1490 BrakeR_OD_CAN1_ErrorStatus 1;
BA_ "CANzero_SDO_AccessIfOperational" SG_ 1490 BrakeR_OD_CAN1_ErrorStatus 1;
BA_ "CANzero_SDO_Group" SG_ 1490 BrakeR_OD_CAN1_DiscardedTxM_0000 "CAN";
BA_ "CANzero_SDO_AccessType" SG_ 1490 BrakeR_OD_CAN1_DiscardedTxM_0000 1;
BA_ "CANzero_SDO_AccessIfOperational" SG_ 1490 BrakeR_OD_CAN1_DiscardedTxM_0000 1;
BA_ "SystemSignalLongSymbol" SG_ 1490 BrakeR_OD_CAN1_DiscardedTxM_0000 "BrakeR_OD_CAN1_DiscardedTxMessages";
BA_ "CANzero_SDO_Group" SG_ 1490 BrakeR_OD_CAN1_Status "CAN";
BA_ "CANzero_SDO_AccessType" SG_ 1490 BrakeR_OD_CAN1_Status 1;
BA_ "CANzero_SDO_AccessIfOperational" SG_ 1490 BrakeR_OD_CAN1_Status 1;
BA_ "CANzero_SDO_Group" SG_ 1490 BrakeR_OD_CAN1_Baudrate "CAN";
BA_ "CANzero_SDO_AccessIfOperational" SG_ 1490 BrakeR_OD_CAN1_Baudrate 1;
BA_ "GenSigStartValue" SG_ 1490 BrakeR_OD_CAN1_Baudrate 1000.0;
BA_ "CANzero_SDO_Default" SG_ 1490 BrakeR_OD_CAN1_Baudrate 1000;
BA_ "CANzero_SDO_Group" SG_ 1490 BrakeR_OD_CAN1_autoErrorReset "CAN";
BA_ "CANzero_SDO_AccessIfOperational" SG_ 1490 BrakeR_OD_CAN1_autoErrorReset 1;
BA_ "GenSigStartValue" SG_ 1490 BrakeR_OD_CAN1_autoErrorReset 1.0;
BA_ "CANzero_SDO_Default" SG_ 1490 BrakeR_OD_CAN1_autoErrorReset 1;
BA_ "CANzero_SDO_Group" SG_ 1490 BrakeR_OD_CAN1_lastErrorCode "CAN";
BA_ "CANzero_SDO_AccessType" SG_ 1490 BrakeR_OD_CAN1_lastErrorCode 1;
BA_ "CANzero_SDO_AccessIfOperational" SG_ 1490 BrakeR_OD_CAN1_lastErrorCode 1;
BA_ "CANzero_SDO_Group" SG_ 1490 BrakeR_OD_CAN1_RxErrCnt "CAN";
BA_ "CANzero_SDO_AccessType" SG_ 1490 BrakeR_OD_CAN1_RxErrCnt 1;
BA_ "CANzero_SDO_AccessIfOperational" SG_ 1490 BrakeR_OD_CAN1_RxErrCnt 1;
BA_ "CANzero_SDO_Group" SG_ 1490 BrakeR_OD_CAN1_TxErrCnt "CAN";
BA_ "CANzero_SDO_AccessType" SG_ 1490 BrakeR_OD_CAN1_TxErrCnt 1;
BA_ "CANzero_SDO_AccessIfOperational" SG_ 1490 BrakeR_OD_CAN1_TxErrCnt 1;
BA_ "CANzero_SDO_AccessType" SG_ 1490 BrakeR_OD_BuildTime 1;
BA_ "CANzero_SDO_AccessIfOperational" SG_ 1490 BrakeR_OD_BuildTime 1;
BA_ "CANzero_SDO_AccessType" SG_ 1490 BrakeR_OD_BuildDate 1;
BA_ "CANzero_SDO_AccessIfOperational" SG_ 1490 BrakeR_OD_BuildDate 1;
BA_ "CANzero_SDO_AccessType" SG_ 1490 BrakeR_OD_ChipUID2 1;
BA_ "CANzero_SDO_AccessIfOperational" SG_ 1490 BrakeR_OD_ChipUID2 1;
BA_ "CANzero_SDO_AccessType" SG_ 1490 BrakeR_OD_ChipUID1 1;
BA_ "CANzero_SDO_AccessIfOperational" SG_ 1490 BrakeR_OD_ChipUID1 1;
BA_ "CANzero_SDO_AccessType" SG_ 1490 BrakeR_OD_SdcOut 1;
BA_ "CANzero_SDO_AccessIfOperational" SG_ 1490 BrakeR_OD_SdcOut 1;
BA_ "CANzero_SDO_AccessType" SG_ 1490 BrakeR_OD_SdcIn 1;
BA_ "CANzero_SDO_AccessIfOperational" SG_ 1490 BrakeR_OD_SdcIn 1;
BA_ "CANzero_SDO_AccessType" SG_ 1490 BrakeR_OD_runtime 1;
BA_ "CANzero_SDO_AccessIfOperational" SG_ 1490 BrakeR_OD_runtime 1;
BA_ "CANzero_SDO_AccessType" SG_ 1490 BrakeR_OD_InputVoltage 1;
BA_ "CANzero_SDO_AccessIfOperational" SG_ 1490 BrakeR_OD_InputVoltage 1;
BA_ "CANzero_SDO_AccessType" SG_ 1490 BrakeR_OD_BoardTemp 1;
BA_ "CANzero_SDO_AccessIfOperational" SG_ 1490 BrakeR_OD_BoardTemp 1;
BA_ "GenSigStartValue" SG_ 1490 BrakeR_OD_BoardTemp 3000.0;
BA_ "CANzero_SDO_AccessType" SG_ 1490 BrakeR_OD_MemFree 1;
BA_ "CANzero_SDO_AccessIfOperational" SG_ 1490 BrakeR_OD_MemFree 1;
BA_ "CANzero_SDO_AccessType" SG_ 1490 BrakeR_OD_CpuUsage 1;
BA_ "CANzero_SDO_AccessIfOperational" SG_ 1490 BrakeR_OD_CpuUsage 1;
BA_ "CANzero_SDO_AccessIfOperational" SG_ 1490 BrakeR_OD_OdEntrySendInterval 1;
BA_ "GenSigStartValue" SG_ 1490 BrakeR_OD_OdEntrySendInterval 50.0;
BA_ "CANzero_SDO_Default" SG_ 1490 BrakeR_OD_OdEntrySendInterval 50;
BA_ "CANzero_SDO_AccessIfOperational" SG_ 1490 BrakeR_OD_SendOdOnBootup 1;
BA_ "CANzero_SDO_AccessIfOperational" SG_ 1490 BrakeR_OD_HeartbeatInterval 1;
BA_ "GenSigStartValue" SG_ 1490 BrakeR_OD_HeartbeatInterval 100.0;
BA_ "CANzero_SDO_Default" SG_ 1490 BrakeR_OD_HeartbeatInterval 100;
BA_ "CANzero_SDO_AccessType" SG_ 1490 BrakeR_OD_DbcVersion 1;
BA_ "CANzero_SDO_AccessIfOperational" SG_ 1490 BrakeR_OD_DbcVersion 1;
BA_ "CANzero_SDO_AccessType" SG_ 1490 BrakeR_OD_StackVersion 1;
BA_ "CANzero_SDO_AccessIfOperational" SG_ 1490 BrakeR_OD_StackVersion 1;
BA_ "CANzero_SDO_AccessType" SG_ 1490 BrakeR_OD_ProtocolVersion 1;
BA_ "CANzero_SDO_AccessIfOperational" SG_ 1490 BrakeR_OD_ProtocolVersion 1;
BA_ "GenSigStartValue" SG_ 1490 BrakeR_OD_ProtocolVersion 1.0;
BA_ "CANzero_SDO_Default" SG_ 1490 BrakeR_OD_ProtocolVersion 1;
BA_ "CANzero_SDO_AccessType" SG_ 1490 BrakeR_OD_NodeStatus 1;
BA_ "CANzero_SDO_AccessIfOperational" SG_ 1490 BrakeR_OD_NodeStatus 1;
BA_ "CANzero_SDO_AccessType" SG_ 1490 BrakeR_OD_NodeID 1;
BA_ "CANzero_SDO_AccessIfOperational" SG_ 1490 BrakeR_OD_NodeID 1;
BA_ "GenSigStartValue" SG_ 602 PDU_LPCh9_Dutycycle 200;
BA_ "GenSigStartValue" SG_ 602 PDU_LPCh8_Dutycycle 200;
BA_ "GenSigStartValue" SG_ 602 PDU_LPCh3_Dutycycle 200;
BA_ "GenSigStartValue" SG_ 602 PDU_LPCh2_Dutycycle 200;
BA_ "GenSigStartValue" SG_ 602 PDU_LPCh10_Dutycycle 200;
BA_ "GenSigStartValue" SG_ 602 PDU_LPCh1_Dutycycle 200;
BA_ "GenSigStartValue" SG_ 730 PDU_D4_Dutycycle 200;
BA_ "GenSigStartValue" SG_ 730 PDU_D3_Dutycycle 200;
BA_ "GenSigStartValue" SG_ 730 PDU_D2_Dutycycle 200;
BA_ "GenSigStartValue" SG_ 730 PDU_D1_Dutycycle 200;
BA_ "GenSigStartValue" SG_ 730 PDU_HPCh2_Dutycycle 200;
BA_ "GenSigStartValue" SG_ 730 PDU_HPCh1_Dutycycle 200;
BA_ "CANzero_SDO_AccessIfOperational" SG_ 1434 PDU_OD_CoolingPumpEnabled 1;
BA_ "GenSigStartValue" SG_ 1434 PDU_OD_CoolingPumpEnabled 1.0;
BA_ "CANzero_SDO_Default" SG_ 1434 PDU_OD_CoolingPumpEnabled 1;
BA_ "CANzero_SDO_AccessIfOperational" SG_ 1434 PDU_OD_LedCommands 1;
BA_ "GenSigStartValue" SG_ 1434 PDU_OD_LedCommands 1.0;
BA_ "CANzero_SDO_Default" SG_ 1434 PDU_OD_LedCommands 1;
BA_ "CANzero_SDO_AccessIfOperational" SG_ 1434 PDU_OD_projectXXEnabled 1;
BA_ "GenSigStartValue" SG_ 1434 PDU_OD_projectXXEnabled 1.0;
BA_ "CANzero_SDO_Default" SG_ 1434 PDU_OD_projectXXEnabled 1;
BA_ "CANzero_SDO_AccessIfOperational" SG_ 1434 PDU_OD_watchdogTimeout 1;
BA_ "GenSigStartValue" SG_ 1434 PDU_OD_watchdogTimeout 25.0;
BA_ "CANzero_SDO_Default" SG_ 1434 PDU_OD_watchdogTimeout 25;
BA_ "CANzero_SDO_AccessIfOperational" SG_ 1434 PDU_OD_statusSendInterval 1;
BA_ "GenSigStartValue" SG_ 1434 PDU_OD_statusSendInterval 20.0;
BA_ "CANzero_SDO_Default" SG_ 1434 PDU_OD_statusSendInterval 20;
BA_ "CANzero_SDO_AccessIfOperational" SG_ 1434 PDU_OD_currentReadInterval 1;
BA_ "GenSigStartValue" SG_ 1434 PDU_OD_currentReadInterval 100.0;
BA_ "CANzero_SDO_Default" SG_ 1434 PDU_OD_currentReadInterval 100;
BA_ "CANzero_SDO_AccessIfOperational" SG_ 1434 PDU_OD_batteryOvercurrent 1;
BA_ "GenSigStartValue" SG_ 1434 PDU_OD_batteryOvercurrent 1500.0;
BA_ "CANzero_SDO_Default" SG_ 1434 PDU_OD_batteryOvercurrent 15;
BA_ "CANzero_SDO_AccessIfOperational" SG_ 1434 PDU_OD_overTempCritical 1;
BA_ "GenSigStartValue" SG_ 1434 PDU_OD_overTempCritical 700.0;
BA_ "CANzero_SDO_Default" SG_ 1434 PDU_OD_overTempCritical 70;
BA_ "CANzero_SDO_AccessIfOperational" SG_ 1434 PDU_OD_overTempWarn 1;
BA_ "GenSigStartValue" SG_ 1434 PDU_OD_overTempWarn 400.0;
BA_ "CANzero_SDO_Default" SG_ 1434 PDU_OD_overTempWarn 40;
BA_ "CANzero_SDO_AccessIfOperational" SG_ 1434 PDU_OD_batterVoltageCritical 1;
BA_ "GenSigStartValue" SG_ 1434 PDU_OD_batterVoltageCritical 2100.0;
BA_ "CANzero_SDO_Default" SG_ 1434 PDU_OD_batterVoltageCritical 21.0;
BA_ "CANzero_SDO_AccessIfOperational" SG_ 1434 PDU_OD_batterVoltageLow 1;
BA_ "GenSigStartValue" SG_ 1434 PDU_OD_batterVoltageLow 2220.0;
BA_ "CANzero_SDO_Default" SG_ 1434 PDU_OD_batterVoltageLow 22.2;
BA_ "CANzero_SDO_Group" SG_ 1434 PDU_OD_CAN2_DelayedTxMessages "CAN";
BA_ "CANzero_SDO_AccessType" SG_ 1434 PDU_OD_CAN2_DelayedTxMessages 1;
BA_ "CANzero_SDO_AccessIfOperational" SG_ 1434 PDU_OD_CAN2_DelayedTxMessages 1;
BA_ "CANzero_SDO_Group" SG_ 1434 PDU_OD_CAN2_ErrorStatus "CAN";
BA_ "CANzero_SDO_AccessType" SG_ 1434 PDU_OD_CAN2_ErrorStatus 1;
BA_ "CANzero_SDO_AccessIfOperational" SG_ 1434 PDU_OD_CAN2_ErrorStatus 1;
BA_ "CANzero_SDO_Group" SG_ 1434 PDU_OD_CAN2_DiscardedTxMessages "CAN";
BA_ "CANzero_SDO_AccessType" SG_ 1434 PDU_OD_CAN2_DiscardedTxMessages 1;
BA_ "CANzero_SDO_AccessIfOperational" SG_ 1434 PDU_OD_CAN2_DiscardedTxMessages 1;
BA_ "CANzero_SDO_Group" SG_ 1434 PDU_OD_CAN2_Status "CAN";
BA_ "CANzero_SDO_AccessType" SG_ 1434 PDU_OD_CAN2_Status 1;
BA_ "CANzero_SDO_AccessIfOperational" SG_ 1434 PDU_OD_CAN2_Status 1;
BA_ "CANzero_SDO_Group" SG_ 1434 PDU_OD_CAN2_Baudrate "CAN";
BA_ "CANzero_SDO_AccessIfOperational" SG_ 1434 PDU_OD_CAN2_Baudrate 1;
BA_ "GenSigStartValue" SG_ 1434 PDU_OD_CAN2_Baudrate 1000.0;
BA_ "CANzero_SDO_Default" SG_ 1434 PDU_OD_CAN2_Baudrate 1000;
BA_ "CANzero_SDO_Group" SG_ 1434 PDU_OD_CAN2_autoErrorReset "CAN";
BA_ "CANzero_SDO_AccessIfOperational" SG_ 1434 PDU_OD_CAN2_autoErrorReset 1;
BA_ "GenSigStartValue" SG_ 1434 PDU_OD_CAN2_autoErrorReset 1.0;
BA_ "CANzero_SDO_Default" SG_ 1434 PDU_OD_CAN2_autoErrorReset 1;
BA_ "CANzero_SDO_Group" SG_ 1434 PDU_OD_CAN2_lastErrorCode "CAN";
BA_ "CANzero_SDO_AccessType" SG_ 1434 PDU_OD_CAN2_lastErrorCode 1;
BA_ "CANzero_SDO_AccessIfOperational" SG_ 1434 PDU_OD_CAN2_lastErrorCode 1;
BA_ "CANzero_SDO_Group" SG_ 1434 PDU_OD_CAN2_RxErrCnt "CAN";
BA_ "CANzero_SDO_AccessType" SG_ 1434 PDU_OD_CAN2_RxErrCnt 1;
BA_ "CANzero_SDO_AccessIfOperational" SG_ 1434 PDU_OD_CAN2_RxErrCnt 1;
BA_ "CANzero_SDO_Group" SG_ 1434 PDU_OD_CAN2_TxErrCnt "CAN";
BA_ "CANzero_SDO_AccessType" SG_ 1434 PDU_OD_CAN2_TxErrCnt 1;
BA_ "CANzero_SDO_AccessIfOperational" SG_ 1434 PDU_OD_CAN2_TxErrCnt 1;
BA_ "CANzero_SDO_Group" SG_ 1434 PDU_OD_CAN1_DelayedTxMessages "CAN";
BA_ "CANzero_SDO_AccessType" SG_ 1434 PDU_OD_CAN1_DelayedTxMessages 1;
BA_ "CANzero_SDO_AccessIfOperational" SG_ 1434 PDU_OD_CAN1_DelayedTxMessages 1;
BA_ "CANzero_SDO_Group" SG_ 1434 PDU_OD_CAN1_ErrorStatus "CAN";
BA_ "CANzero_SDO_AccessType" SG_ 1434 PDU_OD_CAN1_ErrorStatus 1;
BA_ "CANzero_SDO_AccessIfOperational" SG_ 1434 PDU_OD_CAN1_ErrorStatus 1;
BA_ "CANzero_SDO_Group" SG_ 1434 PDU_OD_CAN1_DiscardedTxMessages "CAN";
BA_ "CANzero_SDO_AccessType" SG_ 1434 PDU_OD_CAN1_DiscardedTxMessages 1;
BA_ "CANzero_SDO_AccessIfOperational" SG_ 1434 PDU_OD_CAN1_DiscardedTxMessages 1;
BA_ "CANzero_SDO_Group" SG_ 1434 PDU_OD_CAN1_Status "CAN";
BA_ "CANzero_SDO_AccessType" SG_ 1434 PDU_OD_CAN1_Status 1;
BA_ "CANzero_SDO_AccessIfOperational" SG_ 1434 PDU_OD_CAN1_Status 1;
BA_ "CANzero_SDO_Group" SG_ 1434 PDU_OD_CAN1_Baudrate "CAN";
BA_ "CANzero_SDO_AccessIfOperational" SG_ 1434 PDU_OD_CAN1_Baudrate 1;
BA_ "GenSigStartValue" SG_ 1434 PDU_OD_CAN1_Baudrate 1000.0;
BA_ "CANzero_SDO_Default" SG_ 1434 PDU_OD_CAN1_Baudrate 1000;
BA_ "CANzero_SDO_Group" SG_ 1434 PDU_OD_CAN1_autoErrorReset "CAN";
BA_ "CANzero_SDO_AccessIfOperational" SG_ 1434 PDU_OD_CAN1_autoErrorReset 1;
BA_ "GenSigStartValue" SG_ 1434 PDU_OD_CAN1_autoErrorReset 1.0;
BA_ "CANzero_SDO_Default" SG_ 1434 PDU_OD_CAN1_autoErrorReset 1;
BA_ "CANzero_SDO_Group" SG_ 1434 PDU_OD_CAN1_lastErrorCode "CAN";
BA_ "CANzero_SDO_AccessType" SG_ 1434 PDU_OD_CAN1_lastErrorCode 1;
BA_ "CANzero_SDO_AccessIfOperational" SG_ 1434 PDU_OD_CAN1_lastErrorCode 1;
BA_ "CANzero_SDO_Group" SG_ 1434 PDU_OD_CAN1_RxErrCnt "CAN";
BA_ "CANzero_SDO_AccessType" SG_ 1434 PDU_OD_CAN1_RxErrCnt 1;
BA_ "CANzero_SDO_AccessIfOperational" SG_ 1434 PDU_OD_CAN1_RxErrCnt 1;
BA_ "CANzero_SDO_Group" SG_ 1434 PDU_OD_CAN1_TxErrCnt "CAN";
BA_ "CANzero_SDO_AccessType" SG_ 1434 PDU_OD_CAN1_TxErrCnt 1;
BA_ "CANzero_SDO_AccessIfOperational" SG_ 1434 PDU_OD_CAN1_TxErrCnt 1;
BA_ "CANzero_SDO_AccessType" SG_ 1434 PDU_OD_BuildTime 1;
BA_ "CANzero_SDO_AccessIfOperational" SG_ 1434 PDU_OD_BuildTime 1;
BA_ "CANzero_SDO_AccessType" SG_ 1434 PDU_OD_BuildDate 1;
BA_ "CANzero_SDO_AccessIfOperational" SG_ 1434 PDU_OD_BuildDate 1;
BA_ "CANzero_SDO_AccessType" SG_ 1434 PDU_OD_ChipUID2 1;
BA_ "CANzero_SDO_AccessIfOperational" SG_ 1434 PDU_OD_ChipUID2 1;
BA_ "CANzero_SDO_AccessType" SG_ 1434 PDU_OD_ChipUID1 1;
BA_ "CANzero_SDO_AccessIfOperational" SG_ 1434 PDU_OD_ChipUID1 1;
BA_ "CANzero_SDO_AccessType" SG_ 1434 PDU_OD_SdcOut 1;
BA_ "CANzero_SDO_AccessIfOperational" SG_ 1434 PDU_OD_SdcOut 1;
BA_ "CANzero_SDO_AccessType" SG_ 1434 PDU_OD_SdcIn 1;
BA_ "CANzero_SDO_AccessIfOperational" SG_ 1434 PDU_OD_SdcIn 1;
BA_ "CANzero_SDO_AccessType" SG_ 1434 PDU_OD_runtime 1;
BA_ "CANzero_SDO_AccessIfOperational" SG_ 1434 PDU_OD_runtime 1;
BA_ "CANzero_SDO_AccessType" SG_ 1434 PDU_OD_InputVoltage 1;
BA_ "CANzero_SDO_AccessIfOperational" SG_ 1434 PDU_OD_InputVoltage 1;
BA_ "CANzero_SDO_AccessType" SG_ 1434 PDU_OD_BoardTemp 1;
BA_ "CANzero_SDO_AccessIfOperational" SG_ 1434 PDU_OD_BoardTemp 1;
BA_ "GenSigStartValue" SG_ 1434 PDU_OD_BoardTemp 3000.0;
BA_ "CANzero_SDO_AccessType" SG_ 1434 PDU_OD_MemFree 1;
BA_ "CANzero_SDO_AccessIfOperational" SG_ 1434 PDU_OD_MemFree 1;
BA_ "CANzero_SDO_AccessType" SG_ 1434 PDU_OD_CpuUsage 1;
BA_ "CANzero_SDO_AccessIfOperational" SG_ 1434 PDU_OD_CpuUsage 1;
BA_ "CANzero_SDO_AccessIfOperational" SG_ 1434 PDU_OD_OdEntrySendInterval 1;
BA_ "GenSigStartValue" SG_ 1434 PDU_OD_OdEntrySendInterval 50.0;
BA_ "CANzero_SDO_Default" SG_ 1434 PDU_OD_OdEntrySendInterval 50;
BA_ "CANzero_SDO_AccessIfOperational" SG_ 1434 PDU_OD_SendOdOnBootup 1;
BA_ "CANzero_SDO_AccessIfOperational" SG_ 1434 PDU_OD_HeartbeatInterval 1;
BA_ "GenSigStartValue" SG_ 1434 PDU_OD_HeartbeatInterval 250.0;
BA_ "CANzero_SDO_Default" SG_ 1434 PDU_OD_HeartbeatInterval 250;
BA_ "CANzero_SDO_AccessType" SG_ 1434 PDU_OD_DbcVersion 1;
BA_ "CANzero_SDO_AccessIfOperational" SG_ 1434 PDU_OD_DbcVersion 1;
BA_ "CANzero_SDO_AccessType" SG_ 1434 PDU_OD_StackVersion 1;
BA_ "CANzero_SDO_AccessIfOperational" SG_ 1434 PDU_OD_StackVersion 1;
BA_ "CANzero_SDO_AccessType" SG_ 1434 PDU_OD_ProtocolVersion 1;
BA_ "CANzero_SDO_AccessIfOperational" SG_ 1434 PDU_OD_ProtocolVersion 1;
BA_ "GenSigStartValue" SG_ 1434 PDU_OD_ProtocolVersion 1.0;
BA_ "CANzero_SDO_Default" SG_ 1434 PDU_OD_ProtocolVersion 1;
BA_ "CANzero_SDO_AccessType" SG_ 1434 PDU_OD_NodeStatus 1;
BA_ "CANzero_SDO_AccessIfOperational" SG_ 1434 PDU_OD_NodeStatus 1;
BA_ "CANzero_SDO_AccessType" SG_ 1434 PDU_OD_NodeID 1;
BA_ "CANzero_SDO_AccessIfOperational" SG_ 1434 PDU_OD_NodeID 1;
BA_ "CANzero_SDO_AccessIfOperational" SG_ 1498 PDU_OD_CoolingPumpEnabled 1;
BA_ "GenSigStartValue" SG_ 1498 PDU_OD_CoolingPumpEnabled 1.0;
BA_ "CANzero_SDO_Default" SG_ 1498 PDU_OD_CoolingPumpEnabled 1;
BA_ "CANzero_SDO_AccessIfOperational" SG_ 1498 PDU_OD_LedCommands 1;
BA_ "GenSigStartValue" SG_ 1498 PDU_OD_LedCommands 1.0;
BA_ "CANzero_SDO_Default" SG_ 1498 PDU_OD_LedCommands 1;
BA_ "CANzero_SDO_AccessIfOperational" SG_ 1498 PDU_OD_projectXXEnabled 1;
BA_ "GenSigStartValue" SG_ 1498 PDU_OD_projectXXEnabled 1.0;
BA_ "CANzero_SDO_Default" SG_ 1498 PDU_OD_projectXXEnabled 1;
BA_ "CANzero_SDO_AccessIfOperational" SG_ 1498 PDU_OD_watchdogTimeout 1;
BA_ "GenSigStartValue" SG_ 1498 PDU_OD_watchdogTimeout 25.0;
BA_ "CANzero_SDO_Default" SG_ 1498 PDU_OD_watchdogTimeout 25;
BA_ "CANzero_SDO_AccessIfOperational" SG_ 1498 PDU_OD_statusSendInterval 1;
BA_ "GenSigStartValue" SG_ 1498 PDU_OD_statusSendInterval 20.0;
BA_ "CANzero_SDO_Default" SG_ 1498 PDU_OD_statusSendInterval 20;
BA_ "CANzero_SDO_AccessIfOperational" SG_ 1498 PDU_OD_currentReadInterval 1;
BA_ "GenSigStartValue" SG_ 1498 PDU_OD_currentReadInterval 100.0;
BA_ "CANzero_SDO_Default" SG_ 1498 PDU_OD_currentReadInterval 100;
BA_ "CANzero_SDO_AccessIfOperational" SG_ 1498 PDU_OD_batteryOvercurrent 1;
BA_ "GenSigStartValue" SG_ 1498 PDU_OD_batteryOvercurrent 1500.0;
BA_ "CANzero_SDO_Default" SG_ 1498 PDU_OD_batteryOvercurrent 15;
BA_ "CANzero_SDO_AccessIfOperational" SG_ 1498 PDU_OD_overTempCritical 1;
BA_ "GenSigStartValue" SG_ 1498 PDU_OD_overTempCritical 700.0;
BA_ "CANzero_SDO_Default" SG_ 1498 PDU_OD_overTempCritical 70;
BA_ "CANzero_SDO_AccessIfOperational" SG_ 1498 PDU_OD_overTempWarn 1;
BA_ "GenSigStartValue" SG_ 1498 PDU_OD_overTempWarn 400.0;
BA_ "CANzero_SDO_Default" SG_ 1498 PDU_OD_overTempWarn 40;
BA_ "CANzero_SDO_AccessIfOperational" SG_ 1498 PDU_OD_batterVoltageCritical 1;
BA_ "GenSigStartValue" SG_ 1498 PDU_OD_batterVoltageCritical 2100.0;
BA_ "CANzero_SDO_Default" SG_ 1498 PDU_OD_batterVoltageCritical 21.0;
BA_ "CANzero_SDO_AccessIfOperational" SG_ 1498 PDU_OD_batterVoltageLow 1;
BA_ "GenSigStartValue" SG_ 1498 PDU_OD_batterVoltageLow 2220.0;
BA_ "CANzero_SDO_Default" SG_ 1498 PDU_OD_batterVoltageLow 22.2;
BA_ "CANzero_SDO_Group" SG_ 1498 PDU_OD_CAN2_DelayedTxMessages "CAN";
BA_ "CANzero_SDO_AccessType" SG_ 1498 PDU_OD_CAN2_DelayedTxMessages 1;
BA_ "CANzero_SDO_AccessIfOperational" SG_ 1498 PDU_OD_CAN2_DelayedTxMessages 1;
BA_ "CANzero_SDO_Group" SG_ 1498 PDU_OD_CAN2_ErrorStatus "CAN";
BA_ "CANzero_SDO_AccessType" SG_ 1498 PDU_OD_CAN2_ErrorStatus 1;
BA_ "CANzero_SDO_AccessIfOperational" SG_ 1498 PDU_OD_CAN2_ErrorStatus 1;
BA_ "CANzero_SDO_Group" SG_ 1498 PDU_OD_CAN2_DiscardedTxMessages "CAN";
BA_ "CANzero_SDO_AccessType" SG_ 1498 PDU_OD_CAN2_DiscardedTxMessages 1;
BA_ "CANzero_SDO_AccessIfOperational" SG_ 1498 PDU_OD_CAN2_DiscardedTxMessages 1;
BA_ "CANzero_SDO_Group" SG_ 1498 PDU_OD_CAN2_Status "CAN";
BA_ "CANzero_SDO_AccessType" SG_ 1498 PDU_OD_CAN2_Status 1;
BA_ "CANzero_SDO_AccessIfOperational" SG_ 1498 PDU_OD_CAN2_Status 1;
BA_ "CANzero_SDO_Group" SG_ 1498 PDU_OD_CAN2_Baudrate "CAN";
BA_ "CANzero_SDO_AccessIfOperational" SG_ 1498 PDU_OD_CAN2_Baudrate 1;
BA_ "GenSigStartValue" SG_ 1498 PDU_OD_CAN2_Baudrate 1000.0;
BA_ "CANzero_SDO_Default" SG_ 1498 PDU_OD_CAN2_Baudrate 1000;
BA_ "CANzero_SDO_Group" SG_ 1498 PDU_OD_CAN2_autoErrorReset "CAN";
BA_ "CANzero_SDO_AccessIfOperational" SG_ 1498 PDU_OD_CAN2_autoErrorReset 1;
BA_ "GenSigStartValue" SG_ 1498 PDU_OD_CAN2_autoErrorReset 1.0;
BA_ "CANzero_SDO_Default" SG_ 1498 PDU_OD_CAN2_autoErrorReset 1;
BA_ "CANzero_SDO_Group" SG_ 1498 PDU_OD_CAN2_lastErrorCode "CAN";
BA_ "CANzero_SDO_AccessType" SG_ 1498 PDU_OD_CAN2_lastErrorCode 1;
BA_ "CANzero_SDO_AccessIfOperational" SG_ 1498 PDU_OD_CAN2_lastErrorCode 1;
BA_ "CANzero_SDO_Group" SG_ 1498 PDU_OD_CAN2_RxErrCnt "CAN";
BA_ "CANzero_SDO_AccessType" SG_ 1498 PDU_OD_CAN2_RxErrCnt 1;
BA_ "CANzero_SDO_AccessIfOperational" SG_ 1498 PDU_OD_CAN2_RxErrCnt 1;
BA_ "CANzero_SDO_Group" SG_ 1498 PDU_OD_CAN2_TxErrCnt "CAN";
BA_ "CANzero_SDO_AccessType" SG_ 1498 PDU_OD_CAN2_TxErrCnt 1;
BA_ "CANzero_SDO_AccessIfOperational" SG_ 1498 PDU_OD_CAN2_TxErrCnt 1;
BA_ "CANzero_SDO_Group" SG_ 1498 PDU_OD_CAN1_DelayedTxMessages "CAN";
BA_ "CANzero_SDO_AccessType" SG_ 1498 PDU_OD_CAN1_DelayedTxMessages 1;
BA_ "CANzero_SDO_AccessIfOperational" SG_ 1498 PDU_OD_CAN1_DelayedTxMessages 1;
BA_ "CANzero_SDO_Group" SG_ 1498 PDU_OD_CAN1_ErrorStatus "CAN";
BA_ "CANzero_SDO_AccessType" SG_ 1498 PDU_OD_CAN1_ErrorStatus 1;
BA_ "CANzero_SDO_AccessIfOperational" SG_ 1498 PDU_OD_CAN1_ErrorStatus 1;
BA_ "CANzero_SDO_Group" SG_ 1498 PDU_OD_CAN1_DiscardedTxMessages "CAN";
BA_ "CANzero_SDO_AccessType" SG_ 1498 PDU_OD_CAN1_DiscardedTxMessages 1;
BA_ "CANzero_SDO_AccessIfOperational" SG_ 1498 PDU_OD_CAN1_DiscardedTxMessages 1;
BA_ "CANzero_SDO_Group" SG_ 1498 PDU_OD_CAN1_Status "CAN";
BA_ "CANzero_SDO_AccessType" SG_ 1498 PDU_OD_CAN1_Status 1;
BA_ "CANzero_SDO_AccessIfOperational" SG_ 1498 PDU_OD_CAN1_Status 1;
BA_ "CANzero_SDO_Group" SG_ 1498 PDU_OD_CAN1_Baudrate "CAN";
BA_ "CANzero_SDO_AccessIfOperational" SG_ 1498 PDU_OD_CAN1_Baudrate 1;
BA_ "GenSigStartValue" SG_ 1498 PDU_OD_CAN1_Baudrate 1000.0;
BA_ "CANzero_SDO_Default" SG_ 1498 PDU_OD_CAN1_Baudrate 1000;
BA_ "CANzero_SDO_Group" SG_ 1498 PDU_OD_CAN1_autoErrorReset "CAN";
BA_ "CANzero_SDO_AccessIfOperational" SG_ 1498 PDU_OD_CAN1_autoErrorReset 1;
BA_ "GenSigStartValue" SG_ 1498 PDU_OD_CAN1_autoErrorReset 1.0;
BA_ "CANzero_SDO_Default" SG_ 1498 PDU_OD_CAN1_autoErrorReset 1;
BA_ "CANzero_SDO_Group" SG_ 1498 PDU_OD_CAN1_lastErrorCode "CAN";
BA_ "CANzero_SDO_AccessType" SG_ 1498 PDU_OD_CAN1_lastErrorCode 1;
BA_ "CANzero_SDO_AccessIfOperational" SG_ 1498 PDU_OD_CAN1_lastErrorCode 1;
BA_ "CANzero_SDO_Group" SG_ 1498 PDU_OD_CAN1_RxErrCnt "CAN";
BA_ "CANzero_SDO_AccessType" SG_ 1498 PDU_OD_CAN1_RxErrCnt 1;
BA_ "CANzero_SDO_AccessIfOperational" SG_ 1498 PDU_OD_CAN1_RxErrCnt 1;
BA_ "CANzero_SDO_Group" SG_ 1498 PDU_OD_CAN1_TxErrCnt "CAN";
BA_ "CANzero_SDO_AccessType" SG_ 1498 PDU_OD_CAN1_TxErrCnt 1;
BA_ "CANzero_SDO_AccessIfOperational" SG_ 1498 PDU_OD_CAN1_TxErrCnt 1;
BA_ "CANzero_SDO_AccessType" SG_ 1498 PDU_OD_BuildTime 1;
BA_ "CANzero_SDO_AccessIfOperational" SG_ 1498 PDU_OD_BuildTime 1;
BA_ "CANzero_SDO_AccessType" SG_ 1498 PDU_OD_BuildDate 1;
BA_ "CANzero_SDO_AccessIfOperational" SG_ 1498 PDU_OD_BuildDate 1;
BA_ "CANzero_SDO_AccessType" SG_ 1498 PDU_OD_ChipUID2 1;
BA_ "CANzero_SDO_AccessIfOperational" SG_ 1498 PDU_OD_ChipUID2 1;
BA_ "CANzero_SDO_AccessType" SG_ 1498 PDU_OD_ChipUID1 1;
BA_ "CANzero_SDO_AccessIfOperational" SG_ 1498 PDU_OD_ChipUID1 1;
BA_ "CANzero_SDO_AccessType" SG_ 1498 PDU_OD_SdcOut 1;
BA_ "CANzero_SDO_AccessIfOperational" SG_ 1498 PDU_OD_SdcOut 1;
BA_ "CANzero_SDO_AccessType" SG_ 1498 PDU_OD_SdcIn 1;
BA_ "CANzero_SDO_AccessIfOperational" SG_ 1498 PDU_OD_SdcIn 1;
BA_ "CANzero_SDO_AccessType" SG_ 1498 PDU_OD_runtime 1;
BA_ "CANzero_SDO_AccessIfOperational" SG_ 1498 PDU_OD_runtime 1;
BA_ "CANzero_SDO_AccessType" SG_ 1498 PDU_OD_InputVoltage 1;
BA_ "CANzero_SDO_AccessIfOperational" SG_ 1498 PDU_OD_InputVoltage 1;
BA_ "CANzero_SDO_AccessType" SG_ 1498 PDU_OD_BoardTemp 1;
BA_ "CANzero_SDO_AccessIfOperational" SG_ 1498 PDU_OD_BoardTemp 1;
BA_ "GenSigStartValue" SG_ 1498 PDU_OD_BoardTemp 3000.0;
BA_ "CANzero_SDO_AccessType" SG_ 1498 PDU_OD_MemFree 1;
BA_ "CANzero_SDO_AccessIfOperational" SG_ 1498 PDU_OD_MemFree 1;
BA_ "CANzero_SDO_AccessType" SG_ 1498 PDU_OD_CpuUsage 1;
BA_ "CANzero_SDO_AccessIfOperational" SG_ 1498 PDU_OD_CpuUsage 1;
BA_ "CANzero_SDO_AccessIfOperational" SG_ 1498 PDU_OD_OdEntrySendInterval 1;
BA_ "GenSigStartValue" SG_ 1498 PDU_OD_OdEntrySendInterval 50.0;
BA_ "CANzero_SDO_Default" SG_ 1498 PDU_OD_OdEntrySendInterval 50;
BA_ "CANzero_SDO_AccessIfOperational" SG_ 1498 PDU_OD_SendOdOnBootup 1;
BA_ "CANzero_SDO_AccessIfOperational" SG_ 1498 PDU_OD_HeartbeatInterval 1;
BA_ "GenSigStartValue" SG_ 1498 PDU_OD_HeartbeatInterval 250.0;
BA_ "CANzero_SDO_Default" SG_ 1498 PDU_OD_HeartbeatInterval 250;
BA_ "CANzero_SDO_AccessType" SG_ 1498 PDU_OD_DbcVersion 1;
BA_ "CANzero_SDO_AccessIfOperational" SG_ 1498 PDU_OD_DbcVersion 1;
BA_ "CANzero_SDO_AccessType" SG_ 1498 PDU_OD_StackVersion 1;
BA_ "CANzero_SDO_AccessIfOperational" SG_ 1498 PDU_OD_StackVersion 1;
BA_ "CANzero_SDO_AccessType" SG_ 1498 PDU_OD_ProtocolVersion 1;
BA_ "CANzero_SDO_AccessIfOperational" SG_ 1498 PDU_OD_ProtocolVersion 1;
BA_ "GenSigStartValue" SG_ 1498 PDU_OD_ProtocolVersion 1.0;
BA_ "CANzero_SDO_Default" SG_ 1498 PDU_OD_ProtocolVersion 1;
BA_ "CANzero_SDO_AccessType" SG_ 1498 PDU_OD_NodeStatus 1;
BA_ "CANzero_SDO_AccessIfOperational" SG_ 1498 PDU_OD_NodeStatus 1;
BA_ "CANzero_SDO_AccessType" SG_ 1498 PDU_OD_NodeID 1;
BA_ "CANzero_SDO_AccessIfOperational" SG_ 1498 PDU_OD_NodeID 1;
BA_ "CANzero_SDO_Group" SG_ 1418 HVCU_OD_CAN2_DelayedTxMessages "CAN";
BA_ "CANzero_SDO_AccessType" SG_ 1418 HVCU_OD_CAN2_DelayedTxMessages 1;
BA_ "CANzero_SDO_AccessIfOperational" SG_ 1418 HVCU_OD_CAN2_DelayedTxMessages 1;
BA_ "CANzero_SDO_Group" SG_ 1418 HVCU_OD_CAN2_ErrorStatus "CAN";
BA_ "CANzero_SDO_AccessType" SG_ 1418 HVCU_OD_CAN2_ErrorStatus 1;
BA_ "CANzero_SDO_AccessIfOperational" SG_ 1418 HVCU_OD_CAN2_ErrorStatus 1;
BA_ "CANzero_SDO_Group" SG_ 1418 HVCU_OD_CAN2_DiscardedTxMessages "CAN";
BA_ "CANzero_SDO_AccessType" SG_ 1418 HVCU_OD_CAN2_DiscardedTxMessages 1;
BA_ "CANzero_SDO_AccessIfOperational" SG_ 1418 HVCU_OD_CAN2_DiscardedTxMessages 1;
BA_ "CANzero_SDO_Group" SG_ 1418 HVCU_OD_CAN2_Status "CAN";
BA_ "CANzero_SDO_AccessType" SG_ 1418 HVCU_OD_CAN2_Status 1;
BA_ "CANzero_SDO_AccessIfOperational" SG_ 1418 HVCU_OD_CAN2_Status 1;
BA_ "CANzero_SDO_Group" SG_ 1418 HVCU_OD_CAN2_Baudrate "CAN";
BA_ "CANzero_SDO_AccessIfOperational" SG_ 1418 HVCU_OD_CAN2_Baudrate 1;
BA_ "GenSigStartValue" SG_ 1418 HVCU_OD_CAN2_Baudrate 1000.0;
BA_ "CANzero_SDO_Default" SG_ 1418 HVCU_OD_CAN2_Baudrate 1000;
BA_ "CANzero_SDO_Group" SG_ 1418 HVCU_OD_CAN2_autoErrorReset "CAN";
BA_ "CANzero_SDO_AccessIfOperational" SG_ 1418 HVCU_OD_CAN2_autoErrorReset 1;
BA_ "GenSigStartValue" SG_ 1418 HVCU_OD_CAN2_autoErrorReset 1.0;
BA_ "CANzero_SDO_Default" SG_ 1418 HVCU_OD_CAN2_autoErrorReset 1;
BA_ "CANzero_SDO_Group" SG_ 1418 HVCU_OD_CAN2_lastErrorCode "CAN";
BA_ "CANzero_SDO_AccessType" SG_ 1418 HVCU_OD_CAN2_lastErrorCode 1;
BA_ "CANzero_SDO_AccessIfOperational" SG_ 1418 HVCU_OD_CAN2_lastErrorCode 1;
BA_ "CANzero_SDO_Group" SG_ 1418 HVCU_OD_CAN2_RxErrCnt "CAN";
BA_ "CANzero_SDO_AccessType" SG_ 1418 HVCU_OD_CAN2_RxErrCnt 1;
BA_ "CANzero_SDO_AccessIfOperational" SG_ 1418 HVCU_OD_CAN2_RxErrCnt 1;
BA_ "CANzero_SDO_Group" SG_ 1418 HVCU_OD_CAN2_TxErrCnt "CAN";
BA_ "CANzero_SDO_AccessType" SG_ 1418 HVCU_OD_CAN2_TxErrCnt 1;
BA_ "CANzero_SDO_AccessIfOperational" SG_ 1418 HVCU_OD_CAN2_TxErrCnt 1;
BA_ "CANzero_SDO_Group" SG_ 1418 HVCU_OD_CAN1_DelayedTxMessages "CAN";
BA_ "CANzero_SDO_AccessType" SG_ 1418 HVCU_OD_CAN1_DelayedTxMessages 1;
BA_ "CANzero_SDO_AccessIfOperational" SG_ 1418 HVCU_OD_CAN1_DelayedTxMessages 1;
BA_ "CANzero_SDO_Group" SG_ 1418 HVCU_OD_CAN1_ErrorStatus "CAN";
BA_ "CANzero_SDO_AccessType" SG_ 1418 HVCU_OD_CAN1_ErrorStatus 1;
BA_ "CANzero_SDO_AccessIfOperational" SG_ 1418 HVCU_OD_CAN1_ErrorStatus 1;
BA_ "CANzero_SDO_Group" SG_ 1418 HVCU_OD_CAN1_DiscardedTxMessages "CAN";
BA_ "CANzero_SDO_AccessType" SG_ 1418 HVCU_OD_CAN1_DiscardedTxMessages 1;
BA_ "CANzero_SDO_AccessIfOperational" SG_ 1418 HVCU_OD_CAN1_DiscardedTxMessages 1;
BA_ "CANzero_SDO_Group" SG_ 1418 HVCU_OD_CAN1_Status "CAN";
BA_ "CANzero_SDO_AccessType" SG_ 1418 HVCU_OD_CAN1_Status 1;
BA_ "CANzero_SDO_AccessIfOperational" SG_ 1418 HVCU_OD_CAN1_Status 1;
BA_ "CANzero_SDO_Group" SG_ 1418 HVCU_OD_CAN1_Baudrate "CAN";
BA_ "CANzero_SDO_AccessIfOperational" SG_ 1418 HVCU_OD_CAN1_Baudrate 1;
BA_ "GenSigStartValue" SG_ 1418 HVCU_OD_CAN1_Baudrate 1000.0;
BA_ "CANzero_SDO_Default" SG_ 1418 HVCU_OD_CAN1_Baudrate 1000;
BA_ "CANzero_SDO_Group" SG_ 1418 HVCU_OD_CAN1_autoErrorReset "CAN";
BA_ "CANzero_SDO_AccessIfOperational" SG_ 1418 HVCU_OD_CAN1_autoErrorReset 1;
BA_ "GenSigStartValue" SG_ 1418 HVCU_OD_CAN1_autoErrorReset 1.0;
BA_ "CANzero_SDO_Default" SG_ 1418 HVCU_OD_CAN1_autoErrorReset 1;
BA_ "CANzero_SDO_Group" SG_ 1418 HVCU_OD_CAN1_lastErrorCode "CAN";
BA_ "CANzero_SDO_AccessType" SG_ 1418 HVCU_OD_CAN1_lastErrorCode 1;
BA_ "CANzero_SDO_AccessIfOperational" SG_ 1418 HVCU_OD_CAN1_lastErrorCode 1;
BA_ "CANzero_SDO_Group" SG_ 1418 HVCU_OD_CAN1_RxErrCnt "CAN";
BA_ "CANzero_SDO_AccessType" SG_ 1418 HVCU_OD_CAN1_RxErrCnt 1;
BA_ "CANzero_SDO_AccessIfOperational" SG_ 1418 HVCU_OD_CAN1_RxErrCnt 1;
BA_ "CANzero_SDO_Group" SG_ 1418 HVCU_OD_CAN1_TxErrCnt "CAN";
BA_ "CANzero_SDO_AccessType" SG_ 1418 HVCU_OD_CAN1_TxErrCnt 1;
BA_ "CANzero_SDO_AccessIfOperational" SG_ 1418 HVCU_OD_CAN1_TxErrCnt 1;
BA_ "CANzero_SDO_AccessType" SG_ 1418 HVCU_OD_BuildTime 1;
BA_ "CANzero_SDO_AccessIfOperational" SG_ 1418 HVCU_OD_BuildTime 1;
BA_ "CANzero_SDO_AccessType" SG_ 1418 HVCU_OD_BuildDate 1;
BA_ "CANzero_SDO_AccessIfOperational" SG_ 1418 HVCU_OD_BuildDate 1;
BA_ "CANzero_SDO_AccessType" SG_ 1418 HVCU_OD_ChipUID2 1;
BA_ "CANzero_SDO_AccessIfOperational" SG_ 1418 HVCU_OD_ChipUID2 1;
BA_ "CANzero_SDO_AccessType" SG_ 1418 HVCU_OD_ChipUID1 1;
BA_ "CANzero_SDO_AccessIfOperational" SG_ 1418 HVCU_OD_ChipUID1 1;
BA_ "CANzero_SDO_AccessType" SG_ 1418 HVCU_OD_SdcOut 1;
BA_ "CANzero_SDO_AccessIfOperational" SG_ 1418 HVCU_OD_SdcOut 1;
BA_ "CANzero_SDO_AccessType" SG_ 1418 HVCU_OD_SdcIn 1;
BA_ "CANzero_SDO_AccessIfOperational" SG_ 1418 HVCU_OD_SdcIn 1;
BA_ "CANzero_SDO_AccessType" SG_ 1418 HVCU_OD_runtime 1;
BA_ "CANzero_SDO_AccessIfOperational" SG_ 1418 HVCU_OD_runtime 1;
BA_ "CANzero_SDO_AccessType" SG_ 1418 HVCU_OD_InputVoltage 1;
BA_ "CANzero_SDO_AccessIfOperational" SG_ 1418 HVCU_OD_InputVoltage 1;
BA_ "CANzero_SDO_AccessType" SG_ 1418 HVCU_OD_BoardTemp 1;
BA_ "CANzero_SDO_AccessIfOperational" SG_ 1418 HVCU_OD_BoardTemp 1;
BA_ "GenSigStartValue" SG_ 1418 HVCU_OD_BoardTemp 3000.0;
BA_ "CANzero_SDO_AccessType" SG_ 1418 HVCU_OD_MemFree 1;
BA_ "CANzero_SDO_AccessIfOperational" SG_ 1418 HVCU_OD_MemFree 1;
BA_ "CANzero_SDO_AccessType" SG_ 1418 HVCU_OD_CpuUsage 1;
BA_ "CANzero_SDO_AccessIfOperational" SG_ 1418 HVCU_OD_CpuUsage 1;
BA_ "CANzero_SDO_AccessIfOperational" SG_ 1418 HVCU_OD_OdEntrySendInterval 1;
BA_ "GenSigStartValue" SG_ 1418 HVCU_OD_OdEntrySendInterval 10.0;
BA_ "CANzero_SDO_Default" SG_ 1418 HVCU_OD_OdEntrySendInterval 10;
BA_ "CANzero_SDO_AccessIfOperational" SG_ 1418 HVCU_OD_SendOdOnBootup 1;
BA_ "CANzero_SDO_AccessIfOperational" SG_ 1418 HVCU_OD_HeartbeatInterval 1;
BA_ "GenSigStartValue" SG_ 1418 HVCU_OD_HeartbeatInterval 250.0;
BA_ "CANzero_SDO_Default" SG_ 1418 HVCU_OD_HeartbeatInterval 250;
BA_ "CANzero_SDO_AccessType" SG_ 1418 HVCU_OD_DbcVersion 1;
BA_ "CANzero_SDO_AccessIfOperational" SG_ 1418 HVCU_OD_DbcVersion 1;
BA_ "CANzero_SDO_AccessType" SG_ 1418 HVCU_OD_StackVersion 1;
BA_ "CANzero_SDO_AccessIfOperational" SG_ 1418 HVCU_OD_StackVersion 1;
BA_ "CANzero_SDO_AccessType" SG_ 1418 HVCU_OD_ProtocolVersion 1;
BA_ "CANzero_SDO_AccessIfOperational" SG_ 1418 HVCU_OD_ProtocolVersion 1;
BA_ "GenSigStartValue" SG_ 1418 HVCU_OD_ProtocolVersion 1.0;
BA_ "CANzero_SDO_Default" SG_ 1418 HVCU_OD_ProtocolVersion 1;
BA_ "CANzero_SDO_AccessType" SG_ 1418 HVCU_OD_NodeStatus 1;
BA_ "CANzero_SDO_AccessIfOperational" SG_ 1418 HVCU_OD_NodeStatus 1;
BA_ "CANzero_SDO_AccessType" SG_ 1418 HVCU_OD_NodeID 1;
BA_ "CANzero_SDO_AccessIfOperational" SG_ 1418 HVCU_OD_NodeID 1;
BA_ "CANzero_SDO_Group" SG_ 1482 HVCU_OD_CAN2_DelayedTxMessages "CAN";
BA_ "CANzero_SDO_AccessType" SG_ 1482 HVCU_OD_CAN2_DelayedTxMessages 1;
BA_ "CANzero_SDO_AccessIfOperational" SG_ 1482 HVCU_OD_CAN2_DelayedTxMessages 1;
BA_ "CANzero_SDO_Group" SG_ 1482 HVCU_OD_CAN2_ErrorStatus "CAN";
BA_ "CANzero_SDO_AccessType" SG_ 1482 HVCU_OD_CAN2_ErrorStatus 1;
BA_ "CANzero_SDO_AccessIfOperational" SG_ 1482 HVCU_OD_CAN2_ErrorStatus 1;
BA_ "CANzero_SDO_Group" SG_ 1482 HVCU_OD_CAN2_DiscardedTxMessages "CAN";
BA_ "CANzero_SDO_AccessType" SG_ 1482 HVCU_OD_CAN2_DiscardedTxMessages 1;
BA_ "CANzero_SDO_AccessIfOperational" SG_ 1482 HVCU_OD_CAN2_DiscardedTxMessages 1;
BA_ "CANzero_SDO_Group" SG_ 1482 HVCU_OD_CAN2_Status "CAN";
BA_ "CANzero_SDO_AccessType" SG_ 1482 HVCU_OD_CAN2_Status 1;
BA_ "CANzero_SDO_AccessIfOperational" SG_ 1482 HVCU_OD_CAN2_Status 1;
BA_ "CANzero_SDO_Group" SG_ 1482 HVCU_OD_CAN2_Baudrate "CAN";
BA_ "CANzero_SDO_AccessIfOperational" SG_ 1482 HVCU_OD_CAN2_Baudrate 1;
BA_ "GenSigStartValue" SG_ 1482 HVCU_OD_CAN2_Baudrate 1000.0;
BA_ "CANzero_SDO_Default" SG_ 1482 HVCU_OD_CAN2_Baudrate 1000;
BA_ "CANzero_SDO_Group" SG_ 1482 HVCU_OD_CAN2_autoErrorReset "CAN";
BA_ "CANzero_SDO_AccessIfOperational" SG_ 1482 HVCU_OD_CAN2_autoErrorReset 1;
BA_ "GenSigStartValue" SG_ 1482 HVCU_OD_CAN2_autoErrorReset 1.0;
BA_ "CANzero_SDO_Default" SG_ 1482 HVCU_OD_CAN2_autoErrorReset 1;
BA_ "CANzero_SDO_Group" SG_ 1482 HVCU_OD_CAN2_lastErrorCode "CAN";
BA_ "CANzero_SDO_AccessType" SG_ 1482 HVCU_OD_CAN2_lastErrorCode 1;
BA_ "CANzero_SDO_AccessIfOperational" SG_ 1482 HVCU_OD_CAN2_lastErrorCode 1;
BA_ "CANzero_SDO_Group" SG_ 1482 HVCU_OD_CAN2_RxErrCnt "CAN";
BA_ "CANzero_SDO_AccessType" SG_ 1482 HVCU_OD_CAN2_RxErrCnt 1;
BA_ "CANzero_SDO_AccessIfOperational" SG_ 1482 HVCU_OD_CAN2_RxErrCnt 1;
BA_ "CANzero_SDO_Group" SG_ 1482 HVCU_OD_CAN2_TxErrCnt "CAN";
BA_ "CANzero_SDO_AccessType" SG_ 1482 HVCU_OD_CAN2_TxErrCnt 1;
BA_ "CANzero_SDO_AccessIfOperational" SG_ 1482 HVCU_OD_CAN2_TxErrCnt 1;
BA_ "CANzero_SDO_Group" SG_ 1482 HVCU_OD_CAN1_DelayedTxMessages "CAN";
BA_ "CANzero_SDO_AccessType" SG_ 1482 HVCU_OD_CAN1_DelayedTxMessages 1;
BA_ "CANzero_SDO_AccessIfOperational" SG_ 1482 HVCU_OD_CAN1_DelayedTxMessages 1;
BA_ "CANzero_SDO_Group" SG_ 1482 HVCU_OD_CAN1_ErrorStatus "CAN";
BA_ "CANzero_SDO_AccessType" SG_ 1482 HVCU_OD_CAN1_ErrorStatus 1;
BA_ "CANzero_SDO_AccessIfOperational" SG_ 1482 HVCU_OD_CAN1_ErrorStatus 1;
BA_ "CANzero_SDO_Group" SG_ 1482 HVCU_OD_CAN1_DiscardedTxMessages "CAN";
BA_ "CANzero_SDO_AccessType" SG_ 1482 HVCU_OD_CAN1_DiscardedTxMessages 1;
BA_ "CANzero_SDO_AccessIfOperational" SG_ 1482 HVCU_OD_CAN1_DiscardedTxMessages 1;
BA_ "CANzero_SDO_Group" SG_ 1482 HVCU_OD_CAN1_Status "CAN";
BA_ "CANzero_SDO_AccessType" SG_ 1482 HVCU_OD_CAN1_Status 1;
BA_ "CANzero_SDO_AccessIfOperational" SG_ 1482 HVCU_OD_CAN1_Status 1;
BA_ "CANzero_SDO_Group" SG_ 1482 HVCU_OD_CAN1_Baudrate "CAN";
BA_ "CANzero_SDO_AccessIfOperational" SG_ 1482 HVCU_OD_CAN1_Baudrate 1;
BA_ "GenSigStartValue" SG_ 1482 HVCU_OD_CAN1_Baudrate 1000.0;
BA_ "CANzero_SDO_Default" SG_ 1482 HVCU_OD_CAN1_Baudrate 1000;
BA_ "CANzero_SDO_Group" SG_ 1482 HVCU_OD_CAN1_autoErrorReset "CAN";
BA_ "CANzero_SDO_AccessIfOperational" SG_ 1482 HVCU_OD_CAN1_autoErrorReset 1;
BA_ "GenSigStartValue" SG_ 1482 HVCU_OD_CAN1_autoErrorReset 1.0;
BA_ "CANzero_SDO_Default" SG_ 1482 HVCU_OD_CAN1_autoErrorReset 1;
BA_ "CANzero_SDO_Group" SG_ 1482 HVCU_OD_CAN1_lastErrorCode "CAN";
BA_ "CANzero_SDO_AccessType" SG_ 1482 HVCU_OD_CAN1_lastErrorCode 1;
BA_ "CANzero_SDO_AccessIfOperational" SG_ 1482 HVCU_OD_CAN1_lastErrorCode 1;
BA_ "CANzero_SDO_Group" SG_ 1482 HVCU_OD_CAN1_RxErrCnt "CAN";
BA_ "CANzero_SDO_AccessType" SG_ 1482 HVCU_OD_CAN1_RxErrCnt 1;
BA_ "CANzero_SDO_AccessIfOperational" SG_ 1482 HVCU_OD_CAN1_RxErrCnt 1;
BA_ "CANzero_SDO_Group" SG_ 1482 HVCU_OD_CAN1_TxErrCnt "CAN";
BA_ "CANzero_SDO_AccessType" SG_ 1482 HVCU_OD_CAN1_TxErrCnt 1;
BA_ "CANzero_SDO_AccessIfOperational" SG_ 1482 HVCU_OD_CAN1_TxErrCnt 1;
BA_ "CANzero_SDO_AccessType" SG_ 1482 HVCU_OD_BuildTime 1;
BA_ "CANzero_SDO_AccessIfOperational" SG_ 1482 HVCU_OD_BuildTime 1;
BA_ "CANzero_SDO_AccessType" SG_ 1482 HVCU_OD_BuildDate 1;
BA_ "CANzero_SDO_AccessIfOperational" SG_ 1482 HVCU_OD_BuildDate 1;
BA_ "CANzero_SDO_AccessType" SG_ 1482 HVCU_OD_ChipUID2 1;
BA_ "CANzero_SDO_AccessIfOperational" SG_ 1482 HVCU_OD_ChipUID2 1;
BA_ "CANzero_SDO_AccessType" SG_ 1482 HVCU_OD_ChipUID1 1;
BA_ "CANzero_SDO_AccessIfOperational" SG_ 1482 HVCU_OD_ChipUID1 1;
BA_ "CANzero_SDO_AccessType" SG_ 1482 HVCU_OD_SdcOut 1;
BA_ "CANzero_SDO_AccessIfOperational" SG_ 1482 HVCU_OD_SdcOut 1;
BA_ "CANzero_SDO_AccessType" SG_ 1482 HVCU_OD_SdcIn 1;
BA_ "CANzero_SDO_AccessIfOperational" SG_ 1482 HVCU_OD_SdcIn 1;
BA_ "CANzero_SDO_AccessType" SG_ 1482 HVCU_OD_runtime 1;
BA_ "CANzero_SDO_AccessIfOperational" SG_ 1482 HVCU_OD_runtime 1;
BA_ "CANzero_SDO_AccessType" SG_ 1482 HVCU_OD_InputVoltage 1;
BA_ "CANzero_SDO_AccessIfOperational" SG_ 1482 HVCU_OD_InputVoltage 1;
BA_ "CANzero_SDO_AccessType" SG_ 1482 HVCU_OD_BoardTemp 1;
BA_ "CANzero_SDO_AccessIfOperational" SG_ 1482 HVCU_OD_BoardTemp 1;
BA_ "GenSigStartValue" SG_ 1482 HVCU_OD_BoardTemp 3000.0;
BA_ "CANzero_SDO_AccessType" SG_ 1482 HVCU_OD_MemFree 1;
BA_ "CANzero_SDO_AccessIfOperational" SG_ 1482 HVCU_OD_MemFree 1;
BA_ "CANzero_SDO_AccessType" SG_ 1482 HVCU_OD_CpuUsage 1;
BA_ "CANzero_SDO_AccessIfOperational" SG_ 1482 HVCU_OD_CpuUsage 1;
BA_ "CANzero_SDO_AccessIfOperational" SG_ 1482 HVCU_OD_OdEntrySendInterval 1;
BA_ "GenSigStartValue" SG_ 1482 HVCU_OD_OdEntrySendInterval 10.0;
BA_ "CANzero_SDO_Default" SG_ 1482 HVCU_OD_OdEntrySendInterval 10;
BA_ "CANzero_SDO_AccessIfOperational" SG_ 1482 HVCU_OD_SendOdOnBootup 1;
BA_ "CANzero_SDO_AccessIfOperational" SG_ 1482 HVCU_OD_HeartbeatInterval 1;
BA_ "GenSigStartValue" SG_ 1482 HVCU_OD_HeartbeatInterval 250.0;
BA_ "CANzero_SDO_Default" SG_ 1482 HVCU_OD_HeartbeatInterval 250;
BA_ "CANzero_SDO_AccessType" SG_ 1482 HVCU_OD_DbcVersion 1;
BA_ "CANzero_SDO_AccessIfOperational" SG_ 1482 HVCU_OD_DbcVersion 1;
BA_ "CANzero_SDO_AccessType" SG_ 1482 HVCU_OD_StackVersion 1;
BA_ "CANzero_SDO_AccessIfOperational" SG_ 1482 HVCU_OD_StackVersion 1;
BA_ "CANzero_SDO_AccessType" SG_ 1482 HVCU_OD_ProtocolVersion 1;
BA_ "CANzero_SDO_AccessIfOperational" SG_ 1482 HVCU_OD_ProtocolVersion 1;
BA_ "GenSigStartValue" SG_ 1482 HVCU_OD_ProtocolVersion 1.0;
BA_ "CANzero_SDO_Default" SG_ 1482 HVCU_OD_ProtocolVersion 1;
BA_ "CANzero_SDO_AccessType" SG_ 1482 HVCU_OD_NodeStatus 1;
BA_ "CANzero_SDO_AccessIfOperational" SG_ 1482 HVCU_OD_NodeStatus 1;
BA_ "CANzero_SDO_AccessType" SG_ 1482 HVCU_OD_NodeID 1;
BA_ "CANzero_SDO_AccessIfOperational" SG_ 1482 HVCU_OD_NodeID 1;
BA_ "GenMsgCycleTime" BO_ 1456 10;
BA_ "GenMsgSendType" BO_ 1456 0;
BA_ "GenSigStartValue" SG_ 1299 SCIMO_MOT2_A3 100;
BA_ "GenSigStartValue" SG_ 1299 SCIMO_MOT2_A2 100;
BA_ "GenSigStartValue" SG_ 1299 SCIMO_MOT2_A1 100;
BA_ "GenMsgCycleTime" BO_ 1280 10;
BA_ "GenMsgSendType" BO_ 1280 0;
BA_ "GenMsgSendType" BO_ 1296 0;
BA_ "GenMsgCycleTime" BO_ 1296 10;
BA_ "SystemSignalLongSymbol" SG_ 2578777089 EMUS_ContactorControl_ContactorS "EMUS_ContactorControl_ContactorState";
VAL_ 401 BrakeF_TX_SDC_Input 1 "Closed" 0 "Open" ;
VAL_ 401 BrakeF_TX_ErrorFlag 1 "Error" 0 "No Error" ;
VAL_ 401 BrakeF_TX_Enabled 1 "Enabled" 0 "Disabled" ;
VAL_ 401 BrakeF_TX_Status 2 "EngagedService" 1 "EngagedEmergency" 0 "Disengaged" ;
VAL_ 465 BrakeF_RX_Engage 2 "EngageService" 1 "EngageEmergency" 0 "Disengage" ;
VAL_ 465 BrakeF_RX_Enable 1 "Enable" 0 "Disable" ;
VAL_ 465 BrakeF_RX_ErrorReset 1 "Reset" 0 "No Reset" ;
VAL_ 1425 BrakeF_OD_BrakeStatus 0 "Disengaged" 1 "Engaged" ;
VAL_ 1425 BrakeF_OD_CAN2_ErrorStatus 0 "Ok" 1 "Warn" 2 "Error Passive" 3 "Bus Off" ;
VAL_ 1425 BrakeF_OD_CAN2_Status 0 "Reset" 1 "Ready" 2 "Listening" 3 "Sleep_Pending" 4 "Sleep_Active" 5 "ERROR" ;
VAL_ 1425 BrakeF_OD_CAN2_autoErrorReset 0 "Disabled" 1 "Enabled" ;
VAL_ 1425 BrakeF_OD_CAN2_lastErrorCode 0 "No Error" 1 "Stuff Error" 2 "Form Error" 3 "Ack Error" 4 "Bit recessive Error" 5 "Bit dominant Error" 6 "CRC Error" ;
VAL_ 1425 BrakeF_OD_CAN1_ErrorStatus 0 "Ok" 1 "Warn" 2 "Error Passive" 3 "Bus Off" ;
VAL_ 1425 BrakeF_OD_CAN1_Status 0 "Reset" 1 "Ready" 2 "Listening" 3 "Sleep_Pending" 4 "Sleep_Active" 5 "ERROR" ;
VAL_ 1425 BrakeF_OD_CAN1_autoErrorReset 0 "Disabled" 1 "Enabled" ;
VAL_ 1425 BrakeF_OD_CAN1_lastErrorCode 0 "No Error" 1 "Stuff Error" 2 "Form Error" 3 "Ack Error" 4 "Bit recessive Error" 5 "Bit dominant Error" 6 "CRC Error" ;
VAL_ 1425 BrakeF_OD_SendOdOnBootup 0 "Disabled" 1 "Enabled" ;
VAL_ 1425 BrakeF_OD_NodeStatus 0 "Bootup" 4 "Stopped" 5 "Operational" 127 "Pre-Operational" 128 "Reset" ;
VAL_ 1425 BrakeF_SDO_RespCode 5 "ERR: Out of range" 4 "ERR: No access in this state" 3 "ERR: Read only object" 2 "ERR: Write only object" 1 "ERR: Non existing object" 0 "OK" ;
VAL_ 1425 BrakeF_SDO_ID 0 "Reserved" 1 "NodeID" 2 "NodeStatus" 3 "ProtocolVersion" 4 "StackVersion" 5 "DbcVersion" 16 "HeartbeatInterval" 32 "SendOdOnBootup" 33 "OdEntrySendInterval" 1040 "CpuUsage" 1041 "MemFree" 1042 "BoardTemp" 1043 "InputVoltage" 1044 "runtime" 1045 "SdcIn" 1046 "SdcOut" 1056 "ChipUID1" 1057 "ChipUID2" 1072 "BuildDate" 1073 "BuildTime" 1104 "CAN1_TxErrCnt" 1105 "CAN1_RxErrCnt" 1106 "CAN1_lastErrorCode" 1107 "CAN1_autoErrorReset" 1108 "CAN1_Baudrate" 1110 "CAN1_Status" 1111 "CAN1_DiscardedTxMessages" 1112 "CAN1_ErrorStatus" 1113 "CAN1_DelayedTxMessages" 1120 "CAN2_TxErrCnt" 1121 "CAN2_RxErrCnt" 1122 "CAN2_lastErrorCode" 1123 "CAN2_autoErrorReset" 1124 "CAN2_Baudrate" 1126 "CAN2_Status" 1127 "CAN2_DiscardedTxMessages" 1128 "CAN2_ErrorStatus" 1129 "CAN2_DelayedTxMessages" 2048 "tankLowerControlLimit" 2049 "tankUpperControlLimit" 2050 "delay" 2051 "counterLimit" 2052 "commWatchdog" 2053 "valveUpperTolerance" 2816 "CoolingPressure" 2304 "BrakeStatus" ;
VAL_ 1489 BrakeF_OD_BrakeStatus 0 "Disengaged" 1 "Engaged" ;
VAL_ 1489 BrakeF_OD_CAN2_ErrorStatus 0 "Ok" 1 "Warn" 2 "Error Passive" 3 "Bus Off" ;
VAL_ 1489 BrakeF_OD_CAN2_Status 0 "Reset" 1 "Ready" 2 "Listening" 3 "Sleep_Pending" 4 "Sleep_Active" 5 "ERROR" ;
VAL_ 1489 BrakeF_OD_CAN2_autoErrorReset 0 "Disabled" 1 "Enabled" ;
VAL_ 1489 BrakeF_OD_CAN2_lastErrorCode 0 "No Error" 1 "Stuff Error" 2 "Form Error" 3 "Ack Error" 4 "Bit recessive Error" 5 "Bit dominant Error" 6 "CRC Error" ;
VAL_ 1489 BrakeF_OD_CAN1_ErrorStatus 0 "Ok" 1 "Warn" 2 "Error Passive" 3 "Bus Off" ;
VAL_ 1489 BrakeF_OD_CAN1_Status 0 "Reset" 1 "Ready" 2 "Listening" 3 "Sleep_Pending" 4 "Sleep_Active" 5 "ERROR" ;
VAL_ 1489 BrakeF_OD_CAN1_autoErrorReset 0 "Disabled" 1 "Enabled" ;
VAL_ 1489 BrakeF_OD_CAN1_lastErrorCode 0 "No Error" 1 "Stuff Error" 2 "Form Error" 3 "Ack Error" 4 "Bit recessive Error" 5 "Bit dominant Error" 6 "CRC Error" ;
VAL_ 1489 BrakeF_OD_SendOdOnBootup 0 "Disabled" 1 "Enabled" ;
VAL_ 1489 BrakeF_OD_NodeStatus 0 "Bootup" 4 "Stopped" 5 "Operational" 127 "Pre-Operational" 128 "Reset" ;
VAL_ 1489 BrakeF_SDO_ID 0 "Reserved" 1 "NodeID" 2 "NodeStatus" 3 "ProtocolVersion" 4 "StackVersion" 5 "DbcVersion" 16 "HeartbeatInterval" 32 "SendOdOnBootup" 33 "OdEntrySendInterval" 1040 "CpuUsage" 1041 "MemFree" 1042 "BoardTemp" 1043 "InputVoltage" 1044 "runtime" 1045 "SdcIn" 1046 "SdcOut" 1056 "ChipUID1" 1057 "ChipUID2" 1072 "BuildDate" 1073 "BuildTime" 1104 "CAN1_TxErrCnt" 1105 "CAN1_RxErrCnt" 1106 "CAN1_lastErrorCode" 1107 "CAN1_autoErrorReset" 1108 "CAN1_Baudrate" 1110 "CAN1_Status" 1111 "CAN1_DiscardedTxMessages" 1112 "CAN1_ErrorStatus" 1113 "CAN1_DelayedTxMessages" 1120 "CAN2_TxErrCnt" 1121 "CAN2_RxErrCnt" 1122 "CAN2_lastErrorCode" 1123 "CAN2_autoErrorReset" 1124 "CAN2_Baudrate" 1126 "CAN2_Status" 1127 "CAN2_DiscardedTxMessages" 1128 "CAN2_ErrorStatus" 1129 "CAN2_DelayedTxMessages" 2048 "tankLowerControlLimit" 2049 "tankUpperControlLimit" 2050 "delay" 2051 "counterLimit" 2052 "commWatchdog" 2053 "valveUpperTolerance" 2816 "CoolingPressure" 2304 "BrakeStatus" ;
VAL_ 1553 BrakeF_SDO_ID 0 "Reserved" 1 "NodeID" 2 "NodeStatus" 3 "ProtocolVersion" 4 "StackVersion" 5 "DbcVersion" 16 "HeartbeatInterval" 32 "SendOdOnBootup" 33 "OdEntrySendInterval" 1040 "CpuUsage" 1041 "MemFree" 1042 "BoardTemp" 1043 "InputVoltage" 1044 "runtime" 1045 "SdcIn" 1046 "SdcOut" 1056 "ChipUID1" 1057 "ChipUID2" 1072 "BuildDate" 1073 "BuildTime" 1104 "CAN1_TxErrCnt" 1105 "CAN1_RxErrCnt" 1106 "CAN1_lastErrorCode" 1107 "CAN1_autoErrorReset" 1108 "CAN1_Baudrate" 1110 "CAN1_Status" 1111 "CAN1_DiscardedTxMessages" 1112 "CAN1_ErrorStatus" 1113 "CAN1_DelayedTxMessages" 1120 "CAN2_TxErrCnt" 1121 "CAN2_RxErrCnt" 1122 "CAN2_lastErrorCode" 1123 "CAN2_autoErrorReset" 1124 "CAN2_Baudrate" 1126 "CAN2_Status" 1127 "CAN2_DiscardedTxMessages" 1128 "CAN2_ErrorStatus" 1129 "CAN2_DelayedTxMessages" 2048 "tankLowerControlLimit" 2049 "tankUpperControlLimit" 2050 "delay" 2051 "counterLimit" 2052 "commWatchdog" 2053 "valveUpperTolerance" 2816 "CoolingPressure" 2304 "BrakeStatus" ;
VAL_ 1809 BrakeF_NodeState 0 "Bootup" 4 "Stopped" 5 "Operational" 127 "Pre-Operational" ;
VAL_ 146 BrakeR_E5_retractUnsuccesful_ope 0 "Ok" 1 "ERR" ;
VAL_ 146 BrakeR_E4_retractUnsuccesful_not 0 "Ok" 1 "ERR" ;
VAL_ 146 BrakeR_E3_retractUnsuccesful_err 0 "Ok" 1 "ERR" ;
VAL_ 146 BrakeR_E2_commWatchdogTimeout 0 "Ok" 1 "ERR" ;
VAL_ 146 BrakeR_E1_pressureTooLow 0 "Ok" 1 "ERR" ;
VAL_ 146 BrakeR_E0_pressureTooHigh 0 "Ok" 1 "ERR" ;
VAL_ 146 BrakeR_W3_externalError 0 "Ok" 1 "WARN" ;
VAL_ 146 BrakeR_W2_enableWithAnError 0 "Ok" 1 "WARN" ;
VAL_ 146 BrakeR_W1_highPressureRetracting 0 "Ok" 1 "WARN" ;
VAL_ 146 BrakeR_W0_highPressureActingCham 0 "Ok" 1 "WARN" ;
VAL_ 402 BrakeR_TX_SDC_Input 1 "Closed" 0 "Open" ;
VAL_ 402 BrakeR_TX_ErrorFlag 1 "Error" 0 "No Error" ;
VAL_ 402 BrakeR_TX_Enabled 1 "Enabled" 0 "Disabled" ;
VAL_ 402 BrakeR_TX_Status 2 "EngagedService" 1 "EngagedEmergency" 0 "Disengaged" ;
VAL_ 466 BrakeR_RX_Engage 2 "EngageService" 1 "EngageEmergency" 0 "Disengage" ;
VAL_ 466 BrakeR_RX_Enable 1 "Enable" 0 "Disable" ;
VAL_ 466 BrakeR_RX_ErrorReset 1 "Reset" 0 "No Reset" ;
VAL_ 1426 BrakeR_OD_CAN2_ErrorStatus 0 "Ok" 1 "Warn" 2 "Error Passive" 3 "Bus Off" ;
VAL_ 1426 BrakeR_OD_CAN2_Status 0 "Reset" 1 "Ready" 2 "Listening" 3 "Sleep_Pending" 4 "Sleep_Active" 5 "ERROR" ;
VAL_ 1426 BrakeR_OD_CAN2_autoErrorReset 0 "Disabled" 1 "Enabled" ;
VAL_ 1426 BrakeR_OD_CAN2_lastErrorCode 0 "No Error" 1 "Stuff Error" 2 "Form Error" 3 "Ack Error" 4 "Bit recessive Error" 5 "Bit dominant Error" 6 "CRC Error" ;
VAL_ 1426 BrakeR_OD_CAN1_ErrorStatus 0 "Ok" 1 "Warn" 2 "Error Passive" 3 "Bus Off" ;
VAL_ 1426 BrakeR_OD_CAN1_Status 0 "Reset" 1 "Ready" 2 "Listening" 3 "Sleep_Pending" 4 "Sleep_Active" 5 "ERROR" ;
VAL_ 1426 BrakeR_OD_CAN1_autoErrorReset 0 "Disabled" 1 "Enabled" ;
VAL_ 1426 BrakeR_OD_CAN1_lastErrorCode 0 "No Error" 1 "Stuff Error" 2 "Form Error" 3 "Ack Error" 4 "Bit recessive Error" 5 "Bit dominant Error" 6 "CRC Error" ;
VAL_ 1426 BrakeR_OD_SendOdOnBootup 0 "Disabled" 1 "Enabled" ;
VAL_ 1426 BrakeR_OD_NodeStatus 0 "Bootup" 4 "Stopped" 5 "Operational" 127 "Pre-Operational" 128 "Reset" ;
VAL_ 1426 BrakeR_SDO_RespCode 5 "ERR: Out of range" 4 "ERR: No access in this state" 3 "ERR: Read only object" 2 "ERR: Write only object" 1 "ERR: Non existing object" 0 "OK" ;
VAL_ 1426 BrakeR_SDO_ID 0 "Reserved" 1 "NodeID" 2 "NodeStatus" 3 "ProtocolVersion" 4 "StackVersion" 5 "DbcVersion" 16 "HeartbeatInterval" 32 "SendOdOnBootup" 33 "OdEntrySendInterval" 1040 "CpuUsage" 1041 "MemFree" 1042 "BoardTemp" 1043 "InputVoltage" 1044 "runtime" 1045 "SdcIn" 1046 "SdcOut" 1056 "ChipUID1" 1057 "ChipUID2" 1072 "BuildDate" 1073 "BuildTime" 1104 "CAN1_TxErrCnt" 1105 "CAN1_RxErrCnt" 1106 "CAN1_lastErrorCode" 1107 "CAN1_autoErrorReset" 1108 "CAN1_Baudrate" 1110 "CAN1_Status" 1111 "CAN1_DiscardedTxMessages" 1112 "CAN1_ErrorStatus" 1113 "CAN1_DelayedTxMessages" 1120 "CAN2_TxErrCnt" 1121 "CAN2_RxErrCnt" 1122 "CAN2_lastErrorCode" 1123 "CAN2_autoErrorReset" 1124 "CAN2_Baudrate" 1126 "CAN2_Status" 1127 "CAN2_DiscardedTxMessages" 1128 "CAN2_ErrorStatus" 1129 "CAN2_DelayedTxMessages" 2048 "tankLowerControlLimit" 2049 "tankUpperControlLimit" 2050 "delay" 2051 "counterLimit" 2052 "commWatchdog" 2053 "valveUpperTolerance" ;
VAL_ 1490 BrakeR_OD_CAN2_ErrorStatus 0 "Ok" 1 "Warn" 2 "Error Passive" 3 "Bus Off" ;
VAL_ 1490 BrakeR_OD_CAN2_Status 0 "Reset" 1 "Ready" 2 "Listening" 3 "Sleep_Pending" 4 "Sleep_Active" 5 "ERROR" ;
VAL_ 1490 BrakeR_OD_CAN2_autoErrorReset 0 "Disabled" 1 "Enabled" ;
VAL_ 1490 BrakeR_OD_CAN2_lastErrorCode 0 "No Error" 1 "Stuff Error" 2 "Form Error" 3 "Ack Error" 4 "Bit recessive Error" 5 "Bit dominant Error" 6 "CRC Error" ;
VAL_ 1490 BrakeR_OD_CAN1_ErrorStatus 0 "Ok" 1 "Warn" 2 "Error Passive" 3 "Bus Off" ;
VAL_ 1490 BrakeR_OD_CAN1_Status 0 "Reset" 1 "Ready" 2 "Listening" 3 "Sleep_Pending" 4 "Sleep_Active" 5 "ERROR" ;
VAL_ 1490 BrakeR_OD_CAN1_autoErrorReset 0 "Disabled" 1 "Enabled" ;
VAL_ 1490 BrakeR_OD_CAN1_lastErrorCode 0 "No Error" 1 "Stuff Error" 2 "Form Error" 3 "Ack Error" 4 "Bit recessive Error" 5 "Bit dominant Error" 6 "CRC Error" ;
VAL_ 1490 BrakeR_OD_SendOdOnBootup 0 "Disabled" 1 "Enabled" ;
VAL_ 1490 BrakeR_OD_NodeStatus 0 "Bootup" 4 "Stopped" 5 "Operational" 127 "Pre-Operational" 128 "Reset" ;
VAL_ 1490 BrakeR_SDO_ID 0 "Reserved" 1 "NodeID" 2 "NodeStatus" 3 "ProtocolVersion" 4 "StackVersion" 5 "DbcVersion" 16 "HeartbeatInterval" 32 "SendOdOnBootup" 33 "OdEntrySendInterval" 1040 "CpuUsage" 1041 "MemFree" 1042 "BoardTemp" 1043 "InputVoltage" 1044 "runtime" 1045 "SdcIn" 1046 "SdcOut" 1056 "ChipUID1" 1057 "ChipUID2" 1072 "BuildDate" 1073 "BuildTime" 1104 "CAN1_TxErrCnt" 1105 "CAN1_RxErrCnt" 1106 "CAN1_lastErrorCode" 1107 "CAN1_autoErrorReset" 1108 "CAN1_Baudrate" 1110 "CAN1_Status" 1111 "CAN1_DiscardedTxMessages" 1112 "CAN1_ErrorStatus" 1113 "CAN1_DelayedTxMessages" 1120 "CAN2_TxErrCnt" 1121 "CAN2_RxErrCnt" 1122 "CAN2_lastErrorCode" 1123 "CAN2_autoErrorReset" 1124 "CAN2_Baudrate" 1126 "CAN2_Status" 1127 "CAN2_DiscardedTxMessages" 1128 "CAN2_ErrorStatus" 1129 "CAN2_DelayedTxMessages" 2048 "tankLowerControlLimit" 2049 "tankUpperControlLimit" 2050 "delay" 2051 "counterLimit" 2052 "commWatchdog" 2053 "valveUpperTolerance" ;
VAL_ 1554 BrakeR_SDO_ID 0 "Reserved" 1 "NodeID" 2 "NodeStatus" 3 "ProtocolVersion" 4 "StackVersion" 5 "DbcVersion" 16 "HeartbeatInterval" 32 "SendOdOnBootup" 33 "OdEntrySendInterval" 1040 "CpuUsage" 1041 "MemFree" 1042 "BoardTemp" 1043 "InputVoltage" 1044 "runtime" 1045 "SdcIn" 1046 "SdcOut" 1056 "ChipUID1" 1057 "ChipUID2" 1072 "BuildDate" 1073 "BuildTime" 1104 "CAN1_TxErrCnt" 1105 "CAN1_RxErrCnt" 1106 "CAN1_lastErrorCode" 1107 "CAN1_autoErrorReset" 1108 "CAN1_Baudrate" 1110 "CAN1_Status" 1111 "CAN1_DiscardedTxMessages" 1112 "CAN1_ErrorStatus" 1113 "CAN1_DelayedTxMessages" 1120 "CAN2_TxErrCnt" 1121 "CAN2_RxErrCnt" 1122 "CAN2_lastErrorCode" 1123 "CAN2_autoErrorReset" 1124 "CAN2_Baudrate" 1126 "CAN2_Status" 1127 "CAN2_DiscardedTxMessages" 1128 "CAN2_ErrorStatus" 1129 "CAN2_DelayedTxMessages" 2048 "tankLowerControlLimit" 2049 "tankUpperControlLimit" 2050 "delay" 2051 "counterLimit" 2052 "commWatchdog" 2053 "valveUpperTolerance" ;
VAL_ 1810 BrakeR_NodeState 0 "Bootup" 4 "Stopped" 5 "Operational" 127 "Pre-Operational" ;
VAL_ 154 PDU_E4_watchdogStateMachine 0 "Ok" 1 "ERR" ;
VAL_ 154 PDU_E3_batterTempCritical 0 "Ok" 1 "ERR" ;
VAL_ 154 PDU_E2_batteryOvercurrent 0 "Ok" 1 "ERR" ;
VAL_ 154 PDU_E1_batterVoltageCritical 0 "Ok" 1 "ERR" ;
VAL_ 154 PDU_E0_OtherError 0 "Ok" 1 "ERR" ;
VAL_ 154 PDU_W2_batterTempHigh 0 "Ok" 1 "WARN" ;
VAL_ 154 PDU_W1_batterVoltageLow 0 "Ok" 1 "WARN" ;
VAL_ 154 PDU_W0_OtherWarning 0 "Ok" 1 "WARN" ;
VAL_ 410 PDU_TX_PEHWEnabled 1 "Enabled" 0 "Disabled" ;
VAL_ 410 PDU_TX_ErrorFlag 1 "Error" 0 "No Error" ;
VAL_ 410 PDU_TX_Enabled 1 "Enabled" 0 "Disabled" ;
VAL_ 474 PDU_RX_PEHWEnable 1 "Enable" 0 "Disable" ;
VAL_ 474 PDU_RX_ErrorReset 1 "Reset" 0 "No Reset" ;
VAL_ 474 PDU_RX_Enable 1 "Enable" 0 "Disable" ;
VAL_ 1178 PDU_LPCh1_State 3 "External Voltage" 2 "Output Short Circuit" 1 "Status Change Pending" 0 "OK" ;
VAL_ 1434 PDU_OD_CoolingPumpEnabled 0 "Disable" 1 "Enable" ;
VAL_ 1434 PDU_OD_LedCommands 0 "None" 1 "whipeanimation" 2 "mugreenanimation" 3 "rainbowanimation" 4 "flashlights" 5 "snakeanimation" 6 "blinkpink" 7 "multiwhipe" 8 "Emergency" ;
VAL_ 1434 PDU_OD_projectXXEnabled 0 "Disable" 1 "Enable" ;
VAL_ 1434 PDU_OD_CAN2_ErrorStatus 0 "Ok" 1 "Warn" 2 "Error Passive" 3 "Bus Off" ;
VAL_ 1434 PDU_OD_CAN2_Status 0 "Reset" 1 "Ready" 2 "Listening" 3 "Sleep_Pending" 4 "Sleep_Active" 5 "ERROR" ;
VAL_ 1434 PDU_OD_CAN2_autoErrorReset 0 "Disabled" 1 "Enabled" ;
VAL_ 1434 PDU_OD_CAN2_lastErrorCode 0 "No Error" 1 "Stuff Error" 2 "Form Error" 3 "Ack Error" 4 "Bit recessive Error" 5 "Bit dominant Error" 6 "CRC Error" ;
VAL_ 1434 PDU_OD_CAN1_ErrorStatus 0 "Ok" 1 "Warn" 2 "Error Passive" 3 "Bus Off" ;
VAL_ 1434 PDU_OD_CAN1_Status 0 "Reset" 1 "Ready" 2 "Listening" 3 "Sleep_Pending" 4 "Sleep_Active" 5 "ERROR" ;
VAL_ 1434 PDU_OD_CAN1_autoErrorReset 0 "Disabled" 1 "Enabled" ;
VAL_ 1434 PDU_OD_CAN1_lastErrorCode 0 "No Error" 1 "Stuff Error" 2 "Form Error" 3 "Ack Error" 4 "Bit recessive Error" 5 "Bit dominant Error" 6 "CRC Error" ;
VAL_ 1434 PDU_OD_SendOdOnBootup 0 "Disabled" 1 "Enabled" ;
VAL_ 1434 PDU_OD_NodeStatus 0 "Bootup" 4 "Stopped" 5 "Operational" 127 "Pre-Operational" 128 "Reset" ;
VAL_ 1434 PDU_SDO_RespCode 5 "ERR: Out of range" 4 "ERR: No access in this state" 3 "ERR: Read only object" 2 "ERR: Write only object" 1 "ERR: Non existing object" 0 "OK" ;
VAL_ 1434 PDU_SDO_ID 0 "Reserved" 1 "NodeID" 2 "NodeStatus" 3 "ProtocolVersion" 4 "StackVersion" 5 "DbcVersion" 16 "HeartbeatInterval" 32 "SendOdOnBootup" 33 "OdEntrySendInterval" 1040 "CpuUsage" 1041 "MemFree" 1042 "BoardTemp" 1043 "InputVoltage" 1044 "runtime" 1045 "SdcIn" 1046 "SdcOut" 1056 "ChipUID1" 1057 "ChipUID2" 1072 "BuildDate" 1073 "BuildTime" 1104 "CAN1_TxErrCnt" 1105 "CAN1_RxErrCnt" 1106 "CAN1_lastErrorCode" 1107 "CAN1_autoErrorReset" 1108 "CAN1_Baudrate" 1110 "CAN1_Status" 1111 "CAN1_DiscardedTxMessages" 1112 "CAN1_ErrorStatus" 1113 "CAN1_DelayedTxMessages" 1120 "CAN2_TxErrCnt" 1121 "CAN2_RxErrCnt" 1122 "CAN2_lastErrorCode" 1123 "CAN2_autoErrorReset" 1124 "CAN2_Baudrate" 1126 "CAN2_Status" 1127 "CAN2_DiscardedTxMessages" 1128 "CAN2_ErrorStatus" 1129 "CAN2_DelayedTxMessages" 2048 "batterVoltageLow" 2049 "batterVoltageCritical" 2050 "overTempWarn" 2051 "overTempCritical" 2128 "batteryOvercurrent" 2304 "currentReadInterval" 2305 "statusSendInterval" 2306 "watchdogTimeout" 2560 "projectXXEnabled" 2562 "LedCommands" 2816 "CoolingPumpEnabled" ;
VAL_ 1498 PDU_OD_CoolingPumpEnabled 0 "Disable" 1 "Enable" ;
VAL_ 1498 PDU_OD_LedCommands 0 "None" 1 "whipeanimation" 2 "mugreenanimation" 3 "rainbowanimation" 4 "flashlights" 5 "snakeanimation" 6 "blinkpink" 7 "multiwhipe" 8 "Emergency" ;
VAL_ 1498 PDU_OD_projectXXEnabled 0 "Disable" 1 "Enable" ;
VAL_ 1498 PDU_OD_CAN2_ErrorStatus 0 "Ok" 1 "Warn" 2 "Error Passive" 3 "Bus Off" ;
VAL_ 1498 PDU_OD_CAN2_Status 0 "Reset" 1 "Ready" 2 "Listening" 3 "Sleep_Pending" 4 "Sleep_Active" 5 "ERROR" ;
VAL_ 1498 PDU_OD_CAN2_autoErrorReset 0 "Disabled" 1 "Enabled" ;
VAL_ 1498 PDU_OD_CAN2_lastErrorCode 0 "No Error" 1 "Stuff Error" 2 "Form Error" 3 "Ack Error" 4 "Bit recessive Error" 5 "Bit dominant Error" 6 "CRC Error" ;
VAL_ 1498 PDU_OD_CAN1_ErrorStatus 0 "Ok" 1 "Warn" 2 "Error Passive" 3 "Bus Off" ;
VAL_ 1498 PDU_OD_CAN1_Status 0 "Reset" 1 "Ready" 2 "Listening" 3 "Sleep_Pending" 4 "Sleep_Active" 5 "ERROR" ;
VAL_ 1498 PDU_OD_CAN1_autoErrorReset 0 "Disabled" 1 "Enabled" ;
VAL_ 1498 PDU_OD_CAN1_lastErrorCode 0 "No Error" 1 "Stuff Error" 2 "Form Error" 3 "Ack Error" 4 "Bit recessive Error" 5 "Bit dominant Error" 6 "CRC Error" ;
VAL_ 1498 PDU_OD_SendOdOnBootup 0 "Disabled" 1 "Enabled" ;
VAL_ 1498 PDU_OD_NodeStatus 0 "Bootup" 4 "Stopped" 5 "Operational" 127 "Pre-Operational" 128 "Reset" ;
VAL_ 1498 PDU_SDO_ID 0 "Reserved" 1 "NodeID" 2 "NodeStatus" 3 "ProtocolVersion" 4 "StackVersion" 5 "DbcVersion" 16 "HeartbeatInterval" 32 "SendOdOnBootup" 33 "OdEntrySendInterval" 1040 "CpuUsage" 1041 "MemFree" 1042 "BoardTemp" 1043 "InputVoltage" 1044 "runtime" 1045 "SdcIn" 1046 "SdcOut" 1056 "ChipUID1" 1057 "ChipUID2" 1072 "BuildDate" 1073 "BuildTime" 1104 "CAN1_TxErrCnt" 1105 "CAN1_RxErrCnt" 1106 "CAN1_lastErrorCode" 1107 "CAN1_autoErrorReset" 1108 "CAN1_Baudrate" 1110 "CAN1_Status" 1111 "CAN1_DiscardedTxMessages" 1112 "CAN1_ErrorStatus" 1113 "CAN1_DelayedTxMessages" 1120 "CAN2_TxErrCnt" 1121 "CAN2_RxErrCnt" 1122 "CAN2_lastErrorCode" 1123 "CAN2_autoErrorReset" 1124 "CAN2_Baudrate" 1126 "CAN2_Status" 1127 "CAN2_DiscardedTxMessages" 1128 "CAN2_ErrorStatus" 1129 "CAN2_DelayedTxMessages" 2048 "batterVoltageLow" 2049 "batterVoltageCritical" 2050 "overTempWarn" 2051 "overTempCritical" 2128 "batteryOvercurrent" 2304 "currentReadInterval" 2305 "statusSendInterval" 2306 "watchdogTimeout" 2560 "projectXXEnabled" 2562 "LedCommands" 2816 "CoolingPumpEnabled" ;
VAL_ 1562 PDU_SDO_ID 0 "Reserved" 1 "NodeID" 2 "NodeStatus" 3 "ProtocolVersion" 4 "StackVersion" 5 "DbcVersion" 16 "HeartbeatInterval" 32 "SendOdOnBootup" 33 "OdEntrySendInterval" 1040 "CpuUsage" 1041 "MemFree" 1042 "BoardTemp" 1043 "InputVoltage" 1044 "runtime" 1045 "SdcIn" 1046 "SdcOut" 1056 "ChipUID1" 1057 "ChipUID2" 1072 "BuildDate" 1073 "BuildTime" 1104 "CAN1_TxErrCnt" 1105 "CAN1_RxErrCnt" 1106 "CAN1_lastErrorCode" 1107 "CAN1_autoErrorReset" 1108 "CAN1_Baudrate" 1110 "CAN1_Status" 1111 "CAN1_DiscardedTxMessages" 1112 "CAN1_ErrorStatus" 1113 "CAN1_DelayedTxMessages" 1120 "CAN2_TxErrCnt" 1121 "CAN2_RxErrCnt" 1122 "CAN2_lastErrorCode" 1123 "CAN2_autoErrorReset" 1124 "CAN2_Baudrate" 1126 "CAN2_Status" 1127 "CAN2_DiscardedTxMessages" 1128 "CAN2_ErrorStatus" 1129 "CAN2_DelayedTxMessages" 2048 "batterVoltageLow" 2049 "batterVoltageCritical" 2050 "overTempWarn" 2051 "overTempCritical" 2128 "batteryOvercurrent" 2304 "currentReadInterval" 2305 "statusSendInterval" 2306 "watchdogTimeout" 2560 "projectXXEnabled" 2562 "LedCommands" 2816 "CoolingPumpEnabled" ;
VAL_ 1818 PDU_NodeState 0 "Bootup" 4 "Stopped" 5 "Operational" 127 "Pre-Operational" ;
VAL_ 138 HVCU_E19_ChargingModeError 0 "Ok" 1 "ERR" ;
VAL_ 138 HVCU_E18_SDCSwitchError 0 "Ok" 1 "ERR" ;
VAL_ 138 HVCU_E17_ControlMessageTimeout 0 "Ok" 1 "ERR" ;
VAL_ 138 HVCU_E16_NoEnable 0 "Ok" 1 "ERR" ;
VAL_ 138 HVCU_E15_SDCOpen 0 "Ok" 1 "ERR" ;
VAL_ 138 HVCU_E14_HVMPError 0 "Ok" 1 "ERR" ;
VAL_ 138 HVCU_E13_BIR4Error 0 "Ok" 1 "ERR" ;
VAL_ 138 HVCU_E12_BIR3Error 0 "Ok" 1 "ERR" ;
VAL_ 138 HVCU_E11_BIR2Error 0 "Ok" 1 "ERR" ;
VAL_ 138 HVCU_E10_BIR1Error 0 "Ok" 1 "ERR" ;
VAL_ 138 HVCU_E9_HVSLError 0 "Ok" 1 "ERR" ;
VAL_ 138 HVCU_E8_VoltageMeasuring 0 "Ok" 1 "ERR" ;
VAL_ 138 HVCU_E7_BALError 0 "Ok" 1 "ERR" ;
VAL_ 138 HVCU_E6_DischargeError 0 "Ok" 1 "ERR" ;
VAL_ 138 HVCU_E5_DischargeTimeout 0 "Ok" 1 "ERR" ;
VAL_ 138 HVCU_E4_BMSPermissionMissing 0 "Ok" 1 "ERR" ;
VAL_ 138 HVCU_E3_PrechargeError 0 "Ok" 1 "ERR" ;
VAL_ 138 HVCU_E2_BMSError 0 "Ok" 1 "ERR" ;
VAL_ 138 HVCU_E1_IMDError 0 "Ok" 1 "ERR" ;
VAL_ 138 HVCU_E0_OtherError 0 "Ok" 1 "ERR" ;
VAL_ 138 HVCU_W8_ChargingMode 0 "Ok" 1 "WARN" ;
VAL_ 138 HVCU_W7_IsolationResistanceLow 0 "Ok" 1 "WARN" ;
VAL_ 138 HVCU_W6_Bir4On 0 "Ok" 1 "WARN" ;
VAL_ 138 HVCU_W5_Bir3On 0 "Ok" 1 "WARN" ;
VAL_ 138 HVCU_W4_Bir2On 0 "Ok" 1 "WARN" ;
VAL_ 138 HVCU_W3_Bir1On 0 "Ok" 1 "WARN" ;
VAL_ 138 HVCU_W2_PreChargeOn 0 "Ok" 1 "WARN" ;
VAL_ 138 HVCU_W1_HighVoltage 0 "Ok" 1 "WARN" ;
VAL_ 138 HVCU_W0_OtherWarning 0 "Ok" 1 "WARN" ;
VAL_ 394 HVCU_TX_Enabled 1 "Enabled" 0 "Disabled" ;
VAL_ 394 HVCU_TX_ErrorFlag 1 "Error" 0 "No Error" ;
VAL_ 394 HVCU_TX_Status 4 "Error" 3 "Shutdown" 2 "Startup" 1 "Activated" 0 "Deactivated" ;
VAL_ 394 HVCU_TX_InternalStatus 7 "Error" 6 "Disable SDC" 5 "Discharging" 4 "Active" 3 "Precharging" 2 "Enable SDC" 1 "Idle" 0 "Startup" ;
VAL_ 458 HVCU_RX_Charging 1 "Charging" 0 "Not Charging" ;
VAL_ 458 HVCU_RX_ErrorReset 1 "Reset" 0 "No Reset" ;
VAL_ 458 HVCU_RX_Activate 1 "Activate" 0 "Deactivate" ;
VAL_ 458 HVCU_RX_Enable 1 "Enable" 0 "Disable" ;
VAL_ 1418 HVCU_OD_CAN2_ErrorStatus 0 "Ok" 1 "Warn" 2 "Error Passive" 3 "Bus Off" ;
VAL_ 1418 HVCU_OD_CAN2_Status 0 "Reset" 1 "Ready" 2 "Listening" 3 "Sleep_Pending" 4 "Sleep_Active" 5 "ERROR" ;
VAL_ 1418 HVCU_OD_CAN2_autoErrorReset 0 "Disabled" 1 "Enabled" ;
VAL_ 1418 HVCU_OD_CAN2_lastErrorCode 0 "No Error" 1 "Stuff Error" 2 "Form Error" 3 "Ack Error" 4 "Bit recessive Error" 5 "Bit dominant Error" 6 "CRC Error" ;
VAL_ 1418 HVCU_OD_CAN1_ErrorStatus 0 "Ok" 1 "Warn" 2 "Error Passive" 3 "Bus Off" ;
VAL_ 1418 HVCU_OD_CAN1_Status 0 "Reset" 1 "Ready" 2 "Listening" 3 "Sleep_Pending" 4 "Sleep_Active" 5 "ERROR" ;
VAL_ 1418 HVCU_OD_CAN1_autoErrorReset 0 "Disabled" 1 "Enabled" ;
VAL_ 1418 HVCU_OD_CAN1_lastErrorCode 0 "No Error" 1 "Stuff Error" 2 "Form Error" 3 "Ack Error" 4 "Bit recessive Error" 5 "Bit dominant Error" 6 "CRC Error" ;
VAL_ 1418 HVCU_OD_SendOdOnBootup 0 "Disabled" 1 "Enabled" ;
VAL_ 1418 HVCU_OD_NodeStatus 0 "Bootup" 4 "Stopped" 5 "Operational" 127 "Pre-Operational" 128 "Reset" ;
VAL_ 1418 HVCU_SDO_RespCode 5 "ERR: Out of range" 4 "ERR: No access in this state" 3 "ERR: Read only object" 2 "ERR: Write only object" 1 "ERR: Non existing object" 0 "OK" ;
VAL_ 1418 HVCU_SDO_ID 0 "Reserved" 1 "NodeID" 2 "NodeStatus" 3 "ProtocolVersion" 4 "StackVersion" 5 "DbcVersion" 16 "HeartbeatInterval" 32 "SendOdOnBootup" 33 "OdEntrySendInterval" 1040 "CpuUsage" 1041 "MemFree" 1042 "BoardTemp" 1043 "InputVoltage" 1044 "runtime" 1045 "SdcIn" 1046 "SdcOut" 1056 "ChipUID1" 1057 "ChipUID2" 1072 "BuildDate" 1073 "BuildTime" 1104 "CAN1_TxErrCnt" 1105 "CAN1_RxErrCnt" 1106 "CAN1_lastErrorCode" 1107 "CAN1_autoErrorReset" 1108 "CAN1_Baudrate" 1110 "CAN1_Status" 1111 "CAN1_DiscardedTxMessages" 1112 "CAN1_ErrorStatus" 1113 "CAN1_DelayedTxMessages" 1120 "CAN2_TxErrCnt" 1121 "CAN2_RxErrCnt" 1122 "CAN2_lastErrorCode" 1123 "CAN2_autoErrorReset" 1124 "CAN2_Baudrate" 1126 "CAN2_Status" 1127 "CAN2_DiscardedTxMessages" 1128 "CAN2_ErrorStatus" 1129 "CAN2_DelayedTxMessages" ;
VAL_ 1482 HVCU_OD_CAN2_ErrorStatus 0 "Ok" 1 "Warn" 2 "Error Passive" 3 "Bus Off" ;
VAL_ 1482 HVCU_OD_CAN2_Status 0 "Reset" 1 "Ready" 2 "Listening" 3 "Sleep_Pending" 4 "Sleep_Active" 5 "ERROR" ;
VAL_ 1482 HVCU_OD_CAN2_autoErrorReset 0 "Disabled" 1 "Enabled" ;
VAL_ 1482 HVCU_OD_CAN2_lastErrorCode 0 "No Error" 1 "Stuff Error" 2 "Form Error" 3 "Ack Error" 4 "Bit recessive Error" 5 "Bit dominant Error" 6 "CRC Error" ;
VAL_ 1482 HVCU_OD_CAN1_ErrorStatus 0 "Ok" 1 "Warn" 2 "Error Passive" 3 "Bus Off" ;
VAL_ 1482 HVCU_OD_CAN1_Status 0 "Reset" 1 "Ready" 2 "Listening" 3 "Sleep_Pending" 4 "Sleep_Active" 5 "ERROR" ;
VAL_ 1482 HVCU_OD_CAN1_autoErrorReset 0 "Disabled" 1 "Enabled" ;
VAL_ 1482 HVCU_OD_CAN1_lastErrorCode 0 "No Error" 1 "Stuff Error" 2 "Form Error" 3 "Ack Error" 4 "Bit recessive Error" 5 "Bit dominant Error" 6 "CRC Error" ;
VAL_ 1482 HVCU_OD_SendOdOnBootup 0 "Disabled" 1 "Enabled" ;
VAL_ 1482 HVCU_OD_NodeStatus 0 "Bootup" 4 "Stopped" 5 "Operational" 127 "Pre-Operational" 128 "Reset" ;
VAL_ 1482 HVCU_SDO_ID 0 "Reserved" 1 "NodeID" 2 "NodeStatus" 3 "ProtocolVersion" 4 "StackVersion" 5 "DbcVersion" 16 "HeartbeatInterval" 32 "SendOdOnBootup" 33 "OdEntrySendInterval" 1040 "CpuUsage" 1041 "MemFree" 1042 "BoardTemp" 1043 "InputVoltage" 1044 "runtime" 1045 "SdcIn" 1046 "SdcOut" 1056 "ChipUID1" 1057 "ChipUID2" 1072 "BuildDate" 1073 "BuildTime" 1104 "CAN1_TxErrCnt" 1105 "CAN1_RxErrCnt" 1106 "CAN1_lastErrorCode" 1107 "CAN1_autoErrorReset" 1108 "CAN1_Baudrate" 1110 "CAN1_Status" 1111 "CAN1_DiscardedTxMessages" 1112 "CAN1_ErrorStatus" 1113 "CAN1_DelayedTxMessages" 1120 "CAN2_TxErrCnt" 1121 "CAN2_RxErrCnt" 1122 "CAN2_lastErrorCode" 1123 "CAN2_autoErrorReset" 1124 "CAN2_Baudrate" 1126 "CAN2_Status" 1127 "CAN2_DiscardedTxMessages" 1128 "CAN2_ErrorStatus" 1129 "CAN2_DelayedTxMessages" ;
VAL_ 1546 HVCU_SDO_ID 0 "Reserved" 1 "NodeID" 2 "NodeStatus" 3 "ProtocolVersion" 4 "StackVersion" 5 "DbcVersion" 16 "HeartbeatInterval" 32 "SendOdOnBootup" 33 "OdEntrySendInterval" 1040 "CpuUsage" 1041 "MemFree" 1042 "BoardTemp" 1043 "InputVoltage" 1044 "runtime" 1045 "SdcIn" 1046 "SdcOut" 1056 "ChipUID1" 1057 "ChipUID2" 1072 "BuildDate" 1073 "BuildTime" 1104 "CAN1_TxErrCnt" 1105 "CAN1_RxErrCnt" 1106 "CAN1_lastErrorCode" 1107 "CAN1_autoErrorReset" 1108 "CAN1_Baudrate" 1110 "CAN1_Status" 1111 "CAN1_DiscardedTxMessages" 1112 "CAN1_ErrorStatus" 1113 "CAN1_DelayedTxMessages" 1120 "CAN2_TxErrCnt" 1121 "CAN2_RxErrCnt" 1122 "CAN2_lastErrorCode" 1123 "CAN2_autoErrorReset" 1124 "CAN2_Baudrate" 1126 "CAN2_Status" 1127 "CAN2_DiscardedTxMessages" 1128 "CAN2_ErrorStatus" 1129 "CAN2_DelayedTxMessages" ;
VAL_ 1802 HVCU_NodeState 0 "Bootup" 4 "Stopped" 5 "Operational" 127 "Pre-Operational" ;
VAL_ 153 HVTU_E0_OtherError 0 "Ok" 1 "ERR" ;
VAL_ 153 HVTU_W0_OtherWarning 0 "Ok" 1 "WARN" ;
VAL_ 1408 SCIMO_FSM_State_MOT2 7 "permanent fault" 6 "fault" 5 "active" 4 "system check" 3 "ready" 2 "disabled" 1 "initial fault" 0 "reset" ;
VAL_ 1392 SCIMO_FSM_State_MOT1 7 "permanent fault" 6 "fault" 5 "active" 4 "system check" 3 "ready" 2 "disabled" 1 "initial fault" 0 "reset" ;
VAL_ 1312 SCIMO_warnNum_MOT2 1002 "Version" 1001 "Parameter Version" 102 "Comm2" 60 "U_ZK zu gross" 53 "Kennfeld Grenze" 52 "Spannungsgrenze" 51 "Torque Change" 50 "Max Torque" 33 "Drehzahllimit" 32 "PowerMin" 31 "PowerMax" 30 "Genauigkeit" 20 "Comm1" 2 "Commutation succedded" 0 "kein Warning" 402 "Comm5" 401 "Comm5" 302 "Comm4" 301 "Comm4" 202 "Comm3" 201 "Comm3" 104 "Uebertemperatur" 101 "Comm2" 21 "Comm1" 19 "Comm1" 18 "Comm1" 17 "Comm1" 16 "Comm1" 15 "Comm1" 14 "Comm1" 13 "Comm1" 12 "Comm1" 11 "Comm1" 10 "Comm1" 1 "Comm" ;
VAL_ 1312 SCIMO_warnNum_MOT1 1002 "Version" 1001 "Parameter Version" 102 "Comm2" 60 "U_ZK zu gross" 53 "Kennfeld Grenze" 52 "Spannungsgrenze" 51 "Torque Change" 50 "Max Torque" 33 "Drehzahllimit" 32 "PowerMin" 31 "PowerMax" 30 "Genauigkeit" 20 "Comm1" 2 "Commutation succedded" 0 "kein Warning" 402 "Comm5" 401 "Comm5" 302 "Comm4" 301 "Comm4" 202 "Comm3" 201 "Comm3" 104 "Uebertemperatur" 101 "Comm2" 21 "Comm1" 19 "Comm1" 18 "Comm1" 17 "Comm1" 16 "Comm1" 15 "Comm1" 14 "Comm1" 13 "Comm1" 12 "Comm1" 11 "Comm1" 10 "Comm1" 1 "Comm" ;
VAL_ 1312 SCIMO_errNum_MOT2 101 "Phasenueberstrom 4 Sample" 7 "Version" 121 "Unterdrehzahl" 120 "Ueberdrehzahl" 110 "Encoderfehler" 104 "Uebertemperatur" 103 "Summenueberstrom" 102 "Phasenueberstrom" 26 "Watchdog" 24 "Motor Temp" 21 "U_ZK zu gross" 20 "U_ZK zu klein" 10 "Encoder Fehler" 9 "Pulslock Fehler" 6 "Commutation" 5 "PS error" 4 "PS watchdog" 3 "Versorgung" 2 "Interpoloator Fehler" 1 "Parameter Fehler" 0 "Kein Fehler aktiv" ;
VAL_ 1312 SCIMO_errNum_MOT1 101 "Phasenueberstrom 4 Sample" 7 "Version" 121 "Unterdrehzahl" 120 "Ueberdrehzahl" 110 "Encoderfehler" 104 "Uebertemperatur" 103 "Summenueberstrom" 102 "Phasenueberstrom" 26 "Watchdog" 24 "Motor Temp" 21 "U_ZK zu gross" 20 "U_ZK zu klein" 10 "Encoder Fehler" 9 "Pulslock Fehler" 6 "Commutation" 5 "PS error" 4 "PS watchdog" 3 "Versorgung" 2 "Interpoloator Fehler" 1 "Parameter Fehler" 0 "Kein Fehler aktiv" ;
VAL_ 2578776064 EMUS_OverallParams_ChargingStage 0 "OFF" 1 "ON" ;
VAL_ 2578776064 EMUS_OverallParams_DCDC_Control 0 "OFF" 1 "ON" ;
VAL_ 2578776064 EMUS_OverallParams_BatteryFan 0 "OFF" 1 "ON" ;
VAL_ 2578776064 EMUS_OverallParams_HeaterEnable 0 "OFF" 1 "ON" ;
VAL_ 2578776064 EMUS_OverallParams_ChargerEnable 0 "OFF" 1 "ON" ;
VAL_ 2578776064 EMUS_OverallParams_LeakageSensor 0 "OFF" 1 "ON" ;
VAL_ 2578776064 EMUS_OverallParams_FastCharge 0 "OFF" 1 "ON" ;
VAL_ 2578776064 EMUS_OverallParams_ChargerMains 0 "OFF" 1 "ON" ;
VAL_ 2578776064 EMUS_OverallParams_IgnitionKey 0 "OFF" 1 "ON" ;
VAL_ 2578777090 EMUS_LoginLevel 0 "Guest" 1 "User" 2 "Admin" ;
VAL_ 2578777092 EMUS_Statistics_DataType 0 "Statistics Value" 1 "Additional Value" 2 "Statistics Timestamp" ;
VAL_ 2578777092 EMUS_Statistics_Identifier 0 "Total Disharge" 1 "Total Charge" 2 "Total Discharge Energy" 3 "Total Charge Energy" 4 "Total Discharge Time" 5 "Total Charge Time" 6 "Total Distance" 7 "Master Clear Count" 8 "Max Discharge Current" 9 "Max Charge Current" 10 "Min Cell Voltage" 11 "Max Cell Voltage" 12 "Max Cell Voltage Difference" 13 "Min Pack Voltage" 14 "Max Pack Voltage" 15 "Min Cell Module Temperature" 16 "Max Cell Module Temperature" 17 "Max Cell Module Temperature Difference" 18 "BMS Starts Count" 19 "Under Voltage Protection Count" 20 "Over Voltage Protection Count" 21 "Discharge Over Current Protection Count" 22 "Charge Over Current Protection Count" 23 "Cell Module Over Heat Protection Count" 24 "Leakage Protection Count" 25 "No Cell Communication Protection Count" 26 "Low Voltage Power Reduction Count" 27 "High Current Power Reduction Count" 28 "High Cell Module Temp Power Reduction Count" 29 "Charger Connected Count" 30 "Charger Disconnected Count" 31 "Pre Heat Stage Count" 32 "Pre Charge Stage Count" 33 "Main Charge Stage Count" 34 "Balancing Stage Count" 35 "Charging Finished Count" 36 "Charging Error Count" 37 "Charging Retry Count" 38 "Trips Count" 39 "Charge Restarts Count" 40 "Cell Over Heat Protection Count" 41 "High Cell Temperature Power Reduction Count" 42 "Min Cell Temperature" 43 "Max Cell Temperature Count" 44 "Max Cell Temperature Difference" ;
VAL_ 2578777093 EMUS_Events_Data_MSB 0 "No event" 1 "BMS Started" 2 "Lost Communication To Cells" 3 "Established Communication To Cells" 4 "Cells Voltage Critically Low" 5 "Critical Low Voltage Recovered" 6 "Cells Voltage Critically High " 7 "Critical High Voltage Recovered" 8 "Discharge Current Critically High" 9 "Discharge Critically High Current Recovered" 10 "Charge Current Critically High" 11 "Charge Critically High Current Recovered" 12 "Cell Module Temperature Critically High" 13 "Critical High Cell Module Temperature Recovered" 14 "Leakage Detected" 15 "Leakage Recovered" 16 "Warning: Low Voltage - Reducing Power" 17 "Power Reduction Due To Low Voltage Recovered" 18 "Warning: High Current - Reducing Power" 19 "Power Reduction Due To High Current Recovered" 20 "Warning: High Cell Module Temperature - Reducing Power" 21 "Power Reduction Due To High Cell Module Temperature Recovered" 22 "Charger Connected" 23 "Charger Disconnected" 24 "Started Pre-Heating Stage" 25 "Started Pre-Charging Stage" 26 "Started Main-Charging Stage" 27 "Started Balancing Stage" 28 "Charging Finished" 29 "Charging Error Occured" 30 "Retrying Charging" 31 "Restarting Charging" 32 "Cell Temperature Critically High" 33 "Critically High Cell Temperature Recovered" 34 "Warning: High Cell Temperature - Reducing Power" 35 "Power Reduction Due To High Cell Temperature Recovered" ;
VAL_ 2578777093 EMUS_Events_DataType 0 "Event Info " 1 "Event timestamp" ;
